VERSION ""

NS_ :

BS_:

BU_: PFAF_HS LVMPC_HS DCDC_HS AMP_HS VICM2_HS FICM_HS ARS_HS MCP_B_HS MCP_A_HS ICCM_OBD_HS SAS_HS ACCM_HS VLBS_HS EBCM_OBD_HS EDI_HS HPCC_HS VITM_OBD_HS PTAM_HS OBCM_HS VICM_HS HCP_HS FDCM_HS APPS_HS ICCM_HS EOCM_F_HS GPCM_HS FSCM_ITBC_HS SCM_HS ITBC_HS VCM_HS HMIM_HS FCP_HS VES_HS Dummy_HS MCP_C_HS RWS_HS ONSTAR_HS EPS_HS TestTool_HS MCP_HS BCP_HS ALC_HS AHL_AFL_HS SADS_HS EPB_HS FSCM_HS AFS_HS FCM_HS TCCM_HS RDCM_HS PTO_HS PCM_HS EBCM_HS ACC_HS BCM_HS TCM_HS ECM_HS

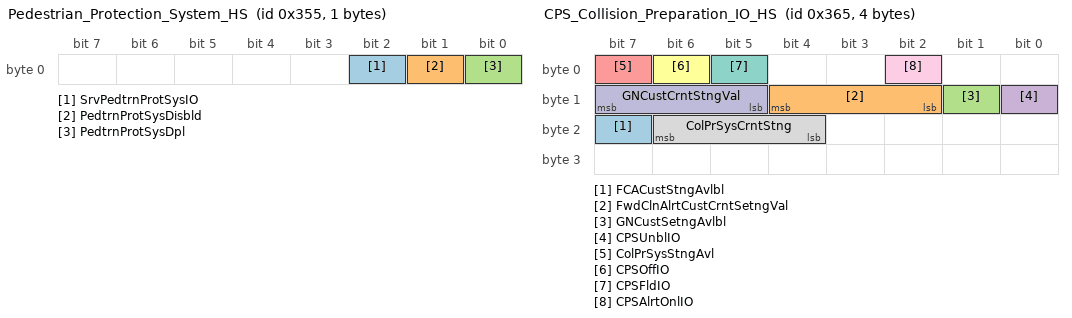
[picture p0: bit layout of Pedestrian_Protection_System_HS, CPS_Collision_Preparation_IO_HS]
BO_ 853 Pedestrian_Protection_System_HS: 1 APPS_HS
  SG_ SrvPedtrnProtSysIO: 2|1@0+ (1,0) [0|1] "" BCM_HS
  SG_ PedtrnProtSysDisbld: 1|1@0+ (1,0) [0|1] "" BCM_HS
  SG_ PedtrnProtSysDpl: 0|1@0+ (1,0) [0|1] "" BCM_HS

BO_ 869 CPS_Collision_Preparation_IO_HS: 4 EOCM_F_HS
  SG_ FCACustStngAvlbl: 23|1@0+ (1,0) [0|1] "" BCM_HS
  SG_ FwdClnAlrtCustCrntSetngVal: 12|3@0+ (1,0) [0|7] "" BCM_HS
  SG_ GNCustSetngAvlbl: 9|1@0+ (1,0) [0|1] "" BCM_HS
  SG_ CPSUnblIO: 8|1@0+ (1,0) [0|1] "" BCM_HS
  SG_ ColPrSysStngAvl: 7|1@0+ (1,0) [0|1] "" BCM_HS
  SG_ CPSOffIO: 6|1@0+ (1,0) [0|1] "" BCM_HS
  SG_ CPSFldIO: 5|1@0+ (1,0) [0|1] "" BCM_HS
  SG_ ColPrSysCrntStng: 22|3@0+ (1,0) [0|7] "" BCM_HS
  SG_ CPSAlrtOnlIO: 2|1@0+ (1,0) [0|1] "" BCM_HS
  SG_ GNCustCrntStngVal: 15|3@0+ (1,0) [0|7] "" BCM_HS

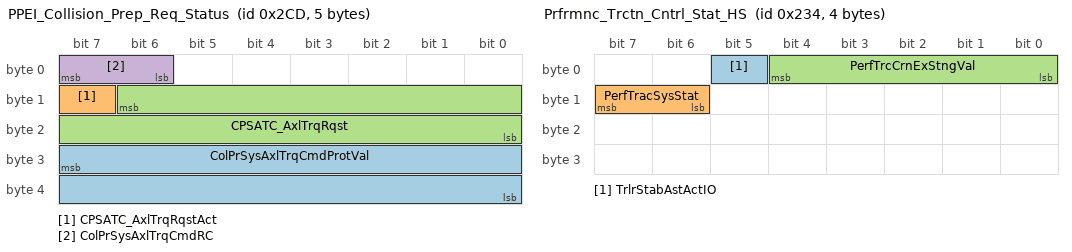
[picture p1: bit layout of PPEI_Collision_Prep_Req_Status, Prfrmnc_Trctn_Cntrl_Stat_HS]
BO_ 717 PPEI_Collision_Prep_Req_Status: 5 EOCM_F_HS
  SG_ ColPrSysAxlTrqCmdProtVal: 31|16@0+ (1,0) [0|65535] "" PCM_HS ECM_HS
  SG_ CPSATC_AxlTrqRqstAct: 15|1@0+ (1,0) [0|1] "" PCM_HS ECM_HS
  SG_ CPSATC_AxlTrqRqst: 14|15@0+ (2,-22534) [-22534|43000] "NM" PCM_HS ECM_HS
  SG_ ColPrSysAxlTrqCmdRC: 7|2@0+ (1,0) [0|3] "" PCM_HS ECM_HS

BO_ 568 A_12V_System_Status_HS: 1 VICM_HS
  SG_ a_12VSysVlt: 7|8@0+ (0.125,0) [0|31.874998] "volts" VICM2_HS ICCM_OBD_HS ICCM_HS FSCM_HS ACCM_HS

BO_ 564 Prfrmnc_Trctn_Cntrl_Stat_HS: 4 PTAM_HS
  SG_ TrlrStabAstActIO: 5|1@0+ (1,0) [0|1] "" BCM_HS
  SG_ PerfTracSysStat: 15|2@0+ (1,0) [0|3] "" EBCM_OBD_HS EBCM_HS
  SG_ PerfTrcCrnExStngVal: 4|5@0+ (1,0) [0|31] "" LVMPC_HS BCM_HS

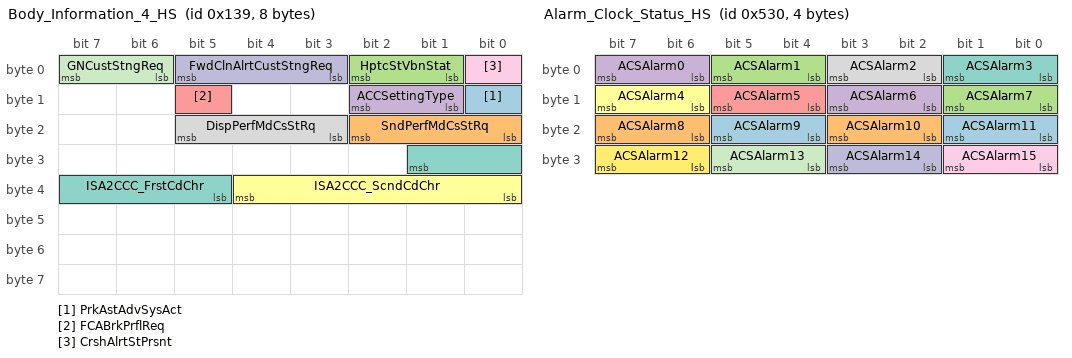
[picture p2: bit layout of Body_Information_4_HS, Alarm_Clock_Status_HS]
BO_ 313 Body_Information_4_HS: 8 BCM_HS
  SG_ PrkAstAdvSysAct: 8|1@0+ (1,0) [0|1] "" ACC_HS
  SG_ SndPerfMdCsStRq: 18|3@0+ (1,0) [0|7] "" EBCM_OBD_HS EBCM_HS
  SG_ HptcStVbnStat: 2|2@0+ (1,0) [0|3] "" ACC_HS
  SG_ ACCSettingType: 10|2@0+ (1,0) [0|3] "" ACC_HS
  SG_ FCABrkPrflReq: 13|1@0+ (1,0) [0|1] "" EBCM_OBD_HS EBCM_HS
  SG_ ISA2CCC_ScndCdChr: 36|5@0+ (1,0) [0|31] "" AHL_AFL_HS
  SG_ ISA2CCC_FrstCdChr: 25|5@0+ (1,0) [0|31] "" AHL_AFL_HS
  SG_ DispPerfMdCsStRq: 21|3@0+ (1,0) [0|7] "" EBCM_OBD_HS EBCM_HS
  SG_ CrshAlrtStPrsnt: 0|1@0+ (1,0) [0|1] "" EBCM_OBD_HS EBCM_HS ACC_HS
  SG_ FwdClnAlrtCustStngReq: 5|3@0+ (1,0) [0|7] "" EOCM_F_HS ACC_HS
  SG_ GNCustStngReq: 7|2@0+ (1,0) [0|3] "" EOCM_F_HS ACC_HS

BO_ 818 Front_Axle_General_Info_HS: 1 FDCM_HS
  SG_ FrntAxlTmpInhIO: 1|1@0+ (1,0) [0|1] "" BCM_HS
  SG_ FrAxlMalfIO: 0|1@0+ (1,0) [0|1] "" BCM_HS

BO_ 1328 Alarm_Clock_Status_HS: 4 BCM_HS
  SG_ ACSAlarm9: 21|2@0+ (1,0) [0|3] "" ICCM_OBD_HS ICCM_HS ALC_HS
  SG_ ACSAlarm8: 23|2@0+ (1,0) [0|3] "" ICCM_OBD_HS ICCM_HS ALC_HS
  SG_ ACSAlarm7: 9|2@0+ (1,0) [0|3] "" ICCM_OBD_HS ICCM_HS ALC_HS
  SG_ ACSAlarm6: 11|2@0+ (1,0) [0|3] "" ICCM_OBD_HS ICCM_HS ALC_HS
  SG_ ACSAlarm5: 13|2@0+ (1,0) [0|3] "" ICCM_OBD_HS ICCM_HS ALC_HS
  SG_ ACSAlarm4: 15|2@0+ (1,0) [0|3] "" ICCM_OBD_HS ICCM_HS ALC_HS
  SG_ ACSAlarm3: 1|2@0+ (1,0) [0|3] "" ICCM_OBD_HS ICCM_HS ALC_HS
  SG_ ACSAlarm2: 3|2@0+ (1,0) [0|3] "" ICCM_OBD_HS ICCM_HS ALC_HS
  SG_ ACSAlarm15: 25|2@0+ (1,0) [0|3] "" ICCM_OBD_HS ICCM_HS ALC_HS
  SG_ ACSAlarm14: 27|2@0+ (1,0) [0|3] "" ICCM_OBD_HS ICCM_HS ALC_HS
  SG_ ACSAlarm13: 29|2@0+ (1,0) [0|3] "" ICCM_OBD_HS ICCM_HS ALC_HS
  SG_ ACSAlarm12: 31|2@0+ (1,0) [0|3] "" ICCM_OBD_HS ICCM_HS ALC_HS
  SG_ ACSAlarm11: 17|2@0+ (1,0) [0|3] "" ICCM_OBD_HS ICCM_HS ALC_HS
  SG_ ACSAlarm10: 19|2@0+ (1,0) [0|3] "" ICCM_OBD_HS ICCM_HS ALC_HS
  SG_ ACSAlarm1: 5|2@0+ (1,0) [0|3] "" ICCM_OBD_HS ICCM_HS ALC_HS
  SG_ ACSAlarm0: 7|2@0+ (1,0) [0|3] "" ICCM_OBD_HS ICCM_HS ALC_HS

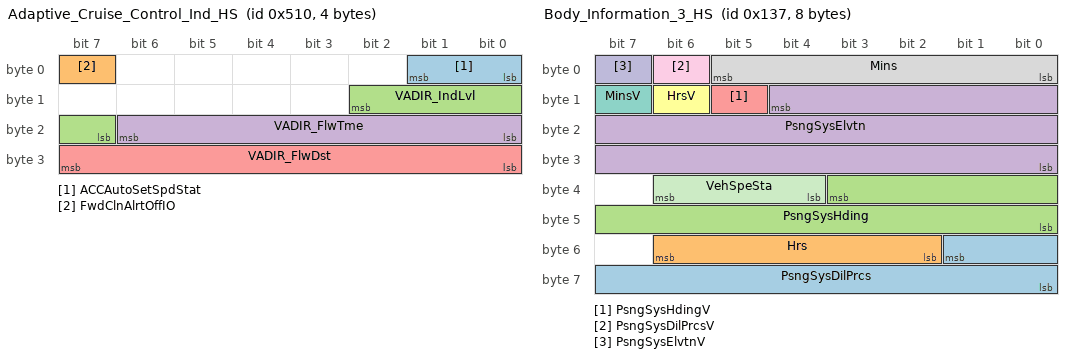
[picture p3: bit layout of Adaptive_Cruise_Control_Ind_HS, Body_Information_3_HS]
BO_ 1296 Adaptive_Cruise_Control_Ind_HS: 4 ACC_HS
  SG_ ACCAutoSetSpdStat: 1|2@0+ (1,0) [0|3] "" FCM_HS BCM_HS
  SG_ FwdClnAlrtOffIO: 7|1@0+ (1,0) [0|1] "" BCM_HS
  SG_ VADIR_IndLvl: 10|4@0+ (1,0) [0|15] "" BCM_HS
  SG_ VADIR_FlwTme: 22|7@0+ (0.1,0) [0|12.7] "s" BCM_HS
  SG_ VADIR_FlwDst: 31|8@0+ (1,0) [0|255] "m" BCM_HS

BO_ 311 Body_Information_3_HS: 8 BCM_HS
  SG_ PsngSysDilPrcs: 49|10@0+ (0.1,0) [0|102.3] "" ACC_HS
  SG_ Hrs: 54|5@0+ (1,0) [0|31] "h" ACC_HS
  SG_ PsngSysHding: 35|12@0+ (0.1,0) [0|409.5] "deg" ACC_HS
  SG_ PsngSysElvtn: 12|21@0+ (1,-100000) [-100000|1997151] "cm" ACC_HS
  SG_ PsngSysHdingV: 13|1@0+ (1,0) [0|1] "" ACC_HS
  SG_ HrsV: 14|1@0+ (1,0) [0|1] "" ACC_HS
  SG_ MinsV: 15|1@0+ (1,0) [0|1] "" ACC_HS
  SG_ Mins: 5|6@0+ (1,0) [0|63] "min" ACC_HS
  SG_ PsngSysDilPrcsV: 6|1@0+ (1,0) [0|1] "" ACC_HS
  SG_ PsngSysElvtnV: 7|1@0+ (1,0) [0|1] "" ACC_HS
  SG_ VehSpeSta: 38|3@0+ (1,0) [0|7] "" ACC_HS

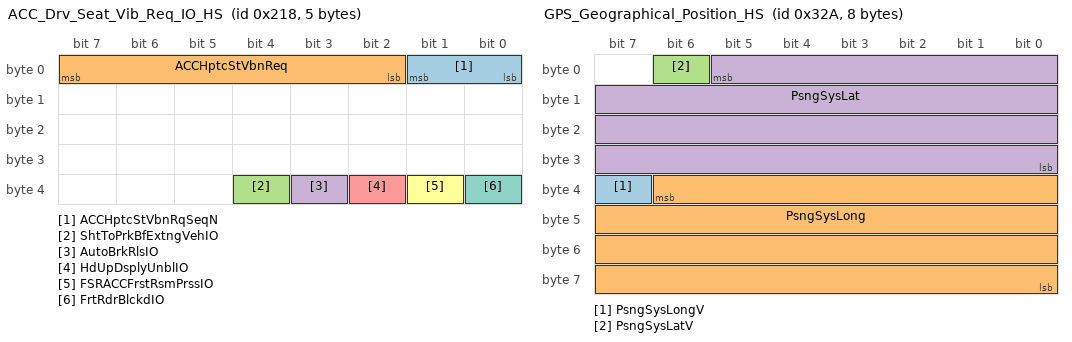
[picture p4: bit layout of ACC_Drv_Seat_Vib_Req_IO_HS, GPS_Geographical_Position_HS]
BO_ 536 ACC_Drv_Seat_Vib_Req_IO_HS: 5 ACC_HS
  SG_ ACCHptcStVbnRqSeqN: 1|2@0+ (1,0) [0|3] "" BCM_HS
  SG_ ACCHptcStVbnReq: 7|6@0+ (1,0) [0|63] "" BCM_HS
  SG_ ShtToPrkBfExtngVehIO: 36|1@0+ (1,0) [0|1] "" BCM_HS
  SG_ AutoBrkRlsIO: 35|1@0+ (1,0) [0|1] "" BCM_HS
  SG_ HdUpDsplyUnblIO: 34|1@0+ (1,0) [0|1] "" BCM_HS
  SG_ FSRACCFrstRsmPrssIO: 33|1@0+ (1,0) [0|1] "" BCM_HS
  SG_ FrtRdrBlckdIO: 32|1@0+ (1,0) [0|1] "" BCM_HS

BO_ 570 Fwd_Cln_Alrt_Drv_Seat_Vib_Req_HS: 1 ACC_HS
  SG_ FCAHptcStVbnRqSeqN: 1|2@0+ (1,0) [0|3] "" BCM_HS
  SG_ FCAHptcStVbnReq: 7|6@0+ (1,0) [0|63] "" BCM_HS

BO_ 810 GPS_Geographical_Position_HS: 8 BCM_HS
  SG_ PsngSysLongV: 39|1@0+ (1,0) [0|1] "" LVMPC_HS ACC_HS
  SG_ PsngSysLong: 38|31@0- (1,0) [-1.0737418e+09|1.0737418e+09] "ms arc" LVMPC_HS ACC_HS
  SG_ PsngSysLatV: 6|1@0+ (1,0) [0|1] "" LVMPC_HS ACC_HS
  SG_ PsngSysLat: 5|30@0- (1,0) [-5.3687091e+08|5.3687091e+08] "ms arc" LVMPC_HS ACC_HS

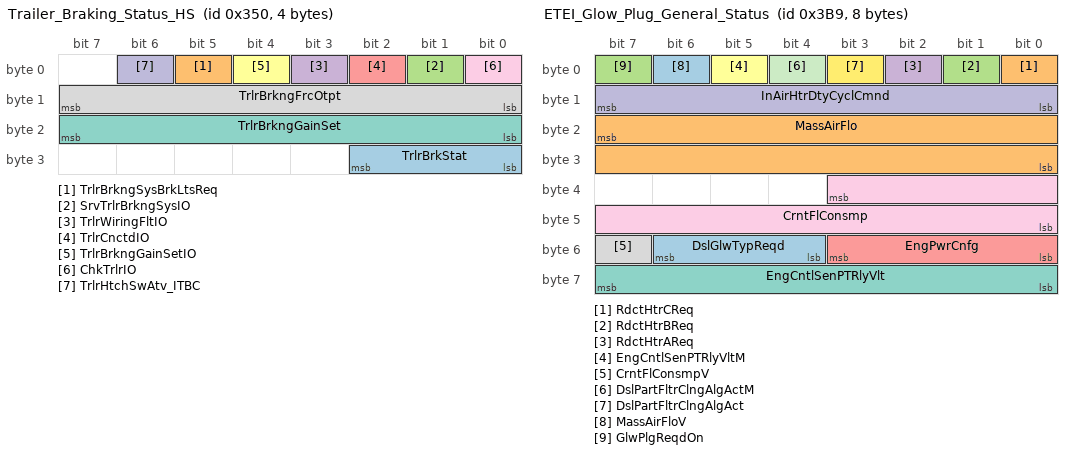
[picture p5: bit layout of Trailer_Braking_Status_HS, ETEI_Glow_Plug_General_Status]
BO_ 848 Trailer_Braking_Status_HS: 4 FSCM_ITBC_HS
  SG_ TrlrBrkStat: 26|3@0+ (1,0) [0|7] "" EBCM_OBD_HS EBCM_HS
  SG_ TrlrBrkngSysBrkLtsReq: 5|1@0+ (1,0) [0|1] "" BCM_HS
  SG_ SrvTrlrBrkngSysIO: 1|1@0+ (1,0) [0|1] "" BCM_HS
  SG_ TrlrWiringFltIO: 3|1@0+ (1,0) [0|1] "" BCM_HS
  SG_ TrlrCnctdIO: 2|1@0+ (1,0) [0|1] "" BCM_HS
  SG_ TrlrBrkngGainSetIO: 4|1@0+ (1,0) [0|1] "" BCM_HS
  SG_ TrlrBrkngGainSet: 23|8@0+ (0.39215702,0) [0|100.00004] "%" EBCM_OBD_HS EBCM_HS BCM_HS
  SG_ TrlrBrkngFrcOtpt: 15|8@0+ (0.39215702,0) [0|100.00004] "%" EBCM_OBD_HS EBCM_HS BCM_HS
  SG_ ChkTrlrIO: 0|1@0+ (1,0) [0|1] "" BCM_HS
  SG_ TrlrHtchSwAtv_ITBC: 6|1@0+ (1,0) [0|1] "" EOCM_F_HS ICCM_OBD_HS ICCM_HS ALC_HS SADS_HS BCM_HS

BO_ 953 ETEI_Glow_Plug_General_Status: 8 ECM_HS
  SG_ DslGlwTypReqd: 54|3@0+ (1,0) [0|7] "" GPCM_HS
  SG_ RdctHtrCReq: 0|1@0+ (1,0) [0|1] "" GPCM_HS
  SG_ RdctHtrBReq: 1|1@0+ (1,0) [0|1] "" GPCM_HS
  SG_ RdctHtrAReq: 2|1@0+ (1,0) [0|1] "" GPCM_HS
  SG_ EngPwrCnfg: 51|4@0+ (1,0) [0|15] "" GPCM_HS
  SG_ EngCntlSenPTRlyVltM: 5|1@0+ (1,0) [0|1] "" GPCM_HS
  SG_ EngCntlSenPTRlyVlt: 63|8@0+ (0.1,0) [0|25.5] "volts" GPCM_HS
  SG_ CrntFlConsmpV: 55|1@0+ (1,0) [0|1] "" GPCM_HS
  SG_ CrntFlConsmp: 35|12@0+ (0.050000004,0) [0|204.75] "mm3/stk" GPCM_HS
  SG_ InAirHtrDtyCyclCmnd: 15|8@0+ (0.39215702,0) [0|100.00004] "%" GPCM_HS
  SG_ DslPartFltrClngAlgActM: 4|1@0+ (1,0) [0|1] "" GPCM_HS
  SG_ DslPartFltrClngAlgAct: 3|1@0+ (1,0) [0|1] "" GPCM_HS
  SG_ MassAirFloV: 6|1@0+ (1,0) [0|1] "" GPCM_HS
  SG_ MassAirFlo: 23|16@0+ (0.010000001,0) [0|655.34998] "grams/s" GPCM_HS
  SG_ GlwPlgReqdOn: 7|1@0+ (1,0) [0|1] "" GPCM_HS

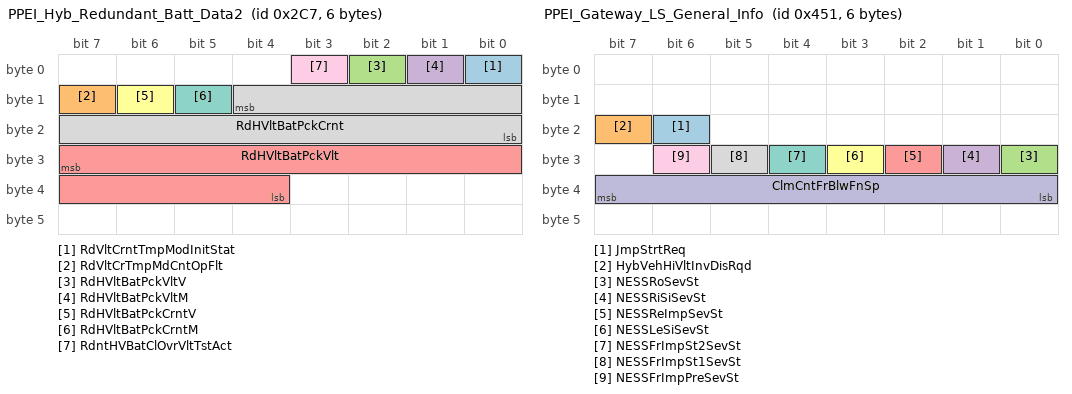
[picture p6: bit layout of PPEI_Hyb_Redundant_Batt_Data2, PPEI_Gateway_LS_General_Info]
BO_ 711 PPEI_Hyb_Redundant_Batt_Data2: 6 VITM_OBD_HS
  SG_ RdVltCrntTmpModInitStat: 0|1@0+ (1,0) [0|1] "" VICM_HS
  SG_ RdVltCrTmpMdCntOpFlt: 15|1@0+ (1,0) [0|1] "" VICM_HS
  SG_ RdHVltBatPckVltV: 2|1@0+ (1,0) [0|1] "" VICM_HS
  SG_ RdHVltBatPckVltM: 1|1@0+ (1,0) [0|1] "" VICM_HS
  SG_ RdHVltBatPckVlt: 31|12@0+ (0.125,0) [0|511.875] "V" VICM_HS
  SG_ RdHVltBatPckCrntV: 14|1@0+ (1,0) [0|1] "" VICM_HS
  SG_ RdHVltBatPckCrntM: 13|1@0+ (1,0) [0|1] "" VICM_HS
  SG_ RdHVltBatPckCrnt: 12|13@0- (0.15000001,0) [-614.40002|614.25] "A" VICM_HS
  SG_ RdntHVBatClOvrVltTstAct: 3|1@0+ (1,0) [0|1] "" VICM_HS

BO_ 1011 PPEI_Hybrid_General_Status_3: 2 BCP_HS

BO_ 304 Content_Theft_Sensor_Status_HS: 1 BCM_HS
  SG_ PedFrndlyAlrtCsStReq: 5|3@0+ (1,0) [0|7] "" PFAF_HS
  SG_ AlrmStat: 2|3@0+ (1,0) [0|7] "" VLBS_HS ICCM_OBD_HS ICCM_HS ALC_HS

BO_ 1105 PPEI_Gateway_LS_General_Info: 6 BCM_HS
  SG_ JmpStrtReq: 22|1@0+ (1,0) [0|1] "" BCP_HS
  SG_ HybVehHiVltInvDisRqd: 23|1@0+ (1,0) [0|1] "" BCP_HS
  SG_ NESSRoSevSt: 24|1@0+ (1,0) [0|1] "" ECM_HS BCP_HS
  SG_ NESSRiSiSevSt: 25|1@0+ (1,0) [0|1] "" ECM_HS BCP_HS
  SG_ NESSReImpSevSt: 26|1@0+ (1,0) [0|1] "" ECM_HS BCP_HS
  SG_ NESSLeSiSevSt: 27|1@0+ (1,0) [0|1] "" ECM_HS BCP_HS
  SG_ NESSFrImpSt2SevSt: 28|1@0+ (1,0) [0|1] "" ECM_HS BCP_HS
  SG_ NESSFrImpSt1SevSt: 29|1@0+ (1,0) [0|1] "" ECM_HS BCP_HS
  SG_ NESSFrImpPreSevSt: 30|1@0+ (1,0) [0|1] "" ECM_HS BCP_HS
  SG_ ClmCntFrBlwFnSp: 39|8@0+ (0.39215702,0) [0|100.00004] "%" EBCM_OBD_HS EBCM_HS BCP_HS

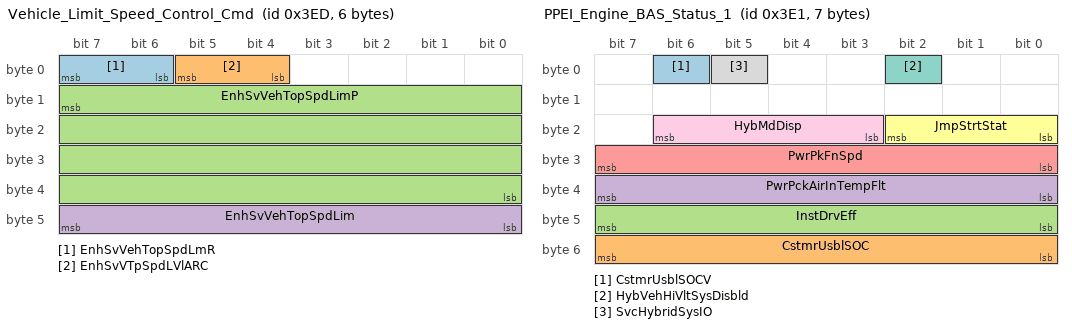
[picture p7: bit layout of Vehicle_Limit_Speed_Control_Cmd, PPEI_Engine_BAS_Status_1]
BO_ 1005 Vehicle_Limit_Speed_Control_Cmd: 6 ONSTAR_HS
  SG_ EnhSvVehTopSpdLmR: 7|2@0+ (1,0) [0|3] "" PCM_HS ECM_HS
  SG_ EnhSvVTpSpdLVlARC: 5|2@0+ (1,0) [0|3] "" PCM_HS ECM_HS
  SG_ EnhSvVehTopSpdLimP: 15|32@0+ (1,0) [0|-1] "" PCM_HS ECM_HS
  SG_ EnhSvVehTopSpdLim: 47|8@0+ (2,0) [0|510] "km / h" PCM_HS ECM_HS

BO_ 688 Starter_Generator_Status_3: 5 BCP_HS
  SG_ StrtrGenSpdV: 39|1@0+ (1,0) [0|1] "" PCM_HS ECM_HS EBCM_OBD_HS EBCM_HS
  SG_ StrtrGenSpd: 21|14@0+ (1,0) [0|16383] "rpm" PCM_HS ECM_HS EBCM_OBD_HS EBCM_HS

BO_ 993 PPEI_Engine_BAS_Status_1: 7 BCP_HS
  SG_ CstmrUsblSOCV: 6|1@0+ (1,0) [0|1] "" BCM_HS
  SG_ CstmrUsblSOC: 55|8@0+ (0.39216,0) [0|100.0008] "%" BCM_HS
  SG_ InstDrvEff: 47|8@0- (0.78740001,0) [-100.7872|99.999802] "%" BCM_HS
  SG_ PwrPckAirInTempFlt: 39|8@0+ (1,-40) [-40|215] "deg C" BCM_HS
  SG_ PwrPkFnSpd: 31|8@0+ (0.39215702,0) [0|100.00004] "%" BCM_HS
  SG_ JmpStrtStat: 18|3@0+ (1,0) [0|7] "" BCM_HS
  SG_ HybVehHiVltSysDisbld: 2|1@0+ (1,0) [0|1] "" FCP_HS ONSTAR_HS
  SG_ SvcHybridSysIO: 5|1@0+ (1,0) [0|1] "" BCM_HS
  SG_ HybMdDisp: 22|4@0+ (1,0) [0|15] "" BCM_HS

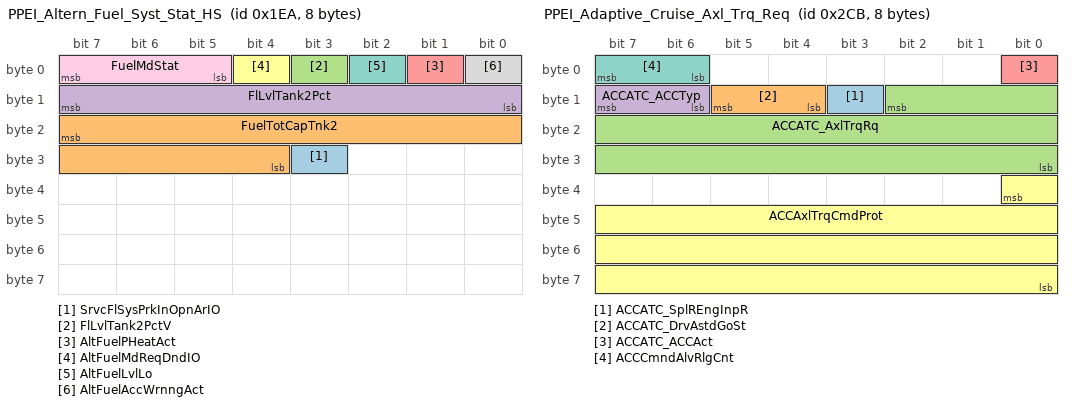
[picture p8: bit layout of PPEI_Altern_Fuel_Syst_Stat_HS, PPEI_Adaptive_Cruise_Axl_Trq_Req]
BO_ 490 PPEI_Altern_Fuel_Syst_Stat_HS: 8 ECM_HS
  SG_ SrvcFlSysPrkInOpnArIO: 27|1@0+ (1,0) [0|1] "" BCM_HS
  SG_ FuelTotCapTnk2: 23|12@0+ (0.125,0) [0|511.875] "liters" BCM_HS
  SG_ FlLvlTank2PctV: 3|1@0+ (1,0) [0|1] "" BCM_HS
  SG_ FlLvlTank2Pct: 15|8@0+ (0.39215702,0) [0|100.00004] "%" BCM_HS
  SG_ AltFuelPHeatAct: 1|1@0+ (1,0) [0|1] "" ECM_HS BCM_HS
  SG_ AltFuelMdReqDndIO: 4|1@0+ (1,0) [0|1] "" BCM_HS
  SG_ AltFuelLvlLo: 2|1@0+ (1,0) [0|1] "" BCM_HS ECM_HS
  SG_ AltFuelAccWrnngAct: 0|1@0+ (1,0) [0|1] "" BCM_HS
  SG_ FuelMdStat: 7|3@0+ (1,0) [0|7] "" ECM_HS BCM_HS

BO_ 431 PTEI_Trans_General_Status_2: 8 TCM_HS
  SG_ TransVehTopSpdLim: 63|8@0+ (2,0) [0|510] "km / h" PCM_HS ECM_HS
  SG_ TransMinVoltReq: 55|8@0+ (0.078430012,0) [0|19.999651] "volts" PCM_HS ECM_HS
  SG_ TDslPrtFltrIdlRgtnMdAtv: 6|1@0+ (1,0) [0|1] "" PCM_HS ECM_HS
  SG_ DrvlneTrqStabStat: 38|3@0+ (1,0) [0|7] "" PCM_HS ECM_HS
  SG_ TrnsTrqCnvCltCmdMdF: 19|1@0+ (1,0) [0|1] "" PCM_HS ECM_HS
  SG_ AutoTransGrSftDirectFl: 16|1@0+ (1,0) [0|1] "" PCM_HS ECM_HS
  SG_ AutoTransGrSftDirect: 18|2@0+ (1,0) [0|3] "" PCM_HS ECM_HS
  SG_ TrnsTrqCnvCltCmndMd: 22|3@0+ (1,0) [0|7] "" PCM_HS ECM_HS
  SG_ TrnsTrqCnvCltDsrSlp: 35|12@0- (1,0) [-2048|2047] "rpm" PCM_HS ECM_HS
  SG_ TrnsStWntrMdOvrd: 25|2@0+ (1,0) [0|3] "" PCM_HS ECM_HS
  SG_ TrnsStTwHaulMdOvrd: 27|2@0+ (1,0) [0|3] "" PCM_HS ECM_HS
  SG_ TrnsStSprtMdOvrd: 29|2@0+ (1,0) [0|3] "" PCM_HS ECM_HS
  SG_ TrnsStEconMdOvrd: 31|2@0+ (1,0) [0|3] "" PCM_HS ECM_HS
  SG_ TrnsInpCltchStat: 2|3@0+ (1,0) [0|7] "" PCM_HS ECM_HS
  SG_ TrnsAntcptdCrpTrqRRnV: 7|1@0+ (1,0) [0|1] "" PCM_HS ECM_HS
  SG_ TrnsAntcptdCrpTrqRRn: 15|8@0+ (0.5,0) [0|127.5] "Nm" PCM_HS ECM_HS
  SG_ TrnCltAdpAtv: 3|1@0+ (1,0) [0|1] "" PCM_HS ECM_HS
  SG_ TransCrnkPermsnStat: 5|1@0+ (1,0) [0|1] "" PCM_HS ECM_HS
  SG_ WrmUpShftPtrn: 4|1@0+ (1,0) [0|1] "" PCM_HS ECM_HS

BO_ 715 PPEI_Adaptive_Cruise_Axl_Trq_Req: 8 ACC_HS
  SG_ ACCATC_SplREngInpR: 11|1@0+ (1,0) [0|1] "" PCM_HS ECM_HS
  SG_ ACCATC_DrvAstdGoSt: 13|2@0+ (1,0) [0|3] "" PCM_HS ECM_HS
  SG_ ACCATC_AxlTrqRq: 10|19@0+ (0.125,-22534) [-22534|43001.875] "Nm" PCM_HS ECM_HS
  SG_ ACCATC_ACCTyp: 15|2@0+ (1,0) [0|3] "" PCM_HS ECM_HS
  SG_ ACCATC_ACCAct: 0|1@0+ (1,0) [0|1] "" PCM_HS ECM_HS
  SG_ ACCAxlTrqCmdProt: 32|25@0+ (1,0) [0|33554432] "" PCM_HS ECM_HS
  SG_ ACCCmndAlvRlgCnt: 7|2@0+ (1,0) [0|3] "" PCM_HS ECM_HS

BO_ 1267 PPEI_Powertrain_Config_Data_2: 1 ECM_HS
  SG_ VehMassNom: 7|8@0+ (20,500) [500|5600] "kg" EOCM_F_HS ACC_HS

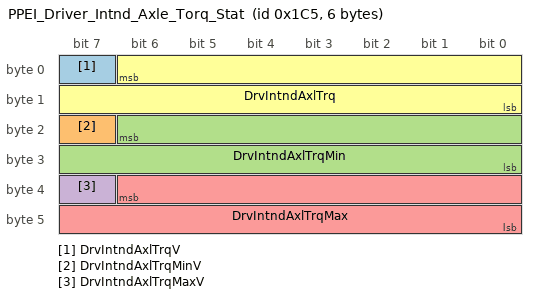
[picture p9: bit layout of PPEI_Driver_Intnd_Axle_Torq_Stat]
BO_ 453 PPEI_Driver_Intnd_Axle_Torq_Stat: 6 ECM_HS
  SG_ DrvIntndAxlTrqV: 7|1@0+ (1,0) [0|1] "" ICCM_OBD_HS ICCM_HS EBCM_OBD_HS EBCM_HS VICM_HS HCP_HS EOCM_F_HS ACC_HS
  SG_ DrvIntndAxlTrqMinV: 23|1@0+ (1,0) [0|1] "" EOCM_F_HS ACC_HS
  SG_ DrvIntndAxlTrqMin: 22|15@0+ (2,-22534) [-22534|43000] "Nm" EOCM_F_HS ACC_HS
  SG_ DrvIntndAxlTrqMaxV: 39|1@0+ (1,0) [0|1] "" EOCM_F_HS ACC_HS
  SG_ DrvIntndAxlTrqMax: 38|15@0+ (2,-22534) [-22534|43000] "Nm" EOCM_F_HS ACC_HS
  SG_ DrvIntndAxlTrq: 6|15@0+ (2,-22534) [-22534|43000] "Nm" ICCM_OBD_HS ICCM_HS EBCM_OBD_HS EBCM_HS VICM_HS HCP_HS EOCM_F_HS ACC_HS

BO_ 452 PPEI_Torque_Request_Status: 8 ECM_HS
  SG_ FSpRgACCSwADdPVal: 50|2@0+ (1,0) [0|3] "" EBCM_OBD_HS EBCM_HS
  SG_ FSpRgACCSwADdARC: 6|2@0+ (1,0) [0|3] "" EBCM_OBD_HS EBCM_HS
  SG_ FSpRgACCSwADd: 7|1@0+ (1,0) [0|1] "" EBCM_OBD_HS EBCM_HS ACC_HS
  SG_ AutBrkAccActPsStRC: 34|2@0+ (1,0) [0|3] "" EOCM_F_HS ACC_HS EBCM_OBD_HS EBCM_HS
  SG_ AutBrkAccActPsStPVal: 48|9@0+ (1,0) [0|511] "" EOCM_F_HS ACC_HS EBCM_OBD_HS EBCM_HS
  SG_ ABAAPS_AccPos: 47|8@0+ (0.39215702,0) [0|100.00004] "%" EBCM_OBD_HS EBCM_HS ACC_HS EOCM_F_HS
  SG_ ABAAPS_AccPosV: 32|1@0+ (1,0) [0|1] "" EBCM_OBD_HS EBCM_HS ACC_HS EOCM_F_HS
  SG_ ACCATCS_LmtgStat: 12|2@0+ (1,0) [0|3] "" EOCM_F_HS ACC_HS
  SG_ ACCATCS_RqStat: 15|3@0+ (1,0) [0|7] "" EOCM_F_HS ACC_HS
  SG_ RdLdNomAxlTrq: 10|19@0+ (0.125,-22534) [-22534|43001.875] "Nm" EOCM_F_HS ACC_HS
  SG_ AccPdlOvrrdAtvProtVal: 1|2@0+ (1,0) [0|3] "" EOCM_F_HS EBCM_OBD_HS EBCM_HS ACC_HS PTO_HS
  SG_ AccPdlOvrrdAtvARC: 3|2@0+ (1,0) [0|3] "" EOCM_F_HS EBCM_OBD_HS EBCM_HS ACC_HS PTO_HS
  SG_ AccPdlOvrrdAtv: 4|1@0+ (1,0) [0|1] "" BCM_HS EOCM_F_HS EBCM_OBD_HS EBCM_HS ACC_HS PTO_HS
  SG_ CPSATCS_ReqStatus: 37|3@0+ (1,0) [0|7] "" ACC_HS EOCM_F_HS
  SG_ CPSATCS_LmtngStatus: 39|2@0+ (1,0) [0|3] "" ACC_HS EOCM_F_HS
  SG_ RVBATCS_ReqStat: 53|3@0+ (1,0) [0|7] "" EOCM_F_HS
  SG_ RVBATCS_LmtngStat: 55|2@0+ (1,0) [0|3] "" EOCM_F_HS

BO_ 1905 DTC_Triggered_771: 7 FDCM_HS
  SG_ DTCI_DTCFaultType_771: 55|8@0+ (1,0) [0|255] "" HMIM_HS FCP_HS ONSTAR_HS
  SG_ DTCI_CodeSupported_771: 40|1@0+ (1,0) [0|1] "" HMIM_HS FCP_HS ONSTAR_HS
  SG_ DTCI_CurrentStatus_771: 41|1@0+ (1,0) [0|1] "" HMIM_HS FCP_HS ONSTAR_HS
  SG_ DTCI_TstNPsdCdClrdSt_771: 42|1@0+ (1,0) [0|1] "" HMIM_HS FCP_HS ONSTAR_HS
  SG_ DTCI_TstFldCdClrdStat_771: 43|1@0+ (1,0) [0|1] "" HMIM_HS FCP_HS ONSTAR_HS
  SG_ DTCI_HistStat_771: 44|1@0+ (1,0) [0|1] "" HMIM_HS FCP_HS ONSTAR_HS
  SG_ DTCI_TstNPsdPwrUpSt_771: 45|1@0+ (1,0) [0|1] "" HMIM_HS FCP_HS ONSTAR_HS
  SG_ DTCI_TstFldPwrUpSt_771: 46|1@0+ (1,0) [0|1] "" HMIM_HS FCP_HS ONSTAR_HS
  SG_ DTCI_WrnIndRqdSt_771: 47|1@0+ (1,0) [0|1] "" HMIM_HS FCP_HS ONSTAR_HS
  SG_ DTCI_DTCFailType_771: 39|8@0+ (1,0) [0|255] "" HMIM_HS FCP_HS ONSTAR_HS
  SG_ DTCI_DTCNumber_771: 23|16@0+ (1,0) [0|65535] "" HMIM_HS FCP_HS ONSTAR_HS
  SG_ DTCI_DTCSource_771: 15|8@0+ (1,0) [0|255] "" HMIM_HS FCP_HS ONSTAR_HS
  SG_ DTCI_DTCTriggered_771: 0|1@0+ (1,0) [0|1] "" HMIM_HS FCP_HS ONSTAR_HS
  SG_ DTCIUnused7_771: 1|1@0+ (1,0) [0|1] "" HMIM_HS FCP_HS ONSTAR_HS
  SG_ DTCIUnused6_771: 2|1@0+ (1,0) [0|1] "" HMIM_HS FCP_HS ONSTAR_HS
  SG_ DTCIUnused5_771: 3|1@0+ (1,0) [0|1] "" HMIM_HS FCP_HS ONSTAR_HS
  SG_ DTCIUnused4_771: 4|1@0+ (1,0) [0|1] "" HMIM_HS FCP_HS ONSTAR_HS
  SG_ DTCIUnused3_771: 5|1@0+ (1,0) [0|1] "" HMIM_HS FCP_HS ONSTAR_HS
  SG_ DTCIUnused2_771: 6|1@0+ (1,0) [0|1] "" HMIM_HS FCP_HS ONSTAR_HS
  SG_ DTCIUnused1_771: 7|1@0+ (1,0) [0|1] "" HMIM_HS FCP_HS ONSTAR_HS

BO_ 1935 DTC_Triggered_78F: 7 Dummy_HS
  SG_ DTCI_DTCSource_78F: 15|8@0+ (1,0) [0|255] "" HMIM_HS FCP_HS ONSTAR_HS
  SG_ DTCI_DTCTriggered_78F: 0|1@0+ (1,0) [0|1] "" HMIM_HS FCP_HS ONSTAR_HS
  SG_ DTCIUnused1_78F: 7|1@0+ (1,0) [0|1] "" HMIM_HS FCP_HS ONSTAR_HS
  SG_ DTCIUnused2_78F: 6|1@0+ (1,0) [0|1] "" HMIM_HS FCP_HS ONSTAR_HS
  SG_ DTCIUnused3_78F: 5|1@0+ (1,0) [0|1] "" HMIM_HS FCP_HS ONSTAR_HS
  SG_ DTCIUnused4_78F: 4|1@0+ (1,0) [0|1] "" HMIM_HS FCP_HS ONSTAR_HS
  SG_ DTCIUnused5_78F: 3|1@0+ (1,0) [0|1] "" HMIM_HS FCP_HS ONSTAR_HS
  SG_ DTCIUnused6_78F: 2|1@0+ (1,0) [0|1] "" HMIM_HS FCP_HS ONSTAR_HS
  SG_ DTCIUnused7_78F: 1|1@0+ (1,0) [0|1] "" HMIM_HS FCP_HS ONSTAR_HS
  SG_ DTCI_CodeSupported_78F: 40|1@0+ (1,0) [0|1] "" HMIM_HS FCP_HS ONSTAR_HS
  SG_ DTCI_CurrentStatus_78F: 41|1@0+ (1,0) [0|1] "" HMIM_HS FCP_HS ONSTAR_HS
  SG_ DTCI_DTCFaultType_78F: 55|8@0+ (1,0) [0|255] "" HMIM_HS FCP_HS ONSTAR_HS
  SG_ DTCI_TstFldCdClrdStat_78F: 43|1@0+ (1,0) [0|1] "" HMIM_HS FCP_HS ONSTAR_HS
  SG_ DTCI_TstNPsdCdClrdSt_78F: 42|1@0+ (1,0) [0|1] "" HMIM_HS FCP_HS ONSTAR_HS
  SG_ DTCI_HistStat_78F: 44|1@0+ (1,0) [0|1] "" HMIM_HS FCP_HS ONSTAR_HS
  SG_ DTCI_TstNPsdPwrUpSt_78F: 45|1@0+ (1,0) [0|1] "" HMIM_HS FCP_HS ONSTAR_HS
  SG_ DTCI_TstFldPwrUpSt_78F: 46|1@0+ (1,0) [0|1] "" HMIM_HS FCP_HS ONSTAR_HS
  SG_ DTCI_WrnIndRqdSt_78F: 47|1@0+ (1,0) [0|1] "" HMIM_HS FCP_HS ONSTAR_HS
  SG_ DTCI_DTCFailType_78F: 39|8@0+ (1,0) [0|255] "" HMIM_HS FCP_HS ONSTAR_HS
  SG_ DTCI_DTCNumber_78F: 23|16@0+ (1,0) [0|65535] "" HMIM_HS FCP_HS ONSTAR_HS

BO_ 1934 DTC_Triggered_78E: 7 Dummy_HS
  SG_ DTCI_CodeSupported_78E: 40|1@0+ (1,0) [0|1] "" HMIM_HS FCP_HS ONSTAR_HS
  SG_ DTCI_CurrentStatus_78E: 41|1@0+ (1,0) [0|1] "" HMIM_HS FCP_HS ONSTAR_HS
  SG_ DTCI_DTCFailType_78E: 39|8@0+ (1,0) [0|255] "" HMIM_HS FCP_HS ONSTAR_HS
  SG_ DTCI_DTCFaultType_78E: 55|8@0+ (1,0) [0|255] "" HMIM_HS FCP_HS ONSTAR_HS
  SG_ DTCI_DTCNumber_78E: 23|16@0+ (1,0) [0|65535] "" HMIM_HS FCP_HS ONSTAR_HS
  SG_ DTCI_DTCSource_78E: 15|8@0+ (1,0) [0|255] "" HMIM_HS FCP_HS ONSTAR_HS
  SG_ DTCI_DTCTriggered_78E: 0|1@0+ (1,0) [0|1] "" HMIM_HS FCP_HS ONSTAR_HS
  SG_ DTCI_HistStat_78E: 44|1@0+ (1,0) [0|1] "" HMIM_HS FCP_HS ONSTAR_HS
  SG_ DTCI_TstFldCdClrdStat_78E: 43|1@0+ (1,0) [0|1] "" HMIM_HS FCP_HS ONSTAR_HS
  SG_ DTCI_TstFldPwrUpSt_78E: 46|1@0+ (1,0) [0|1] "" HMIM_HS FCP_HS ONSTAR_HS
  SG_ DTCI_TstNPsdCdClrdSt_78E: 42|1@0+ (1,0) [0|1] "" HMIM_HS FCP_HS ONSTAR_HS
  SG_ DTCI_TstNPsdPwrUpSt_78E: 45|1@0+ (1,0) [0|1] "" HMIM_HS FCP_HS ONSTAR_HS
  SG_ DTCIUnused1_78E: 7|1@0+ (1,0) [0|1] "" HMIM_HS FCP_HS ONSTAR_HS
  SG_ DTCIUnused2_78E: 6|1@0+ (1,0) [0|1] "" HMIM_HS FCP_HS ONSTAR_HS
  SG_ DTCIUnused3_78E: 5|1@0+ (1,0) [0|1] "" HMIM_HS FCP_HS ONSTAR_HS
  SG_ DTCIUnused4_78E: 4|1@0+ (1,0) [0|1] "" HMIM_HS FCP_HS ONSTAR_HS
  SG_ DTCIUnused5_78E: 3|1@0+ (1,0) [0|1] "" HMIM_HS FCP_HS ONSTAR_HS
  SG_ DTCIUnused6_78E: 2|1@0+ (1,0) [0|1] "" HMIM_HS FCP_HS ONSTAR_HS
  SG_ DTCIUnused7_78E: 1|1@0+ (1,0) [0|1] "" HMIM_HS FCP_HS ONSTAR_HS
  SG_ DTCI_WrnIndRqdSt_78E: 47|1@0+ (1,0) [0|1] "" HMIM_HS FCP_HS ONSTAR_HS

BO_ 1933 DTC_Triggered_78D: 7 Dummy_HS
  SG_ DTCI_CodeSupported_78D: 40|1@0+ (1,0) [0|1] "" HMIM_HS FCP_HS ONSTAR_HS
  SG_ DTCI_CurrentStatus_78D: 41|1@0+ (1,0) [0|1] "" HMIM_HS FCP_HS ONSTAR_HS
  SG_ DTCI_DTCFailType_78D: 39|8@0+ (1,0) [0|255] "" HMIM_HS FCP_HS ONSTAR_HS
  SG_ DTCI_DTCFaultType_78D: 55|8@0+ (1,0) [0|255] "" HMIM_HS FCP_HS ONSTAR_HS
  SG_ DTCI_DTCNumber_78D: 23|16@0+ (1,0) [0|65535] "" HMIM_HS FCP_HS ONSTAR_HS
  SG_ DTCI_DTCSource_78D: 15|8@0+ (1,0) [0|255] "" HMIM_HS FCP_HS ONSTAR_HS
  SG_ DTCI_DTCTriggered_78D: 0|1@0+ (1,0) [0|1] "" HMIM_HS FCP_HS ONSTAR_HS
  SG_ DTCI_HistStat_78D: 44|1@0+ (1,0) [0|1] "" HMIM_HS FCP_HS ONSTAR_HS
  SG_ DTCI_TstFldCdClrdStat_78D: 43|1@0+ (1,0) [0|1] "" HMIM_HS FCP_HS ONSTAR_HS
  SG_ DTCI_TstFldPwrUpSt_78D: 46|1@0+ (1,0) [0|1] "" HMIM_HS FCP_HS ONSTAR_HS
  SG_ DTCI_TstNPsdCdClrdSt_78D: 42|1@0+ (1,0) [0|1] "" HMIM_HS FCP_HS ONSTAR_HS
  SG_ DTCI_TstNPsdPwrUpSt_78D: 45|1@0+ (1,0) [0|1] "" HMIM_HS FCP_HS ONSTAR_HS
  SG_ DTCIUnused1_78D: 7|1@0+ (1,0) [0|1] "" HMIM_HS FCP_HS ONSTAR_HS
  SG_ DTCIUnused2_78D: 6|1@0+ (1,0) [0|1] "" HMIM_HS FCP_HS ONSTAR_HS
  SG_ DTCIUnused3_78D: 5|1@0+ (1,0) [0|1] "" HMIM_HS FCP_HS ONSTAR_HS
  SG_ DTCIUnused4_78D: 4|1@0+ (1,0) [0|1] "" HMIM_HS FCP_HS ONSTAR_HS
  SG_ DTCIUnused5_78D: 3|1@0+ (1,0) [0|1] "" HMIM_HS FCP_HS ONSTAR_HS
  SG_ DTCIUnused6_78D: 2|1@0+ (1,0) [0|1] "" HMIM_HS FCP_HS ONSTAR_HS
  SG_ DTCIUnused7_78D: 1|1@0+ (1,0) [0|1] "" HMIM_HS FCP_HS ONSTAR_HS
  SG_ DTCI_WrnIndRqdSt_78D: 47|1@0+ (1,0) [0|1] "" HMIM_HS FCP_HS ONSTAR_HS

BO_ 1932 DTC_Triggered_78C: 7 Dummy_HS
  SG_ DTCI_CodeSupported_78C: 40|1@0+ (1,0) [0|1] "" HMIM_HS FCP_HS ONSTAR_HS
  SG_ DTCI_CurrentStatus_78C: 41|1@0+ (1,0) [0|1] "" HMIM_HS FCP_HS ONSTAR_HS
  SG_ DTCI_DTCFailType_78C: 39|8@0+ (1,0) [0|255] "" HMIM_HS FCP_HS ONSTAR_HS
  SG_ DTCI_DTCFaultType_78C: 55|8@0+ (1,0) [0|255] "" HMIM_HS FCP_HS ONSTAR_HS
  SG_ DTCI_DTCNumber_78C: 23|16@0+ (1,0) [0|65535] "" HMIM_HS FCP_HS ONSTAR_HS
  SG_ DTCI_DTCSource_78C: 15|8@0+ (1,0) [0|255] "" HMIM_HS FCP_HS ONSTAR_HS
  SG_ DTCI_DTCTriggered_78C: 0|1@0+ (1,0) [0|1] "" HMIM_HS FCP_HS ONSTAR_HS
  SG_ DTCI_HistStat_78C: 44|1@0+ (1,0) [0|1] "" HMIM_HS FCP_HS ONSTAR_HS
  SG_ DTCI_TstFldCdClrdStat_78C: 43|1@0+ (1,0) [0|1] "" HMIM_HS FCP_HS ONSTAR_HS
  SG_ DTCI_TstFldPwrUpSt_78C: 45|1@0+ (1,0) [0|1] "" HMIM_HS FCP_HS ONSTAR_HS
  SG_ DTCI_TstNPsdCdClrdSt_78C: 42|1@0+ (1,0) [0|1] "" HMIM_HS FCP_HS ONSTAR_HS
  SG_ DTCI_TstNPsdPwrUpSt_78C: 46|1@0+ (1,0) [0|1] "" HMIM_HS FCP_HS ONSTAR_HS
  SG_ DTCIUnused1_78C: 7|1@0+ (1,0) [0|1] "" HMIM_HS FCP_HS ONSTAR_HS
  SG_ DTCIUnused2_78C: 6|1@0+ (1,0) [0|1] "" HMIM_HS FCP_HS ONSTAR_HS
  SG_ DTCIUnused3_78C: 5|1@0+ (1,0) [0|1] "" HMIM_HS FCP_HS ONSTAR_HS
  SG_ DTCIUnused4_78C: 4|1@0+ (1,0) [0|1] "" HMIM_HS FCP_HS ONSTAR_HS
  SG_ DTCIUnused5_78C: 3|1@0+ (1,0) [0|1] "" HMIM_HS FCP_HS ONSTAR_HS
  SG_ DTCIUnused6_78C: 2|1@0+ (1,0) [0|1] "" HMIM_HS FCP_HS ONSTAR_HS
  SG_ DTCIUnused7_78C: 1|1@0+ (1,0) [0|1] "" HMIM_HS FCP_HS ONSTAR_HS
  SG_ DTCI_WrnIndRqdSt_78C: 47|1@0+ (1,0) [0|1] "" HMIM_HS FCP_HS ONSTAR_HS

BO_ 1931 DTC_Triggered_78B: 7 Dummy_HS
  SG_ DTCI_CodeSupported_78B: 40|1@0+ (1,0) [0|1] "" HMIM_HS FCP_HS ONSTAR_HS
  SG_ DTCI_CurrentStatus_78B: 41|1@0+ (1,0) [0|1] "" HMIM_HS FCP_HS ONSTAR_HS
  SG_ DTCI_DTCFailType_78B: 39|8@0+ (1,0) [0|255] "" HMIM_HS FCP_HS ONSTAR_HS
  SG_ DTCI_DTCFaultType_78B: 55|8@0+ (1,0) [0|255] "" HMIM_HS FCP_HS ONSTAR_HS
  SG_ DTCI_DTCNumber_78B: 23|16@0+ (1,0) [0|65535] "" HMIM_HS FCP_HS ONSTAR_HS
  SG_ DTCI_DTCSource_78B: 15|8@0+ (1,0) [0|255] "" HMIM_HS FCP_HS ONSTAR_HS
  SG_ DTCI_DTCTriggered_78B: 0|1@0+ (1,0) [0|1] "" HMIM_HS FCP_HS ONSTAR_HS
  SG_ DTCI_HistStat_78B: 44|1@0+ (1,0) [0|1] "" HMIM_HS FCP_HS ONSTAR_HS
  SG_ DTCI_TstFldCdClrdStat_78B: 43|1@0+ (1,0) [0|1] "" HMIM_HS FCP_HS ONSTAR_HS
  SG_ DTCI_TstFldPwrUpSt_78B: 46|1@0+ (1,0) [0|1] "" HMIM_HS FCP_HS ONSTAR_HS
  SG_ DTCI_TstNPsdCdClrdSt_78B: 42|1@0+ (1,0) [0|1] "" HMIM_HS FCP_HS ONSTAR_HS
  SG_ DTCI_TstNPsdPwrUpSt_78B: 45|1@0+ (1,0) [0|1] "" HMIM_HS FCP_HS ONSTAR_HS
  SG_ DTCIUnused1_78B: 7|1@0+ (1,0) [0|1] "" HMIM_HS FCP_HS ONSTAR_HS
  SG_ DTCIUnused2_78B: 6|1@0+ (1,0) [0|1] "" HMIM_HS FCP_HS ONSTAR_HS
  SG_ DTCIUnused3_78B: 5|1@0+ (1,0) [0|1] "" HMIM_HS FCP_HS ONSTAR_HS
  SG_ DTCIUnused4_78B: 4|1@0+ (1,0) [0|1] "" HMIM_HS FCP_HS ONSTAR_HS
  SG_ DTCIUnused5_78B: 3|1@0+ (1,0) [0|1] "" HMIM_HS FCP_HS ONSTAR_HS
  SG_ DTCIUnused6_78B: 2|1@0+ (1,0) [0|1] "" HMIM_HS FCP_HS ONSTAR_HS
  SG_ DTCIUnused7_78B: 1|1@0+ (1,0) [0|1] "" HMIM_HS FCP_HS ONSTAR_HS
  SG_ DTCI_WrnIndRqdSt_78B: 47|1@0+ (1,0) [0|1] "" HMIM_HS FCP_HS ONSTAR_HS

BO_ 1930 DTC_Triggered_78A: 7 EOCM_F_HS
  SG_ DTCI_CodeSupported_78A: 40|1@0+ (1,0) [0|1] "" HMIM_HS FCP_HS ONSTAR_HS
  SG_ DTCI_CurrentStatus_78A: 41|1@0+ (1,0) [0|1] "" HMIM_HS FCP_HS ONSTAR_HS
  SG_ DTCI_DTCFailType_78A: 39|8@0+ (1,0) [0|255] "" HMIM_HS FCP_HS ONSTAR_HS
  SG_ DTCI_DTCFaultType_78A: 55|8@0+ (1,0) [0|255] "" HMIM_HS FCP_HS ONSTAR_HS
  SG_ DTCI_DTCNumber_78A: 23|16@0+ (1,0) [0|65535] "" HMIM_HS FCP_HS ONSTAR_HS
  SG_ DTCI_DTCSource_78A: 15|8@0+ (1,0) [0|255] "" HMIM_HS FCP_HS ONSTAR_HS
  SG_ DTCI_DTCTriggered_78A: 0|1@0+ (1,0) [0|1] "" HMIM_HS FCP_HS ONSTAR_HS
  SG_ DTCI_HistStat_78A: 44|1@0+ (1,0) [0|1] "" HMIM_HS FCP_HS ONSTAR_HS
  SG_ DTCI_TstFldCdClrdStat_78A: 43|1@0+ (1,0) [0|1] "" HMIM_HS FCP_HS ONSTAR_HS
  SG_ DTCI_TstFldPwrUpSt_78A: 46|1@0+ (1,0) [0|1] "" HMIM_HS FCP_HS ONSTAR_HS
  SG_ DTCI_TstNPsdCdClrdSt_78A: 42|1@0+ (1,0) [0|1] "" HMIM_HS FCP_HS ONSTAR_HS
  SG_ DTCI_TstNPsdPwrUpSt_78A: 45|1@0+ (1,0) [0|1] "" HMIM_HS FCP_HS ONSTAR_HS
  SG_ DTCIUnused1_78A: 7|1@0+ (1,0) [0|1] "" HMIM_HS FCP_HS ONSTAR_HS
  SG_ DTCIUnused2_78A: 6|1@0+ (1,0) [0|1] "" HMIM_HS FCP_HS ONSTAR_HS
  SG_ DTCIUnused3_78A: 5|1@0+ (1,0) [0|1] "" HMIM_HS FCP_HS ONSTAR_HS
  SG_ DTCIUnused4_78A: 4|1@0+ (1,0) [0|1] "" HMIM_HS FCP_HS ONSTAR_HS
  SG_ DTCIUnused5_78A: 3|1@0+ (1,0) [0|1] "" HMIM_HS FCP_HS ONSTAR_HS
  SG_ DTCIUnused6_78A: 2|1@0+ (1,0) [0|1] "" HMIM_HS FCP_HS ONSTAR_HS
  SG_ DTCIUnused7_78A: 1|1@0+ (1,0) [0|1] "" HMIM_HS FCP_HS ONSTAR_HS
  SG_ DTCI_WrnIndRqdSt_78A: 47|1@0+ (1,0) [0|1] "" HMIM_HS FCP_HS ONSTAR_HS

BO_ 1929 DTC_Triggered_789: 7 ARS_HS
  SG_ DTCI_CodeSupported_789: 40|1@0+ (1,0) [0|1] "" HMIM_HS FCP_HS ONSTAR_HS
  SG_ DTCI_CurrentStatus_789: 41|1@0+ (1,0) [0|1] "" HMIM_HS FCP_HS ONSTAR_HS
  SG_ DTCI_DTCFailType_789: 39|8@0+ (1,0) [0|255] "" HMIM_HS FCP_HS ONSTAR_HS
  SG_ DTCI_DTCFaultType_789: 55|8@0+ (1,0) [0|255] "" HMIM_HS FCP_HS ONSTAR_HS
  SG_ DTCI_DTCNumber_789: 23|16@0+ (1,0) [0|65535] "" HMIM_HS FCP_HS ONSTAR_HS
  SG_ DTCI_DTCSource_789: 15|8@0+ (1,0) [0|255] "" HMIM_HS FCP_HS ONSTAR_HS
  SG_ DTCI_DTCTriggered_789: 0|1@0+ (1,0) [0|1] "" HMIM_HS FCP_HS ONSTAR_HS
  SG_ DTCI_HistStat_789: 44|1@0+ (1,0) [0|1] "" HMIM_HS FCP_HS ONSTAR_HS
  SG_ DTCI_TstFldCdClrdStat_789: 43|1@0+ (1,0) [0|1] "" HMIM_HS FCP_HS ONSTAR_HS
  SG_ DTCI_TstFldPwrUpSt_789: 46|1@0+ (1,0) [0|1] "" HMIM_HS FCP_HS ONSTAR_HS
  SG_ DTCI_TstNPsdCdClrdSt_789: 42|1@0+ (1,0) [0|1] "" HMIM_HS FCP_HS ONSTAR_HS
  SG_ DTCI_TstNPsdPwrUpSt_789: 45|1@0+ (1,0) [0|1] "" HMIM_HS FCP_HS ONSTAR_HS
  SG_ DTCIUnused1_789: 7|1@0+ (1,0) [0|1] "" HMIM_HS FCP_HS ONSTAR_HS
  SG_ DTCIUnused2_789: 6|1@0+ (1,0) [0|1] "" HMIM_HS FCP_HS ONSTAR_HS
  SG_ DTCIUnused3_789: 5|1@0+ (1,0) [0|1] "" HMIM_HS FCP_HS ONSTAR_HS
  SG_ DTCIUnused4_789: 4|1@0+ (1,0) [0|1] "" HMIM_HS FCP_HS ONSTAR_HS
  SG_ DTCIUnused5_789: 3|1@0+ (1,0) [0|1] "" HMIM_HS FCP_HS ONSTAR_HS
  SG_ DTCIUnused6_789: 2|1@0+ (1,0) [0|1] "" HMIM_HS FCP_HS ONSTAR_HS
  SG_ DTCIUnused7_789: 1|1@0+ (1,0) [0|1] "" HMIM_HS FCP_HS ONSTAR_HS
  SG_ DTCI_WrnIndRqdSt_789: 47|1@0+ (1,0) [0|1] "" HMIM_HS FCP_HS ONSTAR_HS

BO_ 1928 DTC_Triggered_788: 7 HMIM_HS
  SG_ DTCI_CodeSupported_788: 40|1@0+ (1,0) [0|1] "" HMIM_HS FCP_HS ONSTAR_HS
  SG_ DTCI_CurrentStatus_788: 41|1@0+ (1,0) [0|1] "" HMIM_HS FCP_HS ONSTAR_HS
  SG_ DTCI_DTCFailType_788: 39|8@0+ (1,0) [0|255] "" HMIM_HS FCP_HS ONSTAR_HS
  SG_ DTCI_DTCFaultType_788: 55|8@0+ (1,0) [0|255] "" HMIM_HS FCP_HS ONSTAR_HS
  SG_ DTCI_DTCNumber_788: 23|16@0+ (1,0) [0|65535] "" HMIM_HS FCP_HS ONSTAR_HS
  SG_ DTCI_DTCSource_788: 15|8@0+ (1,0) [0|255] "" HMIM_HS FCP_HS ONSTAR_HS
  SG_ DTCI_DTCTriggered_788: 0|1@0+ (1,0) [0|1] "" HMIM_HS FCP_HS ONSTAR_HS
  SG_ DTCI_HistStat_788: 44|1@0+ (1,0) [0|1] "" HMIM_HS FCP_HS ONSTAR_HS
  SG_ DTCI_TstFldCdClrdStat_788: 42|1@0+ (1,0) [0|1] "" HMIM_HS FCP_HS ONSTAR_HS
  SG_ DTCI_TstFldPwrUpSt_788: 46|1@0+ (1,0) [0|1] "" HMIM_HS FCP_HS ONSTAR_HS
  SG_ DTCI_TstNPsdCdClrdSt_788: 43|1@0+ (1,0) [0|1] "" HMIM_HS FCP_HS ONSTAR_HS
  SG_ DTCI_TstNPsdPwrUpSt_788: 45|1@0+ (1,0) [0|1] "" HMIM_HS FCP_HS ONSTAR_HS
  SG_ DTCIUnused1_788: 7|1@0+ (1,0) [0|1] "" HMIM_HS FCP_HS ONSTAR_HS
  SG_ DTCIUnused2_788: 6|1@0+ (1,0) [0|1] "" HMIM_HS FCP_HS ONSTAR_HS
  SG_ DTCIUnused3_788: 5|1@0+ (1,0) [0|1] "" HMIM_HS FCP_HS ONSTAR_HS
  SG_ DTCIUnused4_788: 4|1@0+ (1,0) [0|1] "" HMIM_HS FCP_HS ONSTAR_HS
  SG_ DTCIUnused5_788: 3|1@0+ (1,0) [0|1] "" HMIM_HS FCP_HS ONSTAR_HS
  SG_ DTCIUnused6_788: 2|1@0+ (1,0) [0|1] "" HMIM_HS FCP_HS ONSTAR_HS
  SG_ DTCIUnused7_788: 1|1@0+ (1,0) [0|1] "" HMIM_HS FCP_HS ONSTAR_HS
  SG_ DTCI_WrnIndRqdSt_788: 47|1@0+ (1,0) [0|1] "" HMIM_HS FCP_HS ONSTAR_HS

BO_ 1927 DTC_Triggered_787: 7 VICM_HS
  SG_ DTCI_CodeSupported_787: 40|1@0+ (1,0) [0|1] "" HMIM_HS FCP_HS ONSTAR_HS
  SG_ DTCI_CurrentStatus_787: 41|1@0+ (1,0) [0|1] "" HMIM_HS FCP_HS ONSTAR_HS
  SG_ DTCI_DTCFailType_787: 39|8@0+ (1,0) [0|255] "" HMIM_HS FCP_HS ONSTAR_HS
  SG_ DTCI_DTCFaultType_787: 55|8@0+ (1,0) [0|255] "" HMIM_HS FCP_HS ONSTAR_HS
  SG_ DTCI_DTCNumber_787: 23|16@0+ (1,0) [0|65535] "" HMIM_HS FCP_HS ONSTAR_HS
  SG_ DTCI_DTCSource_787: 15|8@0+ (1,0) [0|255] "" HMIM_HS FCP_HS ONSTAR_HS
  SG_ DTCI_DTCTriggered_787: 0|1@0+ (1,0) [0|1] "" HMIM_HS FCP_HS ONSTAR_HS
  SG_ DTCI_HistStat_787: 44|1@0+ (1,0) [0|1] "" HMIM_HS FCP_HS ONSTAR_HS
  SG_ DTCI_TstFldCdClrdStat_787: 43|1@0+ (1,0) [0|1] "" HMIM_HS FCP_HS ONSTAR_HS
  SG_ DTCI_TstFldPwrUpSt_787: 46|1@0+ (1,0) [0|1] "" HMIM_HS FCP_HS ONSTAR_HS
  SG_ DTCI_TstNPsdCdClrdSt_787: 42|1@0+ (1,0) [0|1] "" HMIM_HS FCP_HS ONSTAR_HS
  SG_ DTCI_TstNPsdPwrUpSt_787: 45|1@0+ (1,0) [0|1] "" HMIM_HS FCP_HS ONSTAR_HS
  SG_ DTCIUnused1_787: 7|1@0+ (1,0) [0|1] "" HMIM_HS FCP_HS ONSTAR_HS
  SG_ DTCIUnused2_787: 6|1@0+ (1,0) [0|1] "" HMIM_HS FCP_HS ONSTAR_HS
  SG_ DTCIUnused3_787: 5|1@0+ (1,0) [0|1] "" HMIM_HS FCP_HS ONSTAR_HS
  SG_ DTCIUnused4_787: 4|1@0+ (1,0) [0|1] "" HMIM_HS FCP_HS ONSTAR_HS
  SG_ DTCIUnused5_787: 3|1@0+ (1,0) [0|1] "" HMIM_HS FCP_HS ONSTAR_HS
  SG_ DTCIUnused6_787: 2|1@0+ (1,0) [0|1] "" HMIM_HS FCP_HS ONSTAR_HS
  SG_ DTCIUnused7_787: 1|1@0+ (1,0) [0|1] "" HMIM_HS FCP_HS ONSTAR_HS
  SG_ DTCI_WrnIndRqdSt_787: 47|1@0+ (1,0) [0|1] "" HMIM_HS FCP_HS ONSTAR_HS

BO_ 1926 DTC_Triggered_786: 7 MCP_B_HS
  SG_ DTCI_CodeSupported_786: 40|1@0+ (1,0) [0|1] "" HMIM_HS FCP_HS ONSTAR_HS
  SG_ DTCI_CurrentStatus_786: 41|1@0+ (1,0) [0|1] "" HMIM_HS FCP_HS ONSTAR_HS
  SG_ DTCI_DTCFailType_786: 39|8@0+ (1,0) [0|255] "" HMIM_HS FCP_HS ONSTAR_HS
  SG_ DTCI_DTCFaultType_786: 55|8@0+ (1,0) [0|255] "" HMIM_HS FCP_HS ONSTAR_HS
  SG_ DTCI_DTCNumber_786: 23|16@0+ (1,0) [0|65535] "" HMIM_HS FCP_HS ONSTAR_HS
  SG_ DTCI_DTCSource_786: 15|8@0+ (1,0) [0|255] "" HMIM_HS FCP_HS ONSTAR_HS
  SG_ DTCI_DTCTriggered_786: 0|1@0+ (1,0) [0|1] "" HMIM_HS FCP_HS ONSTAR_HS
  SG_ DTCI_HistStat_786: 44|1@0+ (1,0) [0|1] "" HMIM_HS FCP_HS ONSTAR_HS
  SG_ DTCI_TstFldCdClrdStat_786: 43|1@0+ (1,0) [0|1] "" HMIM_HS FCP_HS ONSTAR_HS
  SG_ DTCI_TstFldPwrUpSt_786: 46|1@0+ (1,0) [0|1] "" HMIM_HS FCP_HS ONSTAR_HS
  SG_ DTCI_TstNPsdCdClrdSt_786: 42|1@0+ (1,0) [0|1] "" HMIM_HS FCP_HS ONSTAR_HS
  SG_ DTCI_TstNPsdPwrUpSt_786: 45|1@0+ (1,0) [0|1] "" HMIM_HS FCP_HS ONSTAR_HS
  SG_ DTCIUnused1_786: 7|1@0+ (1,0) [0|1] "" HMIM_HS FCP_HS ONSTAR_HS
  SG_ DTCIUnused2_786: 6|1@0+ (1,0) [0|1] "" HMIM_HS FCP_HS ONSTAR_HS
  SG_ DTCIUnused3_786: 5|1@0+ (1,0) [0|1] "" HMIM_HS FCP_HS ONSTAR_HS
  SG_ DTCIUnused4_786: 4|1@0+ (1,0) [0|1] "" HMIM_HS FCP_HS ONSTAR_HS
  SG_ DTCIUnused5_786: 3|1@0+ (1,0) [0|1] "" HMIM_HS FCP_HS ONSTAR_HS
  SG_ DTCIUnused6_786: 2|1@0+ (1,0) [0|1] "" HMIM_HS FCP_HS ONSTAR_HS
  SG_ DTCIUnused7_786: 1|1@0+ (1,0) [0|1] "" HMIM_HS FCP_HS ONSTAR_HS
  SG_ DTCI_WrnIndRqdSt_786: 47|1@0+ (1,0) [0|1] "" HMIM_HS FCP_HS ONSTAR_HS

BO_ 1925 DTC_Triggered_785: 7 ICCM_HS
  SG_ DTCI_CodeSupported_785: 40|1@0+ (1,0) [0|1] "" HMIM_HS FCP_HS ONSTAR_HS
  SG_ DTCI_CurrentStatus_785: 41|1@0+ (1,0) [0|1] "" HMIM_HS FCP_HS ONSTAR_HS
  SG_ DTCI_DTCFailType_785: 39|8@0+ (1,0) [0|255] "" HMIM_HS FCP_HS ONSTAR_HS
  SG_ DTCI_DTCFaultType_785: 55|8@0+ (1,0) [0|255] "" HMIM_HS FCP_HS ONSTAR_HS
  SG_ DTCI_DTCNumber_785: 23|16@0+ (1,0) [0|65535] "" HMIM_HS FCP_HS ONSTAR_HS
  SG_ DTCI_DTCSource_785: 15|8@0+ (1,0) [0|255] "" HMIM_HS FCP_HS ONSTAR_HS
  SG_ DTCI_DTCTriggered_785: 0|1@0+ (1,0) [0|1] "" HMIM_HS FCP_HS ONSTAR_HS
  SG_ DTCI_HistStat_785: 44|1@0+ (1,0) [0|1] "" HMIM_HS FCP_HS ONSTAR_HS
  SG_ DTCI_TstFldCdClrdStat_785: 43|1@0+ (1,0) [0|1] "" HMIM_HS FCP_HS ONSTAR_HS
  SG_ DTCI_TstFldPwrUpSt_785: 46|1@0+ (1,0) [0|1] "" HMIM_HS FCP_HS ONSTAR_HS
  SG_ DTCI_TstNPsdCdClrdSt_785: 42|1@0+ (1,0) [0|1] "" HMIM_HS FCP_HS ONSTAR_HS
  SG_ DTCI_TstNPsdPwrUpSt_785: 45|1@0+ (1,0) [0|1] "" HMIM_HS FCP_HS ONSTAR_HS
  SG_ DTCIUnused1_785: 7|1@0+ (1,0) [0|1] "" HMIM_HS FCP_HS ONSTAR_HS
  SG_ DTCIUnused2_785: 6|1@0+ (1,0) [0|1] "" HMIM_HS FCP_HS ONSTAR_HS
  SG_ DTCIUnused3_785: 5|1@0+ (1,0) [0|1] "" HMIM_HS FCP_HS ONSTAR_HS
  SG_ DTCIUnused4_785: 4|1@0+ (1,0) [0|1] "" HMIM_HS FCP_HS ONSTAR_HS
  SG_ DTCIUnused5_785: 3|1@0+ (1,0) [0|1] "" HMIM_HS FCP_HS ONSTAR_HS
  SG_ DTCIUnused6_785: 2|1@0+ (1,0) [0|1] "" HMIM_HS FCP_HS ONSTAR_HS
  SG_ DTCIUnused7_785: 1|1@0+ (1,0) [0|1] "" HMIM_HS FCP_HS ONSTAR_HS
  SG_ DTCI_WrnIndRqdSt_785: 47|1@0+ (1,0) [0|1] "" HMIM_HS FCP_HS ONSTAR_HS

BO_TX_BU_ 869:ACC_HS,EOCM_F_HS;
BO_TX_BU_ 717:ACC_HS,EOCM_F_HS;
BO_TX_BU_ 564:EBCM_OBD_HS,EBCM_HS,PTAM_HS;
BO_TX_BU_ 953:PCM_HS,ECM_HS;
BO_TX_BU_ 1005:VLBS_HS,FCP_HS,ONSTAR_HS;
BO_TX_BU_ 490:VCM_HS,FICM_HS,PCM_HS,ECM_HS;
BO_TX_BU_ 715:EOCM_F_HS,ACC_HS;
BO_TX_BU_ 1267:PCM_HS,ECM_HS;
BO_TX_BU_ 453:PCM_HS,ECM_HS;
BO_TX_BU_ 452:PCM_HS,ECM_HS;
BO_TX_BU_ 1925:ICCM_OBD_HS,ICCM_HS;
VAL_ 853 SrvPedtrnProtSysIO 0 "false" 1 "true";
VAL_ 853 PedtrnProtSysDisbld 0 "false" 1 "true";
VAL_ 853 PedtrnProtSysDpl 0 "false" 1 "true";
VAL_ 869 FCACustStngAvlbl 0 "false" 1 "true";
VAL_ 869 FwdClnAlrtCustCrntSetngVal 0 "No Action" 1 "Off" 2 "On";
VAL_ 869 GNCustSetngAvlbl 0 "false" 1 "true";
VAL_ 869 CPSUnblIO 0 "false" 1 "true";
VAL_ 869 ColPrSysStngAvl 0 "false" 1 "true";
VAL_ 869 CPSOffIO 0 "false" 1 "true";
VAL_ 869 CPSFldIO 0 "false" 1 "true";
VAL_ 869 ColPrSysCrntStng 0 "No Action" 1 "Off" 2 "Alert" 3 "Alert and Brake";
VAL_ 869 CPSAlrtOnlIO 0 "false" 1 "true";
VAL_ 869 GNCustCrntStngVal 0 "No Action" 1 "Off" 2 "On";
VAL_ 717 CPSATC_AxlTrqRqstAct 0 "false" 1 "true";
VAL_ 564 TrlrStabAstActIO 0 "false" 1 "true";
VAL_ 564 PerfTracSysStat 0 "Enabled" 1 "Disabled" 2 "Unavailable" 3 "Failed";
VAL_ 564 PerfTrcCrnExStngVal 0 "No Action" 1 "Off" 2 "Setting 1" 3 "Setting 2" 4 "Setting 3" 5 "Setting 4" 6 "Setting 5" 7 "Setting 6" 8 "Setting 7" 9 "Setting 8" 10 "Setting 9" 11 "Setting 10" 12 "Setting 11" 13 "Setting 12" 14 "Setting 13" 15 "Setting 14" 16 "Setting 15";
VAL_ 313 PrkAstAdvSysAct 0 "false" 1 "true";
VAL_ 313 SndPerfMdCsStRq 0 "No Action" 1 "Performance Mode 1" 2 "Performance Mode 2" 3 "Performance Mode 3" 4 "Performance Mode 4" 5 "Performance Mode 5" 6 "Performance Mode 6" 7 "Auto";
VAL_ 313 HptcStVbnStat 0 "Normal Operation" 1 "Unknown" 2 "Failed";
VAL_ 313 ACCSettingType 0 "Manual" 1 "Auto";
VAL_ 313 FCABrkPrflReq 0 "false" 1 "true";
VAL_ 313 ISA2CCC_ScndCdChr 0 "Unknown" 1 "A" 2 "B" 3 "C" 4 "D" 5 "E" 6 "F" 7 "G" 8 "H" 9 "I" 10 "J" 11 "K" 12 "L" 13 "M" 14 "N" 15 "O" 16 "P" 17 "Q" 18 "R" 19 "S" 20 "T" 21 "U" 22 "V" 23 "W" 24 "X" 25 "Y" 26 "Z";
VAL_ 313 ISA2CCC_FrstCdChr 0 "Unknown" 1 "A" 2 "B" 3 "C" 4 "D" 5 "E" 6 "F" 7 "G" 8 "H" 9 "I" 10 "J" 11 "K" 12 "L" 13 "M" 14 "N" 15 "O" 16 "P" 17 "Q" 18 "R" 19 "S" 20 "T" 21 "U" 22 "V" 23 "W" 24 "X" 25 "Y" 26 "Z";
VAL_ 313 DispPerfMdCsStRq 0 "No Action" 1 "Performance Mode 1" 2 "Performance Mode 2" 3 "Performance Mode 3" 4 "Performance Mode 4" 5 "Performance Mode 5" 6 "Performance Mode 6" 7 "Auto";
VAL_ 313 CrshAlrtStPrsnt 0 "false" 1 "true";
VAL_ 313 FwdClnAlrtCustStngReq 0 "No Action" 1 "Off" 2 "On";
VAL_ 313 GNCustStngReq 0 "No Action" 1 "Off" 2 "On";
VAL_ 818 FrntAxlTmpInhIO 0 "false" 1 "true";
VAL_ 818 FrAxlMalfIO 0 "false" 1 "true";
VAL_ 1328 ACSAlarm9 0 "Inactive" 1 "Active" 2 "Expired";
VAL_ 1328 ACSAlarm8 0 "Inactive" 1 "Active" 2 "Expired";
VAL_ 1328 ACSAlarm7 0 "Inactive" 1 "Active" 2 "Expired";
VAL_ 1328 ACSAlarm6 0 "Inactive" 1 "Active" 2 "Expired";
VAL_ 1328 ACSAlarm5 0 "Inactive" 1 "Active" 2 "Expired";
VAL_ 1328 ACSAlarm4 0 "Inactive" 1 "Active" 2 "Expired";
VAL_ 1328 ACSAlarm3 0 "Inactive" 1 "Active" 2 "Expired";
VAL_ 1328 ACSAlarm2 0 "Inactive" 1 "Active" 2 "Expired";
VAL_ 1328 ACSAlarm15 0 "Inactive" 1 "Active" 2 "Expired";
VAL_ 1328 ACSAlarm14 0 "Inactive" 1 "Active" 2 "Expired";
VAL_ 1328 ACSAlarm13 0 "Inactive" 1 "Active" 2 "Expired";
VAL_ 1328 ACSAlarm12 0 "Inactive" 1 "Active" 2 "Expired";
VAL_ 1328 ACSAlarm11 0 "Inactive" 1 "Active" 2 "Expired";
VAL_ 1328 ACSAlarm10 0 "Inactive" 1 "Active" 2 "Expired";
VAL_ 1328 ACSAlarm1 0 "Inactive" 1 "Active" 2 "Expired";
VAL_ 1328 ACSAlarm0 0 "Inactive" 1 "Active" 2 "Expired";
VAL_ 1296 ACCAutoSetSpdStat 0 "No Set Speed Change" 1 "Proposed Speed Limit Change" 2 "Accepted Speed Limit Change" 3 "Declined Speed Limit Change";
VAL_ 1296 FwdClnAlrtOffIO 0 "false" 1 "true";
VAL_ 1296 VADIR_IndLvl 0 "No indication" 1 "Indication level 1" 2 "Indication Level 2" 3 "Indication Level 3" 4 "Indication Level 4" 5 "Indication Level 5" 6 "Indication Level 6" 7 "Indication Level 7" 8 "Indication Level 8";
VAL_ 311 PsngSysHdingV 0 "Valid" 1 "Invalid";
VAL_ 311 HrsV 0 "Valid" 1 "Invalid";
VAL_ 311 MinsV 0 "Valid" 1 "Invalid";
VAL_ 311 PsngSysDilPrcsV 0 "Valid" 1 "Invalid";
VAL_ 311 PsngSysElvtnV 0 "Valid" 1 "Invalid";
VAL_ 311 VehSpeSta 0 "Stationary" 1 "Slow" 2 "Fast" 3 "Invalid";
VAL_ 536 ShtToPrkBfExtngVehIO 0 "false" 1 "true";
VAL_ 536 AutoBrkRlsIO 0 "false" 1 "true";
VAL_ 536 HdUpDsplyUnblIO 0 "false" 1 "true";
VAL_ 536 FSRACCFrstRsmPrssIO 0 "false" 1 "true";
VAL_ 536 FrtRdrBlckdIO 0 "false" 1 "true";
VAL_ 810 PsngSysLongV 0 "Valid" 1 "Invalid";
VAL_ 810 PsngSysLatV 0 "Valid" 1 "Invalid";
VAL_ 848 TrlrBrkStat 0 "Normal Operation" 1 "Brake Control Interactive" 2 "Temporary Inhibit" 3 "Temporarily Limited" 4 "Permanently Failed" 5 "Communication Failed" 6 "Integration Calibrated Off";
VAL_ 848 TrlrBrkngSysBrkLtsReq 0 "false" 1 "true";
VAL_ 848 SrvTrlrBrkngSysIO 0 "false" 1 "true";
VAL_ 848 TrlrWiringFltIO 0 "false" 1 "true";
VAL_ 848 TrlrCnctdIO 0 "false" 1 "true";
VAL_ 848 TrlrBrkngGainSetIO 0 "false" 1 "true";
VAL_ 848 ChkTrlrIO 0 "false" 1 "true";
VAL_ 848 TrlrHtchSwAtv_ITBC 0 "false" 1 "true";
VAL_ 953 DslGlwTypReqd 0 "Cold Start" 1 "Intermediate" 2 "Diesel Particulate Filter Cleaning";
VAL_ 953 RdctHtrCReq 0 "Off" 1 "On";
VAL_ 953 RdctHtrBReq 0 "Off" 1 "On";
VAL_ 953 RdctHtrAReq 0 "Off" 1 "On";
VAL_ 953 EngPwrCnfg 0 "Default" 1 "Configuration 1" 2 "Configuration 2" 3 "Configuration 3" 4 "Configuration 4" 5 "Configuration 5" 6 "Configuration 6" 7 "Configuration 7" 8 "Configuration 8" 9 "Configuration 9" 10 "Configuration 10" 11 "Configuration 11" 12 "Configuration 12" 13 "Configuration 13" 14 "Configuration 14" 15 "Configuration 15";
VAL_ 953 EngCntlSenPTRlyVltM 0 "Don't Use Data" 1 "Use Data";
VAL_ 953 CrntFlConsmpV 0 "Valid" 1 "Invalid";
VAL_ 953 DslPartFltrClngAlgActM 0 "Don't Use Data" 1 "Use Data";
VAL_ 953 DslPartFltrClngAlgAct 0 "false" 1 "true";
VAL_ 953 MassAirFloV 0 "Valid" 1 "Invalid";
VAL_ 953 GlwPlgReqdOn 0 "false" 1 "true";
VAL_ 711 RdVltCrntTmpModInitStat 0 "Not Complete" 1 "Complete";
VAL_ 711 RdVltCrTmpMdCntOpFlt 0 "false" 1 "true";
VAL_ 711 RdHVltBatPckVltV 0 "Valid" 1 "Invalid";
VAL_ 711 RdHVltBatPckVltM 0 "Don't Use Data" 1 "Use Data";
VAL_ 711 RdHVltBatPckCrntV 0 "Valid" 1 "Invalid";
VAL_ 711 RdHVltBatPckCrntM 0 "Don't Use Data" 1 "Use Data";
VAL_ 711 RdntHVBatClOvrVltTstAct 0 "false" 1 "true";
VAL_ 304 PedFrndlyAlrtCsStReq 0 "No Action" 1 "Off" 2 "On";
VAL_ 304 AlrmStat 0 "Off" 1 "Armed" 2 "Disarmed" 3 "Alarm Active" 4 "Arming Delay";
VAL_ 1105 JmpStrtReq 0 "false" 1 "true";
VAL_ 1105 HybVehHiVltInvDisRqd 0 "false" 1 "true";
VAL_ 1105 NESSRoSevSt 0 "false" 1 "true";
VAL_ 1105 NESSRiSiSevSt 0 "false" 1 "true";
VAL_ 1105 NESSReImpSevSt 0 "false" 1 "true";
VAL_ 1105 NESSLeSiSevSt 0 "false" 1 "true";
VAL_ 1105 NESSFrImpSt2SevSt 0 "false" 1 "true";
VAL_ 1105 NESSFrImpSt1SevSt 0 "false" 1 "true";
VAL_ 1105 NESSFrImpPreSevSt 0 "false" 1 "true";
VAL_ 1005 EnhSvVehTopSpdLmR 0 "No Action" 1 "Active" 2 "Inactive";
VAL_ 688 StrtrGenSpdV 0 "Valid" 1 "Invalid";
VAL_ 993 CstmrUsblSOCV 0 "Valid" 1 "Invalid";
VAL_ 993 JmpStrtStat 0 "Inactive" 1 "In Progress" 2 "Complete" 3 "Power Mode" 4 "Disabled";
VAL_ 993 HybVehHiVltSysDisbld 0 "false" 1 "true";
VAL_ 993 SvcHybridSysIO 0 "false" 1 "true";
VAL_ 993 HybMdDisp 0 "Default / Accessory" 1 "Engine Idle" 2 "Auto Stop" 3 "Battery Power 2WD" 4 "Battery Power 4WD" 5 "Engine Power 2WD" 6 "Engine Power 4WD" 7 "Hybrid Power 2WD" 8 "Hybrid Power 4WD" 9 "Charging With Engine Off" 10 "Charging With Engine On" 11 "Undetermined" 12 "Battery Power Load Sharing" 13 "Engine Power Load Sharing" 14 "Engine Charging Battery Moving" 15 "Engine Charging Battery While Idle";
VAL_ 490 SrvcFlSysPrkInOpnArIO 0 "false" 1 "true";
VAL_ 490 FlLvlTank2PctV 0 "Valid" 1 "Invalid";
VAL_ 490 AltFuelPHeatAct 0 "false" 1 "true";
VAL_ 490 AltFuelMdReqDndIO 0 "false" 1 "true";
VAL_ 490 AltFuelLvlLo 0 "false" 1 "true";
VAL_ 490 AltFuelAccWrnngAct 0 "false" 1 "true";
VAL_ 490 FuelMdStat 0 "Gasoline Mode" 1 "Natural Gas Mode" 2 "Liquified Petroleum Gas Mode" 3 "Alternative Fuel Cut-off Active";
VAL_ 431 TDslPrtFltrIdlRgtnMdAtv 0 "false" 1 "true";
VAL_ 431 DrvlneTrqStabStat 0 "Normal Stability" 1 "Level 1" 2 "Level 2" 3 "Level 3";
VAL_ 431 TrnsTrqCnvCltCmdMdF 0 "false" 1 "true";
VAL_ 431 AutoTransGrSftDirectFl 0 "false" 1 "true";
VAL_ 431 AutoTransGrSftDirect 0 "No Shift in Progress" 1 "Upshift in Progress" 2 "Downshift in Progress";
VAL_ 431 TrnsTrqCnvCltCmndMd 0 "Unlocked" 1 "Transitioning" 2 "Controlled Slip" 3 "Locked" 7 "Not Supported";
VAL_ 431 TrnsStWntrMdOvrd 0 "No Override" 1 "Override To Not Winter" 2 "Override To Winter";
VAL_ 431 TrnsStTwHaulMdOvrd 0 "No Override" 1 "Override To Not Tow Haul" 2 "Override To Tow Haul";
VAL_ 431 TrnsStSprtMdOvrd 0 "No Override" 1 "Override To Not Sport" 2 "Override To Sport";
VAL_ 431 TrnsStEconMdOvrd 0 "No Override" 1 "Override To Not Economy" 2 "Override To Economy";
VAL_ 431 TrnsInpCltchStat 0 "Disengaged" 1 "Engaging" 2 "Engaged" 3 "Disengaging" 4 "Controlled Slip" 5 "Reserved" 6 "Reserved" 7 "Not Supported";
VAL_ 431 TrnsAntcptdCrpTrqRRnV 0 "Valid" 1 "Invalid";
VAL_ 431 TrnCltAdpAtv 0 "false" 1 "true";
VAL_ 431 TransCrnkPermsnStat 0 "Crank Not Permitted" 1 "Crank Permitted";
VAL_ 431 WrmUpShftPtrn 0 "Inactive" 1 "Active";
VAL_ 715 ACCATC_SplREngInpR 0 "false" 1 "true";
VAL_ 715 ACCATC_DrvAstdGoSt 0 "Not Stopped" 1 "Apply Accel Pedal to Go" 2 "Apply Acc Pedal or Resume Sw To Go";
VAL_ 715 ACCATC_ACCTyp 0 "Adaptive Cruise Control" 1 "Full Speed Range ACC" 2 "Full Speed Range ACC with Booster";
VAL_ 715 ACCATC_ACCAct 0 "false" 1 "true";
VAL_ 453 DrvIntndAxlTrqV 0 "Valid" 1 "Invalid";
VAL_ 453 DrvIntndAxlTrqMinV 0 "Valid" 1 "Invalid";
VAL_ 453 DrvIntndAxlTrqMaxV 0 "Valid" 1 "Invalid";
VAL_ 452 FSpRgACCSwADd 0 "false" 1 "true";
VAL_ 452 ABAAPS_AccPosV 0 "Valid" 1 "Invalid";
VAL_ 452 ACCATCS_LmtgStat 0 "Request Not Limited" 1 "Request Value Limited Minimum" 2 "Request Value Limited Maximum" 3 "Request Rate Limited";
VAL_ 452 ACCATCS_RqStat 0 "No Request" 1 "Request Honored" 2 "Lost Arbitration" 3 "Request Denied" 4 "Request Suspended Till Driver Input";
VAL_ 452 AccPdlOvrrdAtv 0 "false" 1 "true";
VAL_ 452 CPSATCS_ReqStatus 0 "No Request" 1 "Request Honored" 2 "Lost Arbitration" 3 "Serial Data Failure Temporary" 4 "Serial Data Failure Permanent" 5 "Control System Failure Temporary" 6 "Control System Failure Permanent";
VAL_ 452 CPSATCS_LmtngStatus 0 "Request Not Limited" 1 "Request Value Limited to Minimum" 2 "Request Value Limited to Maximum" 3 "Request Rate Limited";
VAL_ 452 RVBATCS_ReqStat 0 "No Request" 1 "Request Honored" 2 "Lost Arbitration" 3 "Serial Data Failure Temporary" 4 "Serial Data Failure Permanent" 5 "Control System Failure Temporary" 6 "Control System Failure Permanent";
VAL_ 452 RVBATCS_LmtngStat 0 "Request Not Limited" 1 "Request Value Limited to Minimum" 2 "Request Value Limited to Maximum" 3 "Request Rate Limited";
VAL_ 1905 DTCI_DTCFaultType_771 0 "Not Supported" 1 "Type A" 2 "Type B" 3 "Type C";
VAL_ 1905 DTCI_CodeSupported_771 0 "false" 1 "true";
VAL_ 1905 DTCI_CurrentStatus_771 0 "false" 1 "true";
VAL_ 1905 DTCI_TstNPsdCdClrdSt_771 0 "false" 1 "true";
VAL_ 1905 DTCI_TstFldCdClrdStat_771 0 "false" 1 "true";
VAL_ 1905 DTCI_HistStat_771 0 "false" 1 "true";
VAL_ 1905 DTCI_TstNPsdPwrUpSt_771 0 "false" 1 "true";
VAL_ 1905 DTCI_TstFldPwrUpSt_771 0 "false" 1 "true";
VAL_ 1905 DTCI_WrnIndRqdSt_771 0 "false" 1 "true";
VAL_ 1905 DTCI_DTCTriggered_771 0 "false" 1 "true";
VAL_ 1905 DTCIUnused7_771 0 "false" 1 "true";
VAL_ 1905 DTCIUnused6_771 0 "false" 1 "true";
VAL_ 1905 DTCIUnused5_771 0 "false" 1 "true";
VAL_ 1905 DTCIUnused4_771 0 "false" 1 "true";
VAL_ 1905 DTCIUnused3_771 0 "false" 1 "true";
VAL_ 1905 DTCIUnused2_771 0 "false" 1 "true";
VAL_ 1905 DTCIUnused1_771 0 "false" 1 "true";
VAL_ 1935 DTCI_DTCTriggered_78F 0 "false" 1 "true";
VAL_ 1935 DTCIUnused1_78F 0 "false" 1 "true";
VAL_ 1935 DTCIUnused2_78F 0 "false" 1 "true";
VAL_ 1935 DTCIUnused3_78F 0 "false" 1 "true";
VAL_ 1935 DTCIUnused4_78F 0 "false" 1 "true";
VAL_ 1935 DTCIUnused5_78F 0 "false" 1 "true";
VAL_ 1935 DTCIUnused6_78F 0 "false" 1 "true";
VAL_ 1935 DTCIUnused7_78F 0 "false" 1 "true";
VAL_ 1935 DTCI_CodeSupported_78F 0 "false" 1 "true";
VAL_ 1935 DTCI_CurrentStatus_78F 0 "false" 1 "true";
VAL_ 1935 DTCI_DTCFaultType_78F 0 "Not Supported" 1 "Type A" 2 "Type B" 3 "Type C";
VAL_ 1935 DTCI_TstFldCdClrdStat_78F 0 "false" 1 "true";
VAL_ 1935 DTCI_TstNPsdCdClrdSt_78F 0 "false" 1 "true";
VAL_ 1935 DTCI_HistStat_78F 0 "false" 1 "true";
VAL_ 1935 DTCI_TstNPsdPwrUpSt_78F 0 "false" 1 "true";
VAL_ 1935 DTCI_TstFldPwrUpSt_78F 0 "false" 1 "true";
VAL_ 1935 DTCI_WrnIndRqdSt_78F 0 "false" 1 "true";
VAL_ 1934 DTCI_CodeSupported_78E 0 "false" 1 "true";
VAL_ 1934 DTCI_CurrentStatus_78E 0 "false" 1 "true";
VAL_ 1934 DTCI_DTCFaultType_78E 0 "Not Supported" 1 "Type A" 2 "Type B" 3 "Type C";
VAL_ 1934 DTCI_DTCTriggered_78E 0 "false" 1 "true";
VAL_ 1934 DTCI_HistStat_78E 0 "false" 1 "true";
VAL_ 1934 DTCI_TstFldCdClrdStat_78E 0 "false" 1 "true";
VAL_ 1934 DTCI_TstFldPwrUpSt_78E 0 "false" 1 "true";
VAL_ 1934 DTCI_TstNPsdCdClrdSt_78E 0 "false" 1 "true";
VAL_ 1934 DTCI_TstNPsdPwrUpSt_78E 0 "false" 1 "true";
VAL_ 1934 DTCIUnused1_78E 0 "false" 1 "true";
VAL_ 1934 DTCIUnused2_78E 0 "false" 1 "true";
VAL_ 1934 DTCIUnused3_78E 0 "false" 1 "true";
VAL_ 1934 DTCIUnused4_78E 0 "false" 1 "true";
VAL_ 1934 DTCIUnused5_78E 0 "false" 1 "true";
VAL_ 1934 DTCIUnused6_78E 0 "false" 1 "true";
VAL_ 1934 DTCIUnused7_78E 0 "false" 1 "true";
VAL_ 1934 DTCI_WrnIndRqdSt_78E 0 "false" 1 "true";
VAL_ 1933 DTCI_CodeSupported_78D 0 "false" 1 "true";
VAL_ 1933 DTCI_CurrentStatus_78D 0 "false" 1 "true";
VAL_ 1933 DTCI_DTCFaultType_78D 0 "Not Supported" 1 "Type A" 2 "Type B" 3 "Type C";
VAL_ 1933 DTCI_DTCTriggered_78D 0 "false" 1 "true";
VAL_ 1933 DTCI_HistStat_78D 0 "false" 1 "true";
VAL_ 1933 DTCI_TstFldCdClrdStat_78D 0 "false" 1 "true";
VAL_ 1933 DTCI_TstFldPwrUpSt_78D 0 "false" 1 "true";
VAL_ 1933 DTCI_TstNPsdCdClrdSt_78D 0 "false" 1 "true";
VAL_ 1933 DTCI_TstNPsdPwrUpSt_78D 0 "false" 1 "true";
VAL_ 1933 DTCIUnused1_78D 0 "false" 1 "true";
VAL_ 1933 DTCIUnused2_78D 0 "false" 1 "true";
VAL_ 1933 DTCIUnused3_78D 0 "false" 1 "true";
VAL_ 1933 DTCIUnused4_78D 0 "false" 1 "true";
VAL_ 1933 DTCIUnused5_78D 0 "false" 1 "true";
VAL_ 1933 DTCIUnused6_78D 0 "false" 1 "true";
VAL_ 1933 DTCIUnused7_78D 0 "false" 1 "true";
VAL_ 1933 DTCI_WrnIndRqdSt_78D 0 "false" 1 "true";
VAL_ 1932 DTCI_CodeSupported_78C 0 "false" 1 "true";
VAL_ 1932 DTCI_CurrentStatus_78C 0 "false" 1 "true";
VAL_ 1932 DTCI_DTCFaultType_78C 0 "Not Supported" 1 "Type A" 2 "Type B" 3 "Type C";
VAL_ 1932 DTCI_DTCTriggered_78C 0 "false" 1 "true";
VAL_ 1932 DTCI_HistStat_78C 0 "false" 1 "true";
VAL_ 1932 DTCI_TstFldCdClrdStat_78C 0 "false" 1 "true";
VAL_ 1932 DTCI_TstFldPwrUpSt_78C 0 "false" 1 "true";
VAL_ 1932 DTCI_TstNPsdCdClrdSt_78C 0 "false" 1 "true";
VAL_ 1932 DTCI_TstNPsdPwrUpSt_78C 0 "false" 1 "true";
VAL_ 1932 DTCIUnused1_78C 0 "false" 1 "true";
VAL_ 1932 DTCIUnused2_78C 0 "false" 1 "true";
VAL_ 1932 DTCIUnused3_78C 0 "false" 1 "true";
VAL_ 1932 DTCIUnused4_78C 0 "false" 1 "true";
VAL_ 1932 DTCIUnused5_78C 0 "false" 1 "true";
VAL_ 1932 DTCIUnused6_78C 0 "false" 1 "true";
VAL_ 1932 DTCIUnused7_78C 0 "false" 1 "true";
VAL_ 1932 DTCI_WrnIndRqdSt_78C 0 "false" 1 "true";
VAL_ 1931 DTCI_CodeSupported_78B 0 "false" 1 "true";
VAL_ 1931 DTCI_CurrentStatus_78B 0 "false" 1 "true";
VAL_ 1931 DTCI_DTCFaultType_78B 0 "Not Supported" 1 "Type A" 2 "Type B" 3 "Type C";
VAL_ 1931 DTCI_DTCTriggered_78B 0 "false" 1 "true";
VAL_ 1931 DTCI_HistStat_78B 0 "false" 1 "true";
VAL_ 1931 DTCI_TstFldCdClrdStat_78B 0 "false" 1 "true";
VAL_ 1931 DTCI_TstFldPwrUpSt_78B 0 "false" 1 "true";
VAL_ 1931 DTCI_TstNPsdCdClrdSt_78B 0 "false" 1 "true";
VAL_ 1931 DTCI_TstNPsdPwrUpSt_78B 0 "false" 1 "true";
VAL_ 1931 DTCIUnused1_78B 0 "false" 1 "true";
VAL_ 1931 DTCIUnused2_78B 0 "false" 1 "true";
VAL_ 1931 DTCIUnused3_78B 0 "false" 1 "true";
VAL_ 1931 DTCIUnused4_78B 0 "false" 1 "true";
VAL_ 1931 DTCIUnused5_78B 0 "false" 1 "true";
VAL_ 1931 DTCIUnused6_78B 0 "false" 1 "true";
VAL_ 1931 DTCIUnused7_78B 0 "false" 1 "true";
VAL_ 1931 DTCI_WrnIndRqdSt_78B 0 "false" 1 "true";
VAL_ 1930 DTCI_CodeSupported_78A 0 "false" 1 "true";
VAL_ 1930 DTCI_CurrentStatus_78A 0 "false" 1 "true";
VAL_ 1930 DTCI_DTCFaultType_78A 0 "Not Supported" 1 "Type A" 2 "Type B" 3 "Type C";
VAL_ 1930 DTCI_DTCTriggered_78A 0 "false" 1 "true";
VAL_ 1930 DTCI_HistStat_78A 0 "false" 1 "true";
VAL_ 1930 DTCI_TstFldCdClrdStat_78A 0 "false" 1 "true";
VAL_ 1930 DTCI_TstFldPwrUpSt_78A 0 "false" 1 "true";
VAL_ 1930 DTCI_TstNPsdCdClrdSt_78A 0 "false" 1 "true";
VAL_ 1930 DTCI_TstNPsdPwrUpSt_78A 0 "false" 1 "true";
VAL_ 1930 DTCIUnused1_78A 0 "false" 1 "true";
VAL_ 1930 DTCIUnused2_78A 0 "false" 1 "true";
VAL_ 1930 DTCIUnused3_78A 0 "false" 1 "true";
VAL_ 1930 DTCIUnused4_78A 0 "false" 1 "true";
VAL_ 1930 DTCIUnused5_78A 0 "false" 1 "true";
VAL_ 1930 DTCIUnused6_78A 0 "false" 1 "true";
VAL_ 1930 DTCIUnused7_78A 0 "false" 1 "true";
VAL_ 1930 DTCI_WrnIndRqdSt_78A 0 "false" 1 "true";
VAL_ 1929 DTCI_CodeSupported_789 0 "false" 1 "true";
VAL_ 1929 DTCI_CurrentStatus_789 0 "false" 1 "true";
VAL_ 1929 DTCI_DTCFaultType_789 0 "Not Supported" 1 "Type A" 2 "Type B" 3 "Type C";
VAL_ 1929 DTCI_DTCTriggered_789 0 "false" 1 "true";
VAL_ 1929 DTCI_HistStat_789 0 "false" 1 "true";
VAL_ 1929 DTCI_TstFldCdClrdStat_789 0 "false" 1 "true";
VAL_ 1929 DTCI_TstFldPwrUpSt_789 0 "false" 1 "true";
VAL_ 1929 DTCI_TstNPsdCdClrdSt_789 0 "false" 1 "true";
VAL_ 1929 DTCI_TstNPsdPwrUpSt_789 0 "false" 1 "true";
VAL_ 1929 DTCIUnused1_789 0 "false" 1 "true";
VAL_ 1929 DTCIUnused2_789 0 "false" 1 "true";
VAL_ 1929 DTCIUnused3_789 0 "false" 1 "true";
VAL_ 1929 DTCIUnused4_789 0 "false" 1 "true";
VAL_ 1929 DTCIUnused5_789 0 "false" 1 "true";
VAL_ 1929 DTCIUnused6_789 0 "false" 1 "true";
VAL_ 1929 DTCIUnused7_789 0 "false" 1 "true";
VAL_ 1929 DTCI_WrnIndRqdSt_789 0 "false" 1 "true";
VAL_ 1928 DTCI_CodeSupported_788 0 "false" 1 "true";
VAL_ 1928 DTCI_CurrentStatus_788 0 "false" 1 "true";
VAL_ 1928 DTCI_DTCFaultType_788 0 "Not Supported" 1 "Type A" 2 "Type B" 3 "Type C";
VAL_ 1928 DTCI_DTCTriggered_788 0 "false" 1 "true";
VAL_ 1928 DTCI_HistStat_788 0 "false" 1 "true";
VAL_ 1928 DTCI_TstFldCdClrdStat_788 0 "false" 1 "true";
VAL_ 1928 DTCI_TstFldPwrUpSt_788 0 "false" 1 "true";
VAL_ 1928 DTCI_TstNPsdCdClrdSt_788 0 "false" 1 "true";
VAL_ 1928 DTCI_TstNPsdPwrUpSt_788 0 "false" 1 "true";
VAL_ 1928 DTCIUnused1_788 0 "false" 1 "true";
VAL_ 1928 DTCIUnused2_788 0 "false" 1 "true";
VAL_ 1928 DTCIUnused3_788 0 "false" 1 "true";
VAL_ 1928 DTCIUnused4_788 0 "false" 1 "true";
VAL_ 1928 DTCIUnused5_788 0 "false" 1 "true";
VAL_ 1928 DTCIUnused6_788 0 "false" 1 "true";
VAL_ 1928 DTCIUnused7_788 0 "false" 1 "true";
VAL_ 1928 DTCI_WrnIndRqdSt_788 0 "false" 1 "true";
VAL_ 1927 DTCI_CodeSupported_787 0 "false" 1 "true";
VAL_ 1927 DTCI_CurrentStatus_787 0 "false" 1 "true";
VAL_ 1927 DTCI_DTCFaultType_787 0 "Not Supported" 1 "Type A" 2 "Type B" 3 "Type C";
VAL_ 1927 DTCI_DTCTriggered_787 0 "false" 1 "true";
VAL_ 1927 DTCI_HistStat_787 0 "false" 1 "true";
VAL_ 1927 DTCI_TstFldCdClrdStat_787 0 "false" 1 "true";
VAL_ 1927 DTCI_TstFldPwrUpSt_787 0 "false" 1 "true";
VAL_ 1927 DTCI_TstNPsdCdClrdSt_787 0 "false" 1 "true";
VAL_ 1927 DTCI_TstNPsdPwrUpSt_787 0 "false" 1 "true";
VAL_ 1927 DTCIUnused1_787 0 "false" 1 "true";
VAL_ 1927 DTCIUnused2_787 0 "false" 1 "true";
VAL_ 1927 DTCIUnused3_787 0 "false" 1 "true";
VAL_ 1927 DTCIUnused4_787 0 "false" 1 "true";
VAL_ 1927 DTCIUnused5_787 0 "false" 1 "true";
VAL_ 1927 DTCIUnused6_787 0 "false" 1 "true";
VAL_ 1927 DTCIUnused7_787 0 "false" 1 "true";
VAL_ 1927 DTCI_WrnIndRqdSt_787 0 "false" 1 "true";
VAL_ 1926 DTCI_CodeSupported_786 0 "false" 1 "true";
VAL_ 1926 DTCI_CurrentStatus_786 0 "false" 1 "true";
VAL_ 1926 DTCI_DTCFaultType_786 0 "Not Supported" 1 "Type A" 2 "Type B" 3 "Type C";
VAL_ 1926 DTCI_DTCTriggered_786 0 "false" 1 "true";
VAL_ 1926 DTCI_HistStat_786 0 "false" 1 "true";
VAL_ 1926 DTCI_TstFldCdClrdStat_786 0 "false" 1 "true";
VAL_ 1926 DTCI_TstFldPwrUpSt_786 0 "false" 1 "true";
VAL_ 1926 DTCI_TstNPsdCdClrdSt_786 0 "false" 1 "true";
VAL_ 1926 DTCI_TstNPsdPwrUpSt_786 0 "false" 1 "true";
VAL_ 1926 DTCIUnused1_786 0 "false" 1 "true";
VAL_ 1926 DTCIUnused2_786 0 "false" 1 "true";
VAL_ 1926 DTCIUnused3_786 0 "false" 1 "true";
VAL_ 1926 DTCIUnused4_786 0 "false" 1 "true";
VAL_ 1926 DTCIUnused5_786 0 "false" 1 "true";
VAL_ 1926 DTCIUnused6_786 0 "false" 1 "true";
VAL_ 1926 DTCIUnused7_786 0 "false" 1 "true";
VAL_ 1926 DTCI_WrnIndRqdSt_786 0 "false" 1 "true";
VAL_ 1925 DTCI_CodeSupported_785 0 "false" 1 "true";
VAL_ 1925 DTCI_CurrentStatus_785 0 "false" 1 "true";
VAL_ 1925 DTCI_DTCFaultType_785 0 "Not Supported" 1 "Type A" 2 "Type B" 3 "Type C";
VAL_ 1925 DTCI_DTCTriggered_785 0 "false" 1 "true";
VAL_ 1925 DTCI_HistStat_785 0 "false" 1 "true";
VAL_ 1925 DTCI_TstFldCdClrdStat_785 0 "false" 1 "true";
VAL_ 1925 DTCI_TstFldPwrUpSt_785 0 "false" 1 "true";
VAL_ 1925 DTCI_TstNPsdCdClrdSt_785 0 "false" 1 "true";
VAL_ 1925 DTCI_TstNPsdPwrUpSt_785 0 "false" 1 "true";
VAL_ 1925 DTCIUnused1_785 0 "false" 1 "true";
VAL_ 1925 DTCIUnused2_785 0 "false" 1 "true";
VAL_ 1925 DTCIUnused3_785 0 "false" 1 "true";
VAL_ 1925 DTCIUnused4_785 0 "false" 1 "true";
VAL_ 1925 DTCIUnused5_785 0 "false" 1 "true";
VAL_ 1925 DTCIUnused6_785 0 "false" 1 "true";
VAL_ 1925 DTCIUnused7_785 0 "false" 1 "true";
VAL_ 1925 DTCI_WrnIndRqdSt_785 0 "false" 1 "true";
CM_ BO_ 869 "Note that the ACC algorithm will transmit this message at a 50 ms periodic rate and the EOCM algorithm will transmit this message at a 40 ms periodic rate";
CM_ BO_ 717 "Note that the ACC algorithm will transmit this message at a 50 ms periodic rate and the EOCM algorithm will transmit this message at a 40 ms periodic rate";
CM_ SG_ 311 PsngSysHding "The 'usable' range is somewhat less than the encoded range (0.0 to 359.9 degrees).  0.0 degrees represents North, 90.0 degrees represents East.";
CM_ SG_ 810 PsngSysLong "The units of the data are milli-arcseconds (1/3,600,000 of a degree).  The actual 'usable' range of this data is somewhat less than the encoded range (+/- 648,000,000, corresponding to +/- 180 degrees)";
CM_ SG_ 810 PsngSysLat "The units of the data are milli-arcseconds (1/3,600,000 of a degree).  The actual 'usable' range of this data is somewhat less than the encoded range (+/- 324,000,000, corresponding to +/- 90 degrees)";
CM_ SG_ 1005 EnhSvVehTopSpdLimP "4 ASCII characters";
CM_ BO_ 715 "Note that the ACC algorithm will transmit this message at a 50 ms periodic rate and the EOCM algorithm will transmit this message at a 40 ms periodic rate";
CM_ SG_ 1905 DTCI_DTCFaultType_771 "Based on Powertrain definition.  Not expected to be supported by all devices.";
CM_ SG_ 1905 DTCI_DTCFailType_771 "Assigned per GMW3110, Appendix E";
CM_ SG_ 1905 DTCI_DTCSource_771 "This shall be equal to the Diagnostic Address of the transmittting device.";
CM_ SG_ 1935 DTCI_DTCSource_78F "This shall be equal to the Diagnostic Address of the transmittting device.";
CM_ SG_ 1935 DTCI_DTCFaultType_78F "Based on Powertrain definition.  Not expected to be supported by all devices.";
CM_ SG_ 1935 DTCI_DTCFailType_78F "Assigned per GMW3110, Appendix E";
CM_ SG_ 1934 DTCI_DTCFailType_78E "Assigned per GMW3110, Appendix E";
CM_ SG_ 1934 DTCI_DTCFaultType_78E "Based on Powertrain definition.  Not expected to be supported by all devices.";
CM_ SG_ 1934 DTCI_DTCSource_78E "This shall be equal to the Diagnostic Address of the transmittting device.";
CM_ SG_ 1933 DTCI_DTCFailType_78D "Assigned per GMW3110, Appendix E";
CM_ SG_ 1933 DTCI_DTCFaultType_78D "Based on Powertrain definition.  Not expected to be supported by all devices.";
CM_ SG_ 1933 DTCI_DTCSource_78D "This shall be equal to the Diagnostic Address of the transmittting device.";
CM_ SG_ 1932 DTCI_DTCFailType_78C "Assigned per GMW3110, Appendix E";
CM_ SG_ 1932 DTCI_DTCFaultType_78C "Based on Powertrain definition.  Not expected to be supported by all devices.";
CM_ SG_ 1932 DTCI_DTCSource_78C "This shall be equal to the Diagnostic Address of the transmittting device.";
CM_ SG_ 1931 DTCI_DTCFailType_78B "Assigned per GMW3110, Appendix E";
CM_ SG_ 1931 DTCI_DTCFaultType_78B "Based on Powertrain definition.  Not expected to be supported by all devices.";
CM_ SG_ 1931 DTCI_DTCSource_78B "This shall be equal to the Diagnostic Address of the transmittting device.";
CM_ SG_ 1930 DTCI_DTCFailType_78A "Assigned per GMW3110, Appendix E";
CM_ SG_ 1930 DTCI_DTCFaultType_78A "Based on Powertrain definition.  Not expected to be supported by all devices.";
CM_ SG_ 1930 DTCI_DTCSource_78A "This shall be equal to the Diagnostic Address of the transmittting device.";
CM_ SG_ 1929 DTCI_DTCFailType_789 "Assigned per GMW3110, Appendix E";
CM_ SG_ 1929 DTCI_DTCFaultType_789 "Based on Powertrain definition.  Not expected to be supported by all devices.";
CM_ SG_ 1929 DTCI_DTCSource_789 "This shall be equal to the Diagnostic Address of the transmittting device.";
CM_ SG_ 1928 DTCI_DTCFailType_788 "Assigned per GMW3110, Appendix E";
CM_ SG_ 1928 DTCI_DTCFaultType_788 "Based on Powertrain definition.  Not expected to be supported by all devices.";
CM_ SG_ 1928 DTCI_DTCSource_788 "This shall be equal to the Diagnostic Address of the transmittting device.";
CM_ SG_ 1927 DTCI_DTCFailType_787 "Assigned per GMW3110, Appendix E";
CM_ SG_ 1927 DTCI_DTCFaultType_787 "Based on Powertrain definition.  Not expected to be supported by all devices.";
CM_ SG_ 1927 DTCI_DTCSource_787 "This shall be equal to the Diagnostic Address of the transmittting device.";
CM_ SG_ 1926 DTCI_DTCFailType_786 "Assigned per GMW3110, Appendix E";
CM_ SG_ 1926 DTCI_DTCFaultType_786 "Based on Powertrain definition.  Not expected to be supported by all devices.";
CM_ SG_ 1926 DTCI_DTCSource_786 "This shall be equal to the Diagnostic Address of the transmittting device.";
CM_ SG_ 1925 DTCI_DTCFailType_785 "Assigned per GMW3110, Appendix E";
CM_ SG_ 1925 DTCI_DTCFaultType_785 "Based on Powertrain definition.  Not expected to be supported by all devices.";
CM_ SG_ 1925 DTCI_DTCSource_785 "This shall be equal to the Diagnostic Address of the transmittting device.";
BA_DEF_ SG_ "VNSigSLHS_VNReq" ENUM "No","Yes";
BA_DEF_ SG_ "VNSigSLHSSharedDiagnostic" ENUM "No","Yes";
BA_DEF_ SG_ "SignalType" STRING;
BA_DEF_ SG_ "PacketOrder" INT 0 65535;
BA_DEF_ SG_ "SignalLongName" STRING;
BA_DEF_ SG_ "GenSigStartValue" INT 0 65535;
BA_DEF_ SG_ "VNSigAllNodes" ENUM "No","Yes";
BA_DEF_ SG_ "GenSigDeltaValue" INT 0 0;
BA_DEF_ SG_ "GenSigSendType" ENUM "not used","not used","not used","not used","not used","not used","not used","NoSigSendType","not used","not used","OnAnyChange","OnChangeIfActive","OnDelta";
BA_DEF_ SG_ "GenSigSendOnInit" ENUM "Not Initialized","Application","Handler";
BA_DEF_ BO_ "AppGenMsgCycleTime" INT 0 0;
BA_DEF_ BO_ "GenMsgILSupport" ENUM "No","Yes";
BA_DEF_ BO_ "TpApplType" STRING;
BA_DEF_ BO_ "Prio" INT 0 7;
BA_DEF_ BO_ "MessageSubnet" ENUM "LS","MS","HS","CE","PE","HV","FO";
BA_DEF_ BO_ "DiagState" ENUM "No","Yes";
BA_DEF_ BO_ "GenMsgDelayTime" INT 0 100000;
BA_DEF_ BO_ "GenMsgCycleTime" INT 0 100000;
BA_DEF_ BO_ "GenMsgSendType" ENUM "cyclicX","spontanX","cyclicIfActiveX","spontanWithDelay","cyclicAndSpontanX","cyclicAndSpontanWithDelay","spontanWithRepitition","cyclicIfActiveAndSpontanWD";
BA_DEF_ BO_ "DiagResponse" ENUM "No","Yes";
BA_DEF_ BO_ "DiagRequest" ENUM "No","Yes";
BA_DEF_ BO_ "NmMessage" ENUM "No","Yes";
BA_DEF_DEF_ "VNSigSLHS_VNReq" "No";
BA_DEF_DEF_ "VNSigSLHSSharedDiagnostic" "No";
BA_DEF_DEF_ "SignalType" "";
BA_DEF_DEF_ "PacketOrder" 0;
BA_DEF_DEF_ "SignalLongName" "";
BA_DEF_DEF_ "GenSigStartValue" 0;
BA_DEF_DEF_ "VNSigAllNodes" "No";
BA_DEF_DEF_ "GenSigDeltaValue" 0;
BA_DEF_DEF_ "GenSigSendType" "NoSigSendType";
BA_DEF_DEF_ "GenSigSendOnInit" "Not Initialized";
BA_DEF_DEF_ "AppGenMsgCycleTime" 0;
BA_DEF_DEF_ "GenMsgILSupport" "Yes";
BA_DEF_DEF_ "TpApplType" "";
BA_DEF_DEF_ "Prio" 4;
BA_DEF_DEF_ "MessageSubnet" "FO";
BA_DEF_DEF_ "DiagState" "No";
BA_DEF_DEF_ "GenMsgDelayTime" 0;
BA_DEF_DEF_ "GenMsgCycleTime" 0;
BA_DEF_DEF_ "GenMsgSendType" "spontanX";
BA_DEF_DEF_ "DiagResponse" "No";
BA_DEF_DEF_ "DiagRequest" "No";
BA_DEF_DEF_ "NmMessage" "No";
BA_ "Prio" BO_ 853 0;
BA_ "GenMsgSendType" BO_ 853 0;
BA_ "GenMsgCycleTime" BO_ 853 100;
BA_ "MessageSubnet" BO_ 853 2;
BA_ "VNSigAllNodes" SG_ 853 SrvPedtrnProtSysIO 1;
BA_ "SignalLongName" SG_ 853 SrvPedtrnProtSysIO "Service Pedestrian Protection System Indication On";
BA_ "SignalType" SG_ 853 SrvPedtrnProtSysIO "BLN";
BA_ "VNSigAllNodes" SG_ 853 PedtrnProtSysDisbld 1;
BA_ "SignalLongName" SG_ 853 PedtrnProtSysDisbld "Pedestrian Protection System Disabled";
BA_ "SignalType" SG_ 853 PedtrnProtSysDisbld "BLN";
BA_ "VNSigAllNodes" SG_ 853 PedtrnProtSysDpl 1;
BA_ "SignalLongName" SG_ 853 PedtrnProtSysDpl "Pedestrian Protection System Deployed";
BA_ "SignalType" SG_ 853 PedtrnProtSysDpl "BLN";
BA_ "AppGenMsgCycleTime" BO_ 869 40;
BA_ "Prio" BO_ 869 0;
BA_ "MessageSubnet" BO_ 869 2;
BA_ "VNSigAllNodes" SG_ 869 FCACustStngAvlbl 1;
BA_ "SignalLongName" SG_ 869 FCACustStngAvlbl "Forward Collision Alert Customization Setting Available";
BA_ "SignalType" SG_ 869 FCACustStngAvlbl "BLN";
BA_ "VNSigAllNodes" SG_ 869 FwdClnAlrtCustCrntSetngVal 1;
BA_ "SignalLongName" SG_ 869 FwdClnAlrtCustCrntSetngVal "Forward Collision Alert Customization Current Setting Value";
BA_ "SignalType" SG_ 869 FwdClnAlrtCustCrntSetngVal "ENM";
BA_ "VNSigAllNodes" SG_ 869 GNCustSetngAvlbl 1;
BA_ "SignalLongName" SG_ 869 GNCustSetngAvlbl "Go Notifier Customization Setting Available";
BA_ "SignalType" SG_ 869 GNCustSetngAvlbl "BLN";
BA_ "VNSigAllNodes" SG_ 869 CPSUnblIO 1;
BA_ "SignalLongName" SG_ 869 CPSUnblIO "Collision Preparation System Unavailable Indication On";
BA_ "SignalType" SG_ 869 CPSUnblIO "BLN";
BA_ "VNSigAllNodes" SG_ 869 ColPrSysStngAvl 1;
BA_ "SignalLongName" SG_ 869 ColPrSysStngAvl "Collision Preparation System Setting Available";
BA_ "SignalType" SG_ 869 ColPrSysStngAvl "BLN";
BA_ "VNSigAllNodes" SG_ 869 CPSOffIO 1;
BA_ "SignalLongName" SG_ 869 CPSOffIO "Collision Preparation System Off Indication On";
BA_ "SignalType" SG_ 869 CPSOffIO "BLN";
BA_ "VNSigAllNodes" SG_ 869 CPSFldIO 1;
BA_ "SignalLongName" SG_ 869 CPSFldIO "Collision Preparation System Failed Indication On";
BA_ "SignalType" SG_ 869 CPSFldIO "BLN";
BA_ "VNSigAllNodes" SG_ 869 ColPrSysCrntStng 1;
BA_ "SignalLongName" SG_ 869 ColPrSysCrntStng "Collision Preparation System Current Setting Value";
BA_ "SignalType" SG_ 869 ColPrSysCrntStng "ENM";
BA_ "VNSigAllNodes" SG_ 869 CPSAlrtOnlIO 1;
BA_ "SignalLongName" SG_ 869 CPSAlrtOnlIO "Collision Preparation System Alert Only Indication On";
BA_ "SignalType" SG_ 869 CPSAlrtOnlIO "BLN";
BA_ "VNSigAllNodes" SG_ 869 GNCustCrntStngVal 1;
BA_ "SignalLongName" SG_ 869 GNCustCrntStngVal "Go Notifier Customization Current Setting Value";
BA_ "SignalType" SG_ 869 GNCustCrntStngVal "ENM";
BA_ "AppGenMsgCycleTime" BO_ 717 40;
BA_ "Prio" BO_ 717 0;
BA_ "MessageSubnet" BO_ 717 2;
BA_ "VNSigAllNodes" SG_ 717 ColPrSysAxlTrqCmdProtVal 1;
BA_ "SignalLongName" SG_ 717 ColPrSysAxlTrqCmdProtVal "Collision Preparation System Axle Torque Command Protection Value";
BA_ "SignalType" SG_ 717 ColPrSysAxlTrqCmdProtVal "UNM";
BA_ "VNSigAllNodes" SG_ 717 CPSATC_AxlTrqRqstAct 1;
BA_ "PacketOrder" SG_ 717 CPSATC_AxlTrqRqstAct 1;
BA_ "SignalLongName" SG_ 717 CPSATC_AxlTrqRqstAct "Collision Preparation System Axle Torque Command : Axle Torque Request Active";
BA_ "SignalType" SG_ 717 CPSATC_AxlTrqRqstAct "BLN";
BA_ "VNSigAllNodes" SG_ 717 CPSATC_AxlTrqRqst 1;
BA_ "PacketOrder" SG_ 717 CPSATC_AxlTrqRqst 2;
BA_ "SignalLongName" SG_ 717 CPSATC_AxlTrqRqst "Collision Preparation System Axle Torque Command : Axle Torque Request";
BA_ "GenSigStartValue" SG_ 717 CPSATC_AxlTrqRqst 32767;
BA_ "SignalType" SG_ 717 CPSATC_AxlTrqRqst "UNM";
BA_ "VNSigAllNodes" SG_ 717 ColPrSysAxlTrqCmdRC 1;
BA_ "SignalLongName" SG_ 717 ColPrSysAxlTrqCmdRC "Collision Preparation System Axle Torque Command Rolling Count";
BA_ "SignalType" SG_ 717 ColPrSysAxlTrqCmdRC "UNM";
BA_ "Prio" BO_ 568 0;
BA_ "GenMsgSendType" BO_ 568 0;
BA_ "GenMsgCycleTime" BO_ 568 10;
BA_ "MessageSubnet" BO_ 568 2;
BA_ "VNSigAllNodes" SG_ 568 a_12VSysVlt 1;
BA_ "SignalLongName" SG_ 568 a_12VSysVlt "12V System Voltage";
BA_ "SignalType" SG_ 568 a_12VSysVlt "UNM";
BA_ "Prio" BO_ 564 0;
BA_ "GenMsgSendType" BO_ 564 0;
BA_ "GenMsgCycleTime" BO_ 564 100;
BA_ "MessageSubnet" BO_ 564 2;
BA_ "VNSigAllNodes" SG_ 564 TrlrStabAstActIO 1;
BA_ "SignalLongName" SG_ 564 TrlrStabAstActIO "Trailer Stability Assist Active Indication On";
BA_ "SignalType" SG_ 564 TrlrStabAstActIO "BLN";
BA_ "VNSigAllNodes" SG_ 564 PerfTracSysStat 1;
BA_ "SignalLongName" SG_ 564 PerfTracSysStat "Performance Traction System Status";
BA_ "SignalType" SG_ 564 PerfTracSysStat "ENM";
BA_ "VNSigAllNodes" SG_ 564 PerfTrcCrnExStngVal 1;
BA_ "SignalLongName" SG_ 564 PerfTrcCrnExStngVal "Performance Traction Corner Exit Setting Value";
BA_ "SignalType" SG_ 564 PerfTrcCrnExStngVal "ENM";
BA_ "Prio" BO_ 313 0;
BA_ "GenMsgSendType" BO_ 313 0;
BA_ "GenMsgCycleTime" BO_ 313 100;
BA_ "MessageSubnet" BO_ 313 2;
BA_ "VNSigAllNodes" SG_ 313 PrkAstAdvSysAct 1;
BA_ "SignalLongName" SG_ 313 PrkAstAdvSysAct "Parking Assistance Advanced  System Active";
BA_ "SignalType" SG_ 313 PrkAstAdvSysAct "BLN";
BA_ "VNSigAllNodes" SG_ 313 SndPerfMdCsStRq 1;
BA_ "SignalLongName" SG_ 313 SndPerfMdCsStRq "Sound Performance Mode Customization Setting Request";
BA_ "SignalType" SG_ 313 SndPerfMdCsStRq "ENM";
BA_ "VNSigAllNodes" SG_ 313 HptcStVbnStat 1;
BA_ "SignalLongName" SG_ 313 HptcStVbnStat "Haptic Seat Vibration Status";
BA_ "SignalType" SG_ 313 HptcStVbnStat "ENM";
BA_ "VNSigAllNodes" SG_ 313 ACCSettingType 1;
BA_ "SignalLongName" SG_ 313 ACCSettingType "Adaptive Cruise Control Setting Type";
BA_ "SignalType" SG_ 313 ACCSettingType "ENM";
BA_ "VNSigAllNodes" SG_ 313 FCABrkPrflReq 1;
BA_ "SignalLongName" SG_ 313 FCABrkPrflReq "Forward Collision Alert Brake Prefill Request";
BA_ "SignalType" SG_ 313 FCABrkPrflReq "BLN";
BA_ "VNSigAllNodes" SG_ 313 ISA2CCC_ScndCdChr 1;
BA_ "PacketOrder" SG_ 313 ISA2CCC_ScndCdChr 1;
BA_ "SignalLongName" SG_ 313 ISA2CCC_ScndCdChr "International Standard Alpha 2 Coded Country Code : Second Code Character";
BA_ "SignalType" SG_ 313 ISA2CCC_ScndCdChr "ENM";
BA_ "VNSigAllNodes" SG_ 313 ISA2CCC_FrstCdChr 1;
BA_ "PacketOrder" SG_ 313 ISA2CCC_FrstCdChr 2;
BA_ "SignalLongName" SG_ 313 ISA2CCC_FrstCdChr "International Standard Alpha 2 Coded Country Code : First Code Character";
BA_ "SignalType" SG_ 313 ISA2CCC_FrstCdChr "ENM";
BA_ "VNSigAllNodes" SG_ 313 DispPerfMdCsStRq 1;
BA_ "SignalLongName" SG_ 313 DispPerfMdCsStRq "Display Performance Mode Customization Setting Request";
BA_ "SignalType" SG_ 313 DispPerfMdCsStRq "ENM";
BA_ "VNSigAllNodes" SG_ 313 CrshAlrtStPrsnt 1;
BA_ "SignalLongName" SG_ 313 CrshAlrtStPrsnt "Crash Alert Seat Present";
BA_ "SignalType" SG_ 313 CrshAlrtStPrsnt "BLN";
BA_ "VNSigAllNodes" SG_ 313 FwdClnAlrtCustStngReq 1;
BA_ "SignalLongName" SG_ 313 FwdClnAlrtCustStngReq "Forward Collision Alert Customization Setting Request";
BA_ "SignalType" SG_ 313 FwdClnAlrtCustStngReq "ENM";
BA_ "VNSigAllNodes" SG_ 313 GNCustStngReq 1;
BA_ "SignalLongName" SG_ 313 GNCustStngReq "Go Notifier Customization Setting Request";
BA_ "SignalType" SG_ 313 GNCustStngReq "ENM";
BA_ "Prio" BO_ 818 0;
BA_ "GenMsgSendType" BO_ 818 0;
BA_ "GenMsgCycleTime" BO_ 818 100;
BA_ "MessageSubnet" BO_ 818 2;
BA_ "VNSigAllNodes" SG_ 818 FrntAxlTmpInhIO 1;
BA_ "SignalLongName" SG_ 818 FrntAxlTmpInhIO "Front Axle Temporary Inhibit Indication On";
BA_ "SignalType" SG_ 818 FrntAxlTmpInhIO "BLN";
BA_ "VNSigAllNodes" SG_ 818 FrAxlMalfIO 1;
BA_ "SignalLongName" SG_ 818 FrAxlMalfIO "Front Axle Malfunction Indication On";
BA_ "SignalType" SG_ 818 FrAxlMalfIO "BLN";
BA_ "Prio" BO_ 1328 0;
BA_ "GenMsgSendType" BO_ 1328 0;
BA_ "GenMsgCycleTime" BO_ 1328 1000;
BA_ "MessageSubnet" BO_ 1328 2;
BA_ "VNSigAllNodes" SG_ 1328 ACSAlarm9 1;
BA_ "PacketOrder" SG_ 1328 ACSAlarm9 10;
BA_ "SignalLongName" SG_ 1328 ACSAlarm9 "Alarm Clock Status : Alarm 9";
BA_ "SignalType" SG_ 1328 ACSAlarm9 "ENM";
BA_ "VNSigAllNodes" SG_ 1328 ACSAlarm8 1;
BA_ "PacketOrder" SG_ 1328 ACSAlarm8 9;
BA_ "SignalLongName" SG_ 1328 ACSAlarm8 "Alarm Clock Status : Alarm 8";
BA_ "SignalType" SG_ 1328 ACSAlarm8 "ENM";
BA_ "VNSigAllNodes" SG_ 1328 ACSAlarm7 1;
BA_ "PacketOrder" SG_ 1328 ACSAlarm7 8;
BA_ "SignalLongName" SG_ 1328 ACSAlarm7 "Alarm Clock Status : Alarm 7";
BA_ "SignalType" SG_ 1328 ACSAlarm7 "ENM";
BA_ "VNSigAllNodes" SG_ 1328 ACSAlarm6 1;
BA_ "PacketOrder" SG_ 1328 ACSAlarm6 7;
BA_ "SignalLongName" SG_ 1328 ACSAlarm6 "Alarm Clock Status : Alarm 6";
BA_ "SignalType" SG_ 1328 ACSAlarm6 "ENM";
BA_ "VNSigAllNodes" SG_ 1328 ACSAlarm5 1;
BA_ "PacketOrder" SG_ 1328 ACSAlarm5 6;
BA_ "SignalLongName" SG_ 1328 ACSAlarm5 "Alarm Clock Status : Alarm 5";
BA_ "SignalType" SG_ 1328 ACSAlarm5 "ENM";
BA_ "VNSigAllNodes" SG_ 1328 ACSAlarm4 1;
BA_ "PacketOrder" SG_ 1328 ACSAlarm4 5;
BA_ "SignalLongName" SG_ 1328 ACSAlarm4 "Alarm Clock Status : Alarm 4";
BA_ "SignalType" SG_ 1328 ACSAlarm4 "ENM";
BA_ "VNSigAllNodes" SG_ 1328 ACSAlarm3 1;
BA_ "PacketOrder" SG_ 1328 ACSAlarm3 4;
BA_ "SignalLongName" SG_ 1328 ACSAlarm3 "Alarm Clock Status : Alarm 3";
BA_ "SignalType" SG_ 1328 ACSAlarm3 "ENM";
BA_ "VNSigAllNodes" SG_ 1328 ACSAlarm2 1;
BA_ "PacketOrder" SG_ 1328 ACSAlarm2 3;
BA_ "SignalLongName" SG_ 1328 ACSAlarm2 "Alarm Clock Status : Alarm 2";
BA_ "SignalType" SG_ 1328 ACSAlarm2 "ENM";
BA_ "VNSigAllNodes" SG_ 1328 ACSAlarm15 1;
BA_ "PacketOrder" SG_ 1328 ACSAlarm15 16;
BA_ "SignalLongName" SG_ 1328 ACSAlarm15 "Alarm Clock Status : Alarm 15";
BA_ "SignalType" SG_ 1328 ACSAlarm15 "ENM";
BA_ "VNSigAllNodes" SG_ 1328 ACSAlarm14 1;
BA_ "PacketOrder" SG_ 1328 ACSAlarm14 15;
BA_ "SignalLongName" SG_ 1328 ACSAlarm14 "Alarm Clock Status : Alarm 14";
BA_ "SignalType" SG_ 1328 ACSAlarm14 "ENM";
BA_ "VNSigAllNodes" SG_ 1328 ACSAlarm13 1;
BA_ "PacketOrder" SG_ 1328 ACSAlarm13 14;
BA_ "SignalLongName" SG_ 1328 ACSAlarm13 "Alarm Clock Status : Alarm 13";
BA_ "SignalType" SG_ 1328 ACSAlarm13 "ENM";
BA_ "VNSigAllNodes" SG_ 1328 ACSAlarm12 1;
BA_ "PacketOrder" SG_ 1328 ACSAlarm12 13;
BA_ "SignalLongName" SG_ 1328 ACSAlarm12 "Alarm Clock Status : Alarm 12";
BA_ "SignalType" SG_ 1328 ACSAlarm12 "ENM";
BA_ "VNSigAllNodes" SG_ 1328 ACSAlarm11 1;
BA_ "PacketOrder" SG_ 1328 ACSAlarm11 12;
BA_ "SignalLongName" SG_ 1328 ACSAlarm11 "Alarm Clock Status : Alarm 11";
BA_ "SignalType" SG_ 1328 ACSAlarm11 "ENM";
BA_ "VNSigAllNodes" SG_ 1328 ACSAlarm10 1;
BA_ "PacketOrder" SG_ 1328 ACSAlarm10 11;
BA_ "SignalLongName" SG_ 1328 ACSAlarm10 "Alarm Clock Status : Alarm 10";
BA_ "SignalType" SG_ 1328 ACSAlarm10 "ENM";
BA_ "VNSigAllNodes" SG_ 1328 ACSAlarm1 1;
BA_ "PacketOrder" SG_ 1328 ACSAlarm1 2;
BA_ "SignalLongName" SG_ 1328 ACSAlarm1 "Alarm Clock Status : Alarm 1";
BA_ "SignalType" SG_ 1328 ACSAlarm1 "ENM";
BA_ "VNSigAllNodes" SG_ 1328 ACSAlarm0 1;
BA_ "PacketOrder" SG_ 1328 ACSAlarm0 1;
BA_ "SignalLongName" SG_ 1328 ACSAlarm0 "Alarm Clock Status : Alarm 0";
BA_ "SignalType" SG_ 1328 ACSAlarm0 "ENM";
BA_ "Prio" BO_ 1296 0;
BA_ "GenMsgSendType" BO_ 1296 0;
BA_ "GenMsgCycleTime" BO_ 1296 100;
BA_ "MessageSubnet" BO_ 1296 2;
BA_ "VNSigAllNodes" SG_ 1296 ACCAutoSetSpdStat 1;
BA_ "SignalLongName" SG_ 1296 ACCAutoSetSpdStat "Adaptive Cruise Control Auto Set Speed Status";
BA_ "SignalType" SG_ 1296 ACCAutoSetSpdStat "ENM";
BA_ "VNSigAllNodes" SG_ 1296 FwdClnAlrtOffIO 1;
BA_ "SignalLongName" SG_ 1296 FwdClnAlrtOffIO "Forward Collision Alert Off Indication On";
BA_ "SignalType" SG_ 1296 FwdClnAlrtOffIO "BLN";
BA_ "VNSigAllNodes" SG_ 1296 VADIR_IndLvl 1;
BA_ "PacketOrder" SG_ 1296 VADIR_IndLvl 3;
BA_ "SignalLongName" SG_ 1296 VADIR_IndLvl "Vehicle Ahead Distance Indication Request : Indication Level";
BA_ "SignalType" SG_ 1296 VADIR_IndLvl "ENM";
BA_ "VNSigAllNodes" SG_ 1296 VADIR_FlwTme 1;
BA_ "PacketOrder" SG_ 1296 VADIR_FlwTme 2;
BA_ "SignalLongName" SG_ 1296 VADIR_FlwTme "Vehicle Ahead Distance Indication Request : Following Time";
BA_ "SignalType" SG_ 1296 VADIR_FlwTme "UNM";
BA_ "VNSigAllNodes" SG_ 1296 VADIR_FlwDst 1;
BA_ "PacketOrder" SG_ 1296 VADIR_FlwDst 1;
BA_ "SignalLongName" SG_ 1296 VADIR_FlwDst "Vehicle Ahead Distance Indication Request : Following Distance";
BA_ "SignalType" SG_ 1296 VADIR_FlwDst "UNM";
BA_ "Prio" BO_ 311 0;
BA_ "GenMsgSendType" BO_ 311 0;
BA_ "GenMsgCycleTime" BO_ 311 100;
BA_ "MessageSubnet" BO_ 311 2;
BA_ "VNSigAllNodes" SG_ 311 PsngSysDilPrcs 1;
BA_ "SignalLongName" SG_ 311 PsngSysDilPrcs "Positioning System Dilution of Precision";
BA_ "SignalType" SG_ 311 PsngSysDilPrcs "UNM";
BA_ "VNSigAllNodes" SG_ 311 Hrs 1;
BA_ "SignalLongName" SG_ 311 Hrs "Hours";
BA_ "SignalType" SG_ 311 Hrs "UNM";
BA_ "VNSigAllNodes" SG_ 311 PsngSysHding 1;
BA_ "SignalLongName" SG_ 311 PsngSysHding "Positioning System Heading";
BA_ "SignalType" SG_ 311 PsngSysHding "UNM";
BA_ "VNSigAllNodes" SG_ 311 PsngSysElvtn 1;
BA_ "SignalLongName" SG_ 311 PsngSysElvtn "Positioning System Elevation";
BA_ "SignalType" SG_ 311 PsngSysElvtn "UNM";
BA_ "VNSigAllNodes" SG_ 311 PsngSysHdingV 1;
BA_ "SignalLongName" SG_ 311 PsngSysHdingV "Positioning System Heading Validity";
BA_ "SignalType" SG_ 311 PsngSysHdingV "ENM";
BA_ "VNSigAllNodes" SG_ 311 HrsV 1;
BA_ "SignalLongName" SG_ 311 HrsV "Hours Validity";
BA_ "SignalType" SG_ 311 HrsV "ENM";
BA_ "VNSigAllNodes" SG_ 311 MinsV 1;
BA_ "SignalLongName" SG_ 311 MinsV "Minutes Validity";
BA_ "SignalType" SG_ 311 MinsV "ENM";
BA_ "VNSigAllNodes" SG_ 311 Mins 1;
BA_ "SignalLongName" SG_ 311 Mins "Minutes";
BA_ "SignalType" SG_ 311 Mins "UNM";
BA_ "VNSigAllNodes" SG_ 311 PsngSysDilPrcsV 1;
BA_ "SignalLongName" SG_ 311 PsngSysDilPrcsV "Positioning System Dilution of Precision Validity";
BA_ "SignalType" SG_ 311 PsngSysDilPrcsV "ENM";
BA_ "VNSigAllNodes" SG_ 311 PsngSysElvtnV 1;
BA_ "SignalLongName" SG_ 311 PsngSysElvtnV "Positioning System Elevation Validity";
BA_ "SignalType" SG_ 311 PsngSysElvtnV "ENM";
BA_ "VNSigAllNodes" SG_ 311 VehSpeSta 1;
BA_ "SignalLongName" SG_ 311 VehSpeSta "Vehicle Speed State";
BA_ "SignalType" SG_ 311 VehSpeSta "ENM";
BA_ "Prio" BO_ 536 0;
BA_ "GenMsgSendType" BO_ 536 0;
BA_ "GenMsgCycleTime" BO_ 536 200;
BA_ "MessageSubnet" BO_ 536 2;
BA_ "VNSigAllNodes" SG_ 536 ACCHptcStVbnRqSeqN 1;
BA_ "SignalLongName" SG_ 536 ACCHptcStVbnRqSeqN "Adaptive Cruise Control Haptic Seat Vibration Request Sequence Number";
BA_ "SignalType" SG_ 536 ACCHptcStVbnRqSeqN "UNM";
BA_ "VNSigAllNodes" SG_ 536 ACCHptcStVbnReq 1;
BA_ "SignalLongName" SG_ 536 ACCHptcStVbnReq "Adaptive Cruise Control Haptic Seat Vibration Request";
BA_ "SignalType" SG_ 536 ACCHptcStVbnReq "UNM";
BA_ "VNSigAllNodes" SG_ 536 ShtToPrkBfExtngVehIO 1;
BA_ "SignalLongName" SG_ 536 ShtToPrkBfExtngVehIO "Shift to Park Before Exiting Vehicle Indication On";
BA_ "SignalType" SG_ 536 ShtToPrkBfExtngVehIO "BLN";
BA_ "VNSigAllNodes" SG_ 536 AutoBrkRlsIO 1;
BA_ "SignalLongName" SG_ 536 AutoBrkRlsIO "Autonomous Brake Release Indication On";
BA_ "SignalType" SG_ 536 AutoBrkRlsIO "BLN";
BA_ "VNSigAllNodes" SG_ 536 HdUpDsplyUnblIO 1;
BA_ "SignalLongName" SG_ 536 HdUpDsplyUnblIO "Head Up Display Unavailable Indication On";
BA_ "SignalType" SG_ 536 HdUpDsplyUnblIO "BLN";
BA_ "VNSigAllNodes" SG_ 536 FSRACCFrstRsmPrssIO 1;
BA_ "SignalLongName" SG_ 536 FSRACCFrstRsmPrssIO "Full Speed Range Adaptive Cruise Control First Resume Press Indication On";
BA_ "SignalType" SG_ 536 FSRACCFrstRsmPrssIO "BLN";
BA_ "VNSigAllNodes" SG_ 536 FrtRdrBlckdIO 1;
BA_ "SignalLongName" SG_ 536 FrtRdrBlckdIO "Front Radar Blocked Indication On";
BA_ "SignalType" SG_ 536 FrtRdrBlckdIO "BLN";
BA_ "Prio" BO_ 570 0;
BA_ "GenMsgSendType" BO_ 570 0;
BA_ "GenMsgCycleTime" BO_ 570 200;
BA_ "MessageSubnet" BO_ 570 2;
BA_ "VNSigAllNodes" SG_ 570 FCAHptcStVbnRqSeqN 1;
BA_ "SignalLongName" SG_ 570 FCAHptcStVbnRqSeqN "Forward Collision Alert Haptic Seat Vibration Request Sequence Number";
BA_ "SignalType" SG_ 570 FCAHptcStVbnRqSeqN "UNM";
BA_ "VNSigAllNodes" SG_ 570 FCAHptcStVbnReq 1;
BA_ "SignalLongName" SG_ 570 FCAHptcStVbnReq "Forward Collision Alert Haptic Seat Vibration Request";
BA_ "SignalType" SG_ 570 FCAHptcStVbnReq "UNM";
BA_ "Prio" BO_ 810 0;
BA_ "GenMsgSendType" BO_ 810 0;
BA_ "GenMsgCycleTime" BO_ 810 100;
BA_ "MessageSubnet" BO_ 810 2;
BA_ "VNSigAllNodes" SG_ 810 PsngSysLongV 1;
BA_ "SignalLongName" SG_ 810 PsngSysLongV "Positioning System Longitude Validity";
BA_ "SignalType" SG_ 810 PsngSysLongV "ENM";
BA_ "VNSigAllNodes" SG_ 810 PsngSysLong 1;
BA_ "SignalLongName" SG_ 810 PsngSysLong "Positioning System Longitude";
BA_ "SignalType" SG_ 810 PsngSysLong "SNM";
BA_ "VNSigAllNodes" SG_ 810 PsngSysLatV 1;
BA_ "SignalLongName" SG_ 810 PsngSysLatV "Positioning System Latitude Validity";
BA_ "SignalType" SG_ 810 PsngSysLatV "ENM";
BA_ "VNSigAllNodes" SG_ 810 PsngSysLat 1;
BA_ "SignalLongName" SG_ 810 PsngSysLat "Positioning System Latitude";
BA_ "SignalType" SG_ 810 PsngSysLat "SNM";
BA_ "Prio" BO_ 848 0;
BA_ "GenMsgSendType" BO_ 848 0;
BA_ "GenMsgCycleTime" BO_ 848 50;
BA_ "MessageSubnet" BO_ 848 2;
BA_ "VNSigAllNodes" SG_ 848 TrlrBrkStat 1;
BA_ "SignalLongName" SG_ 848 TrlrBrkStat "Trailer Brake Status";
BA_ "SignalType" SG_ 848 TrlrBrkStat "ENM";
BA_ "VNSigAllNodes" SG_ 848 TrlrBrkngSysBrkLtsReq 1;
BA_ "SignalLongName" SG_ 848 TrlrBrkngSysBrkLtsReq "Trailer Braking System Brake Lights Requested";
BA_ "SignalType" SG_ 848 TrlrBrkngSysBrkLtsReq "BLN";
BA_ "VNSigAllNodes" SG_ 848 SrvTrlrBrkngSysIO 1;
BA_ "SignalLongName" SG_ 848 SrvTrlrBrkngSysIO "ServiceTrailer Braking System Indication On";
BA_ "SignalType" SG_ 848 SrvTrlrBrkngSysIO "BLN";
BA_ "VNSigAllNodes" SG_ 848 TrlrWiringFltIO 1;
BA_ "SignalLongName" SG_ 848 TrlrWiringFltIO "Trailer Wiring Fault Indication On";
BA_ "SignalType" SG_ 848 TrlrWiringFltIO "BLN";
BA_ "VNSigAllNodes" SG_ 848 TrlrCnctdIO 1;
BA_ "SignalLongName" SG_ 848 TrlrCnctdIO "Trailer Connected Indication On";
BA_ "SignalType" SG_ 848 TrlrCnctdIO "BLN";
BA_ "VNSigAllNodes" SG_ 848 TrlrBrkngGainSetIO 1;
BA_ "SignalLongName" SG_ 848 TrlrBrkngGainSetIO "Trailer Braking Gain Setting Indication On";
BA_ "SignalType" SG_ 848 TrlrBrkngGainSetIO "BLN";
BA_ "VNSigAllNodes" SG_ 848 TrlrBrkngGainSet 1;
BA_ "SignalLongName" SG_ 848 TrlrBrkngGainSet "Trailer Braking Gain Setting";
BA_ "SignalType" SG_ 848 TrlrBrkngGainSet "UNM";
BA_ "VNSigAllNodes" SG_ 848 TrlrBrkngFrcOtpt 1;
BA_ "SignalLongName" SG_ 848 TrlrBrkngFrcOtpt "Trailer Braking Force Output";
BA_ "SignalType" SG_ 848 TrlrBrkngFrcOtpt "UNM";
BA_ "VNSigAllNodes" SG_ 848 ChkTrlrIO 1;
BA_ "SignalLongName" SG_ 848 ChkTrlrIO "Check Trailer Indication On";
BA_ "SignalType" SG_ 848 ChkTrlrIO "BLN";
BA_ "VNSigAllNodes" SG_ 848 TrlrHtchSwAtv_ITBC 1;
BA_ "SignalLongName" SG_ 848 TrlrHtchSwAtv_ITBC "Trailer Hitch Switch Active ITBC";
BA_ "SignalType" SG_ 848 TrlrHtchSwAtv_ITBC "BLN";
BA_ "Prio" BO_ 953 0;
BA_ "GenMsgSendType" BO_ 953 0;
BA_ "GenMsgCycleTime" BO_ 953 100;
BA_ "MessageSubnet" BO_ 953 2;
BA_ "VNSigAllNodes" SG_ 953 DslGlwTypReqd 1;
BA_ "SignalLongName" SG_ 953 DslGlwTypReqd "Diesel Glow Type Requested";
BA_ "SignalType" SG_ 953 DslGlwTypReqd "ENM";
BA_ "VNSigAllNodes" SG_ 953 RdctHtrCReq 1;
BA_ "SignalLongName" SG_ 953 RdctHtrCReq "Reductant Heater C Request";
BA_ "SignalType" SG_ 953 RdctHtrCReq "ENM";
BA_ "VNSigAllNodes" SG_ 953 RdctHtrBReq 1;
BA_ "SignalLongName" SG_ 953 RdctHtrBReq "Reductant Heater B Request";
BA_ "SignalType" SG_ 953 RdctHtrBReq "ENM";
BA_ "VNSigAllNodes" SG_ 953 RdctHtrAReq 1;
BA_ "SignalLongName" SG_ 953 RdctHtrAReq "Reductant Heater A Request";
BA_ "SignalType" SG_ 953 RdctHtrAReq "ENM";
BA_ "VNSigAllNodes" SG_ 953 EngPwrCnfg 1;
BA_ "SignalLongName" SG_ 953 EngPwrCnfg "Engine Power Configuration";
BA_ "SignalType" SG_ 953 EngPwrCnfg "ENM";
BA_ "VNSigAllNodes" SG_ 953 EngCntlSenPTRlyVltM 1;
BA_ "SignalLongName" SG_ 953 EngCntlSenPTRlyVltM "Engine Controller Sensed Powertrain Relay Voltage Mask";
BA_ "SignalType" SG_ 953 EngCntlSenPTRlyVltM "ENM";
BA_ "VNSigAllNodes" SG_ 953 EngCntlSenPTRlyVlt 1;
BA_ "SignalLongName" SG_ 953 EngCntlSenPTRlyVlt "Engine Controller Sensed Powertrain Relay Voltage";
BA_ "SignalType" SG_ 953 EngCntlSenPTRlyVlt "UNM";
BA_ "VNSigAllNodes" SG_ 953 CrntFlConsmpV 1;
BA_ "SignalLongName" SG_ 953 CrntFlConsmpV "Current Fuel Consumption Validity";
BA_ "SignalType" SG_ 953 CrntFlConsmpV "ENM";
BA_ "VNSigAllNodes" SG_ 953 CrntFlConsmp 1;
BA_ "SignalLongName" SG_ 953 CrntFlConsmp "Current Fuel Consumption";
BA_ "SignalType" SG_ 953 CrntFlConsmp "UNM";
BA_ "VNSigAllNodes" SG_ 953 InAirHtrDtyCyclCmnd 1;
BA_ "SignalLongName" SG_ 953 InAirHtrDtyCyclCmnd "Intake Air Heater Duty Cycle Command";
BA_ "SignalType" SG_ 953 InAirHtrDtyCyclCmnd "UNM";
BA_ "VNSigAllNodes" SG_ 953 DslPartFltrClngAlgActM 1;
BA_ "SignalLongName" SG_ 953 DslPartFltrClngAlgActM "Diesel Particle Filter Cleaning Algorithm Active Mask";
BA_ "SignalType" SG_ 953 DslPartFltrClngAlgActM "ENM";
BA_ "VNSigAllNodes" SG_ 953 DslPartFltrClngAlgAct 1;
BA_ "SignalLongName" SG_ 953 DslPartFltrClngAlgAct "Diesel Particle Filter Cleaning Algorithm Active";
BA_ "SignalType" SG_ 953 DslPartFltrClngAlgAct "BLN";
BA_ "VNSigAllNodes" SG_ 953 MassAirFloV 1;
BA_ "SignalLongName" SG_ 953 MassAirFloV "Mass Air Flow Validity";
BA_ "SignalType" SG_ 953 MassAirFloV "ENM";
BA_ "VNSigAllNodes" SG_ 953 MassAirFlo 1;
BA_ "SignalLongName" SG_ 953 MassAirFlo "Mass Air Flow";
BA_ "SignalType" SG_ 953 MassAirFlo "UNM";
BA_ "VNSigAllNodes" SG_ 953 GlwPlgReqdOn 1;
BA_ "SignalLongName" SG_ 953 GlwPlgReqdOn "Glow Plugs Requested On";
BA_ "SignalType" SG_ 953 GlwPlgReqdOn "BLN";
BA_ "Prio" BO_ 711 0;
BA_ "GenMsgSendType" BO_ 711 0;
BA_ "GenMsgCycleTime" BO_ 711 25;
BA_ "MessageSubnet" BO_ 711 2;
BA_ "VNSigAllNodes" SG_ 711 RdVltCrntTmpModInitStat 1;
BA_ "SignalLongName" SG_ 711 RdVltCrntTmpModInitStat "Redundant Voltage Current Temperature Module Initialization Status";
BA_ "SignalType" SG_ 711 RdVltCrntTmpModInitStat "ENM";
BA_ "VNSigAllNodes" SG_ 711 RdVltCrTmpMdCntOpFlt 1;
BA_ "SignalLongName" SG_ 711 RdVltCrTmpMdCntOpFlt "Redundant Voltage Current Temperature Module Contactor Open Fault";
BA_ "SignalType" SG_ 711 RdVltCrTmpMdCntOpFlt "BLN";
BA_ "VNSigAllNodes" SG_ 711 RdHVltBatPckVltV 1;
BA_ "SignalLongName" SG_ 711 RdHVltBatPckVltV "Redundant High Voltage Battery Pack Voltage Validity";
BA_ "SignalType" SG_ 711 RdHVltBatPckVltV "ENM";
BA_ "VNSigAllNodes" SG_ 711 RdHVltBatPckVltM 1;
BA_ "SignalLongName" SG_ 711 RdHVltBatPckVltM "Redundant High Voltage Battery Pack Voltage Mask";
BA_ "SignalType" SG_ 711 RdHVltBatPckVltM "ENM";
BA_ "VNSigAllNodes" SG_ 711 RdHVltBatPckVlt 1;
BA_ "SignalLongName" SG_ 711 RdHVltBatPckVlt "Redundant High Voltage Battery Pack Voltage";
BA_ "SignalType" SG_ 711 RdHVltBatPckVlt "UNM";
BA_ "VNSigAllNodes" SG_ 711 RdHVltBatPckCrntV 1;
BA_ "SignalLongName" SG_ 711 RdHVltBatPckCrntV "Redundant High Voltage Battery Pack Current Validity";
BA_ "SignalType" SG_ 711 RdHVltBatPckCrntV "ENM";
BA_ "VNSigAllNodes" SG_ 711 RdHVltBatPckCrntM 1;
BA_ "SignalLongName" SG_ 711 RdHVltBatPckCrntM "Redundant High Voltage Battery Pack Current Mask";
BA_ "SignalType" SG_ 711 RdHVltBatPckCrntM "ENM";
BA_ "VNSigAllNodes" SG_ 711 RdHVltBatPckCrnt 1;
BA_ "SignalLongName" SG_ 711 RdHVltBatPckCrnt "Redundant High Voltage Battery Pack Current";
BA_ "SignalType" SG_ 711 RdHVltBatPckCrnt "SNM";
BA_ "VNSigAllNodes" SG_ 711 RdntHVBatClOvrVltTstAct 1;
BA_ "SignalLongName" SG_ 711 RdntHVBatClOvrVltTstAct "Redundant High Voltage Battery Cell Over Voltage Test Active";
BA_ "SignalType" SG_ 711 RdntHVBatClOvrVltTstAct "BLN";
BA_ "Prio" BO_ 1011 0;
BA_ "GenMsgSendType" BO_ 1011 0;
BA_ "GenMsgCycleTime" BO_ 1011 500;
BA_ "MessageSubnet" BO_ 1011 2;
BA_ "Prio" BO_ 304 0;
BA_ "GenMsgSendType" BO_ 304 0;
BA_ "GenMsgCycleTime" BO_ 304 1000;
BA_ "MessageSubnet" BO_ 304 2;
BA_ "VNSigAllNodes" SG_ 304 PedFrndlyAlrtCsStReq 1;
BA_ "SignalLongName" SG_ 304 PedFrndlyAlrtCsStReq "Pedestrian Friendly Alert Customization Setting Request";
BA_ "SignalType" SG_ 304 PedFrndlyAlrtCsStReq "ENM";
BA_ "VNSigAllNodes" SG_ 304 AlrmStat 1;
BA_ "SignalLongName" SG_ 304 AlrmStat "Alarm Status";
BA_ "SignalType" SG_ 304 AlrmStat "ENM";
BA_ "Prio" BO_ 1105 0;
BA_ "GenMsgSendType" BO_ 1105 0;
BA_ "GenMsgCycleTime" BO_ 1105 25;
BA_ "MessageSubnet" BO_ 1105 2;
BA_ "VNSigAllNodes" SG_ 1105 JmpStrtReq 1;
BA_ "SignalLongName" SG_ 1105 JmpStrtReq "Jump Start Requested";
BA_ "SignalType" SG_ 1105 JmpStrtReq "BLN";
BA_ "VNSigAllNodes" SG_ 1105 HybVehHiVltInvDisRqd 1;
BA_ "SignalLongName" SG_ 1105 HybVehHiVltInvDisRqd "Hybrid Vehicle High Voltage Inverter Disable Requested";
BA_ "SignalType" SG_ 1105 HybVehHiVltInvDisRqd "BLN";
BA_ "VNSigAllNodes" SG_ 1105 NESSRoSevSt 1;
BA_ "SignalLongName" SG_ 1105 NESSRoSevSt "Notification Event Severity Status : Rollover Severity Achieved";
BA_ "SignalType" SG_ 1105 NESSRoSevSt "BLN";
BA_ "VNSigAllNodes" SG_ 1105 NESSRiSiSevSt 1;
BA_ "SignalLongName" SG_ 1105 NESSRiSiSevSt "Notification Event Severity Status : Right Side Severity Achieved";
BA_ "SignalType" SG_ 1105 NESSRiSiSevSt "BLN";
BA_ "VNSigAllNodes" SG_ 1105 NESSReImpSevSt 1;
BA_ "SignalLongName" SG_ 1105 NESSReImpSevSt "Notification Event Severity Status : Rear Impact Severity Achieved";
BA_ "SignalType" SG_ 1105 NESSReImpSevSt "BLN";
BA_ "VNSigAllNodes" SG_ 1105 NESSLeSiSevSt 1;
BA_ "SignalLongName" SG_ 1105 NESSLeSiSevSt "Notification Event Severity Status : Left Side Severity Achieved";
BA_ "SignalType" SG_ 1105 NESSLeSiSevSt "BLN";
BA_ "VNSigAllNodes" SG_ 1105 NESSFrImpSt2SevSt 1;
BA_ "SignalLongName" SG_ 1105 NESSFrImpSt2SevSt "Notification Event Severity Status : Frontal Impact Stage 2 Severity Achieved";
BA_ "SignalType" SG_ 1105 NESSFrImpSt2SevSt "BLN";
BA_ "VNSigAllNodes" SG_ 1105 NESSFrImpSt1SevSt 1;
BA_ "SignalLongName" SG_ 1105 NESSFrImpSt1SevSt "Notification Event Severity Status : Frontal Impact Stage 1 Severity Achieved";
BA_ "SignalType" SG_ 1105 NESSFrImpSt1SevSt "BLN";
BA_ "VNSigAllNodes" SG_ 1105 NESSFrImpPreSevSt 1;
BA_ "SignalLongName" SG_ 1105 NESSFrImpPreSevSt "Notification Event Severity Status : Frontal Impact Pretensioner Severity Achieved";
BA_ "SignalType" SG_ 1105 NESSFrImpPreSevSt "BLN";
BA_ "VNSigAllNodes" SG_ 1105 ClmCntFrBlwFnSp 1;
BA_ "SignalLongName" SG_ 1105 ClmCntFrBlwFnSp "Climate Control Front Blower Fan Speed";
BA_ "SignalType" SG_ 1105 ClmCntFrBlwFnSp "UNM";
BA_ "Prio" BO_ 1005 0;
BA_ "GenMsgSendType" BO_ 1005 0;
BA_ "GenMsgCycleTime" BO_ 1005 250;
BA_ "MessageSubnet" BO_ 1005 2;
BA_ "VNSigAllNodes" SG_ 1005 EnhSvVehTopSpdLmR 1;
BA_ "SignalLongName" SG_ 1005 EnhSvVehTopSpdLmR "Enhanced Services Vehicle Top Speed Limit Request";
BA_ "SignalType" SG_ 1005 EnhSvVehTopSpdLmR "ENM";
BA_ "VNSigAllNodes" SG_ 1005 EnhSvVTpSpdLVlARC 1;
BA_ "SignalLongName" SG_ 1005 EnhSvVTpSpdLVlARC "Enhanced Services Vehicle Top Speed Limit Value Alive Rolling Count";
BA_ "SignalType" SG_ 1005 EnhSvVTpSpdLVlARC "UNM";
BA_ "VNSigAllNodes" SG_ 1005 EnhSvVehTopSpdLimP 1;
BA_ "SignalLongName" SG_ 1005 EnhSvVehTopSpdLimP "Enhanced Services Vehicle Top Speed Limit Password";
BA_ "SignalType" SG_ 1005 EnhSvVehTopSpdLimP "UNM";
BA_ "VNSigAllNodes" SG_ 1005 EnhSvVehTopSpdLim 1;
BA_ "SignalLongName" SG_ 1005 EnhSvVehTopSpdLim "Enhanced Services Vehicle Top Speed Limit Value";
BA_ "GenSigStartValue" SG_ 1005 EnhSvVehTopSpdLim 255;
BA_ "SignalType" SG_ 1005 EnhSvVehTopSpdLim "UNM";
BA_ "Prio" BO_ 688 0;
BA_ "GenMsgSendType" BO_ 688 0;
BA_ "GenMsgCycleTime" BO_ 688 20;
BA_ "MessageSubnet" BO_ 688 2;
BA_ "VNSigAllNodes" SG_ 688 StrtrGenSpdV 1;
BA_ "SignalLongName" SG_ 688 StrtrGenSpdV "Starter Generator Speed  Validity";
BA_ "SignalType" SG_ 688 StrtrGenSpdV "ENM";
BA_ "VNSigAllNodes" SG_ 688 StrtrGenSpd 1;
BA_ "SignalLongName" SG_ 688 StrtrGenSpd "Starter Generator Speed";
BA_ "SignalType" SG_ 688 StrtrGenSpd "UNM";
BA_ "Prio" BO_ 993 0;
BA_ "GenMsgSendType" BO_ 993 0;
BA_ "GenMsgCycleTime" BO_ 993 100;
BA_ "MessageSubnet" BO_ 993 2;
BA_ "VNSigAllNodes" SG_ 993 CstmrUsblSOCV 1;
BA_ "SignalLongName" SG_ 993 CstmrUsblSOCV "Customer Usable State of Charge Validity";
BA_ "SignalType" SG_ 993 CstmrUsblSOCV "ENM";
BA_ "VNSigAllNodes" SG_ 993 CstmrUsblSOC 1;
BA_ "SignalLongName" SG_ 993 CstmrUsblSOC "Customer Usable State of Charge";
BA_ "SignalType" SG_ 993 CstmrUsblSOC "UNM";
BA_ "VNSigAllNodes" SG_ 993 InstDrvEff 1;
BA_ "SignalLongName" SG_ 993 InstDrvEff "Instantaneous Drive Efficiency";
BA_ "SignalType" SG_ 993 InstDrvEff "SNM";
BA_ "VNSigAllNodes" SG_ 993 PwrPckAirInTempFlt 1;
BA_ "SignalLongName" SG_ 993 PwrPckAirInTempFlt "Power Pack Air Inlet Temperature Filtered";
BA_ "SignalType" SG_ 993 PwrPckAirInTempFlt "UNM";
BA_ "VNSigAllNodes" SG_ 993 PwrPkFnSpd 1;
BA_ "SignalLongName" SG_ 993 PwrPkFnSpd "Power Pack Fan Speed";
BA_ "SignalType" SG_ 993 PwrPkFnSpd "UNM";
BA_ "VNSigAllNodes" SG_ 993 JmpStrtStat 1;
BA_ "SignalLongName" SG_ 993 JmpStrtStat "Jump Start Status";
BA_ "SignalType" SG_ 993 JmpStrtStat "ENM";
BA_ "VNSigAllNodes" SG_ 993 HybVehHiVltSysDisbld 1;
BA_ "SignalLongName" SG_ 993 HybVehHiVltSysDisbld "Hybrid Vehicle High Voltage System Disabled";
BA_ "SignalType" SG_ 993 HybVehHiVltSysDisbld "BLN";
BA_ "VNSigAllNodes" SG_ 993 SvcHybridSysIO 1;
BA_ "SignalLongName" SG_ 993 SvcHybridSysIO "Service Hybrid System Indication On";
BA_ "SignalType" SG_ 993 SvcHybridSysIO "BLN";
BA_ "VNSigAllNodes" SG_ 993 HybMdDisp 1;
BA_ "SignalLongName" SG_ 993 HybMdDisp "Hybrid Mode Display";
BA_ "SignalType" SG_ 993 HybMdDisp "ENM";
BA_ "Prio" BO_ 490 0;
BA_ "GenMsgSendType" BO_ 490 0;
BA_ "GenMsgCycleTime" BO_ 490 12;
BA_ "MessageSubnet" BO_ 490 2;
BA_ "VNSigAllNodes" SG_ 490 SrvcFlSysPrkInOpnArIO 1;
BA_ "SignalLongName" SG_ 490 SrvcFlSysPrkInOpnArIO "Service Fuel System Park In Open Area Indication On";
BA_ "SignalType" SG_ 490 SrvcFlSysPrkInOpnArIO "BLN";
BA_ "VNSigAllNodes" SG_ 490 FuelTotCapTnk2 1;
BA_ "SignalLongName" SG_ 490 FuelTotCapTnk2 "Fuel Total Capacity Tank 2";
BA_ "SignalType" SG_ 490 FuelTotCapTnk2 "UNM";
BA_ "VNSigAllNodes" SG_ 490 FlLvlTank2PctV 1;
BA_ "SignalLongName" SG_ 490 FlLvlTank2PctV "Fuel Level Tank 2 Percent Validity";
BA_ "SignalType" SG_ 490 FlLvlTank2PctV "ENM";
BA_ "VNSigAllNodes" SG_ 490 FlLvlTank2Pct 1;
BA_ "SignalLongName" SG_ 490 FlLvlTank2Pct "Fuel Level Tank 2 Percent";
BA_ "SignalType" SG_ 490 FlLvlTank2Pct "UNM";
BA_ "VNSigAllNodes" SG_ 490 AltFuelPHeatAct 1;
BA_ "SignalLongName" SG_ 490 AltFuelPHeatAct "Alternative Fuel Pre-heating Active";
BA_ "SignalType" SG_ 490 AltFuelPHeatAct "BLN";
BA_ "VNSigAllNodes" SG_ 490 AltFuelMdReqDndIO 1;
BA_ "SignalLongName" SG_ 490 AltFuelMdReqDndIO "Alternative Fuel Mode Request Denied Indication On";
BA_ "SignalType" SG_ 490 AltFuelMdReqDndIO "BLN";
BA_ "VNSigAllNodes" SG_ 490 AltFuelLvlLo 1;
BA_ "SignalLongName" SG_ 490 AltFuelLvlLo "Alternative Fuel Level Low";
BA_ "SignalType" SG_ 490 AltFuelLvlLo "BLN";
BA_ "VNSigAllNodes" SG_ 490 AltFuelAccWrnngAct 1;
BA_ "SignalLongName" SG_ 490 AltFuelAccWrnngAct "Alternative Fuel Acceleration Warning Active";
BA_ "SignalType" SG_ 490 AltFuelAccWrnngAct "BLN";
BA_ "VNSigAllNodes" SG_ 490 FuelMdStat 1;
BA_ "SignalLongName" SG_ 490 FuelMdStat "Fuel Mode Status";
BA_ "SignalType" SG_ 490 FuelMdStat "ENM";
BA_ "Prio" BO_ 431 0;
BA_ "GenMsgSendType" BO_ 431 0;
BA_ "GenMsgCycleTime" BO_ 431 25;
BA_ "MessageSubnet" BO_ 431 2;
BA_ "VNSigAllNodes" SG_ 431 TransVehTopSpdLim 1;
BA_ "SignalLongName" SG_ 431 TransVehTopSpdLim "Transmission Vehicle Top Speed Limit Value";
BA_ "SignalType" SG_ 431 TransVehTopSpdLim "UNM";
BA_ "VNSigAllNodes" SG_ 431 TransMinVoltReq 1;
BA_ "SignalLongName" SG_ 431 TransMinVoltReq "Transmission Minimum Voltage Request";
BA_ "SignalType" SG_ 431 TransMinVoltReq "UNM";
BA_ "VNSigAllNodes" SG_ 431 TDslPrtFltrIdlRgtnMdAtv 1;
BA_ "SignalLongName" SG_ 431 TDslPrtFltrIdlRgtnMdAtv "Transmission Diesel Particulate Filter Idle Regeneration Mode Active";
BA_ "SignalType" SG_ 431 TDslPrtFltrIdlRgtnMdAtv "BLN";
BA_ "VNSigAllNodes" SG_ 431 DrvlneTrqStabStat 1;
BA_ "SignalLongName" SG_ 431 DrvlneTrqStabStat "Driveline Torque Stability Status";
BA_ "SignalType" SG_ 431 DrvlneTrqStabStat "ENM";
BA_ "VNSigAllNodes" SG_ 431 TrnsTrqCnvCltCmdMdF 1;
BA_ "SignalLongName" SG_ 431 TrnsTrqCnvCltCmdMdF "Transmission Torque Converter Clutch Commanded Mode Failure";
BA_ "SignalType" SG_ 431 TrnsTrqCnvCltCmdMdF "BLN";
BA_ "VNSigAllNodes" SG_ 431 AutoTransGrSftDirectFl 1;
BA_ "SignalLongName" SG_ 431 AutoTransGrSftDirectFl "Automatic Transmission Gear Shift Direction Failure";
BA_ "SignalType" SG_ 431 AutoTransGrSftDirectFl "BLN";
BA_ "VNSigAllNodes" SG_ 431 AutoTransGrSftDirect 1;
BA_ "SignalLongName" SG_ 431 AutoTransGrSftDirect "Automatic Transmission Gear Shift Direction";
BA_ "SignalType" SG_ 431 AutoTransGrSftDirect "ENM";
BA_ "VNSigAllNodes" SG_ 431 TrnsTrqCnvCltCmndMd 1;
BA_ "SignalLongName" SG_ 431 TrnsTrqCnvCltCmndMd "Transmission Torque Converter Clutch Commanded Mode";
BA_ "GenSigStartValue" SG_ 431 TrnsTrqCnvCltCmndMd 7;
BA_ "SignalType" SG_ 431 TrnsTrqCnvCltCmndMd "ENM";
BA_ "VNSigAllNodes" SG_ 431 TrnsTrqCnvCltDsrSlp 1;
BA_ "SignalLongName" SG_ 431 TrnsTrqCnvCltDsrSlp "Transmission Torque Converter Clutch Desired Slip";
BA_ "SignalType" SG_ 431 TrnsTrqCnvCltDsrSlp "SNM";
BA_ "VNSigAllNodes" SG_ 431 TrnsStWntrMdOvrd 1;
BA_ "SignalLongName" SG_ 431 TrnsStWntrMdOvrd "Transmission State Winter Mode Override";
BA_ "SignalType" SG_ 431 TrnsStWntrMdOvrd "ENM";
BA_ "VNSigAllNodes" SG_ 431 TrnsStTwHaulMdOvrd 1;
BA_ "SignalLongName" SG_ 431 TrnsStTwHaulMdOvrd "Transmission State Tow Haul Mode Override";
BA_ "SignalType" SG_ 431 TrnsStTwHaulMdOvrd "ENM";
BA_ "VNSigAllNodes" SG_ 431 TrnsStSprtMdOvrd 1;
BA_ "SignalLongName" SG_ 431 TrnsStSprtMdOvrd "Transmission State Sport Mode Override";
BA_ "SignalType" SG_ 431 TrnsStSprtMdOvrd "ENM";
BA_ "VNSigAllNodes" SG_ 431 TrnsStEconMdOvrd 1;
BA_ "SignalLongName" SG_ 431 TrnsStEconMdOvrd "Transmission State Economy Mode Override";
BA_ "SignalType" SG_ 431 TrnsStEconMdOvrd "ENM";
BA_ "VNSigAllNodes" SG_ 431 TrnsInpCltchStat 1;
BA_ "SignalLongName" SG_ 431 TrnsInpCltchStat "Transmission Input Clutch Status";
BA_ "SignalType" SG_ 431 TrnsInpCltchStat "ENM";
BA_ "VNSigAllNodes" SG_ 431 TrnsAntcptdCrpTrqRRnV 1;
BA_ "SignalLongName" SG_ 431 TrnsAntcptdCrpTrqRRnV "Transmission Anticipated Creep Torque Reduced Range Validity";
BA_ "SignalType" SG_ 431 TrnsAntcptdCrpTrqRRnV "ENM";
BA_ "VNSigAllNodes" SG_ 431 TrnsAntcptdCrpTrqRRn 1;
BA_ "SignalLongName" SG_ 431 TrnsAntcptdCrpTrqRRn "Transmission Anticipated Creep Torque Reduced Range";
BA_ "SignalType" SG_ 431 TrnsAntcptdCrpTrqRRn "UNM";
BA_ "VNSigAllNodes" SG_ 431 TrnCltAdpAtv 1;
BA_ "SignalLongName" SG_ 431 TrnCltAdpAtv "Transmission Clutch Adaptation Active";
BA_ "SignalType" SG_ 431 TrnCltAdpAtv "BLN";
BA_ "VNSigAllNodes" SG_ 431 TransCrnkPermsnStat 1;
BA_ "SignalLongName" SG_ 431 TransCrnkPermsnStat "Transmission Crank Permission Status";
BA_ "SignalType" SG_ 431 TransCrnkPermsnStat "ENM";
BA_ "VNSigAllNodes" SG_ 431 WrmUpShftPtrn 1;
BA_ "SignalLongName" SG_ 431 WrmUpShftPtrn "Warm Up Shift Pattern Status";
BA_ "SignalType" SG_ 431 WrmUpShftPtrn "ENM";
BA_ "AppGenMsgCycleTime" BO_ 715 40;
BA_ "Prio" BO_ 715 0;
BA_ "MessageSubnet" BO_ 715 2;
BA_ "VNSigAllNodes" SG_ 715 ACCATC_SplREngInpR 1;
BA_ "PacketOrder" SG_ 715 ACCATC_SplREngInpR 4;
BA_ "SignalLongName" SG_ 715 ACCATC_SplREngInpR "Adaptive Cruise Control Axle Torque Command : Special Re-engagement Input Required";
BA_ "SignalType" SG_ 715 ACCATC_SplREngInpR "BLN";
BA_ "VNSigAllNodes" SG_ 715 ACCATC_DrvAstdGoSt 1;
BA_ "PacketOrder" SG_ 715 ACCATC_DrvAstdGoSt 3;
BA_ "SignalLongName" SG_ 715 ACCATC_DrvAstdGoSt "Adaptive Cruise Control Axle Torque Command : Driver Assisted Go State";
BA_ "SignalType" SG_ 715 ACCATC_DrvAstdGoSt "ENM";
BA_ "VNSigAllNodes" SG_ 715 ACCATC_AxlTrqRq 1;
BA_ "PacketOrder" SG_ 715 ACCATC_AxlTrqRq 6;
BA_ "SignalLongName" SG_ 715 ACCATC_AxlTrqRq "Adaptive Cruise Control Axle Torque Command : Axle Torque Request";
BA_ "SignalType" SG_ 715 ACCATC_AxlTrqRq "UNM";
BA_ "VNSigAllNodes" SG_ 715 ACCATC_ACCTyp 1;
BA_ "PacketOrder" SG_ 715 ACCATC_ACCTyp 2;
BA_ "SignalLongName" SG_ 715 ACCATC_ACCTyp "Adaptive Cruise Control Axle Torque Command : Adaptive Cruise Control Type";
BA_ "SignalType" SG_ 715 ACCATC_ACCTyp "ENM";
BA_ "VNSigAllNodes" SG_ 715 ACCATC_ACCAct 1;
BA_ "PacketOrder" SG_ 715 ACCATC_ACCAct 1;
BA_ "SignalLongName" SG_ 715 ACCATC_ACCAct "Adaptive Cruise Control Axle Torque Command : Adaptive Cruise Control Active";
BA_ "SignalType" SG_ 715 ACCATC_ACCAct "BLN";
BA_ "VNSigAllNodes" SG_ 715 ACCAxlTrqCmdProt 1;
BA_ "SignalLongName" SG_ 715 ACCAxlTrqCmdProt "Adaptive Cruise Control Axle torque Command Protection";
BA_ "SignalType" SG_ 715 ACCAxlTrqCmdProt "UNM";
BA_ "VNSigAllNodes" SG_ 715 ACCCmndAlvRlgCnt 1;
BA_ "SignalLongName" SG_ 715 ACCCmndAlvRlgCnt "Adaptive Cruise Control Command Alive Rolling Count";
BA_ "SignalType" SG_ 715 ACCCmndAlvRlgCnt "UNM";
BA_ "Prio" BO_ 1267 0;
BA_ "GenMsgSendType" BO_ 1267 0;
BA_ "GenMsgCycleTime" BO_ 1267 1000;
BA_ "MessageSubnet" BO_ 1267 2;
BA_ "VNSigAllNodes" SG_ 1267 VehMassNom 1;
BA_ "SignalLongName" SG_ 1267 VehMassNom "Vehicle Mass Nominal";
BA_ "SignalType" SG_ 1267 VehMassNom "UNM";
BA_ "Prio" BO_ 453 0;
BA_ "GenMsgSendType" BO_ 453 0;
BA_ "GenMsgCycleTime" BO_ 453 25;
BA_ "MessageSubnet" BO_ 453 2;
BA_ "VNSigAllNodes" SG_ 453 DrvIntndAxlTrqV 1;
BA_ "SignalLongName" SG_ 453 DrvIntndAxlTrqV "Driver Intended Axle Torque Validity";
BA_ "SignalType" SG_ 453 DrvIntndAxlTrqV "ENM";
BA_ "VNSigAllNodes" SG_ 453 DrvIntndAxlTrqMinV 1;
BA_ "SignalLongName" SG_ 453 DrvIntndAxlTrqMinV "Driver Intended Axle Torque Minimum Validity";
BA_ "SignalType" SG_ 453 DrvIntndAxlTrqMinV "ENM";
BA_ "VNSigAllNodes" SG_ 453 DrvIntndAxlTrqMin 1;
BA_ "SignalLongName" SG_ 453 DrvIntndAxlTrqMin "Driver Intended Axle Torque Minimum";
BA_ "SignalType" SG_ 453 DrvIntndAxlTrqMin "UNM";
BA_ "VNSigAllNodes" SG_ 453 DrvIntndAxlTrqMaxV 1;
BA_ "SignalLongName" SG_ 453 DrvIntndAxlTrqMaxV "Driver Intended Axle Torque Maximum Validity";
BA_ "SignalType" SG_ 453 DrvIntndAxlTrqMaxV "ENM";
BA_ "VNSigAllNodes" SG_ 453 DrvIntndAxlTrqMax 1;
BA_ "SignalLongName" SG_ 453 DrvIntndAxlTrqMax "Driver Intended Axle Torque Maximum";
BA_ "GenSigStartValue" SG_ 453 DrvIntndAxlTrqMax 32767;
BA_ "SignalType" SG_ 453 DrvIntndAxlTrqMax "UNM";
BA_ "VNSigAllNodes" SG_ 453 DrvIntndAxlTrq 1;
BA_ "SignalLongName" SG_ 453 DrvIntndAxlTrq "Driver Intended Axle Torque";
BA_ "GenSigStartValue" SG_ 453 DrvIntndAxlTrq 11267;
BA_ "SignalType" SG_ 453 DrvIntndAxlTrq "UNM";
BA_ "Prio" BO_ 452 0;
BA_ "GenMsgSendType" BO_ 452 0;
BA_ "GenMsgCycleTime" BO_ 452 25;
BA_ "MessageSubnet" BO_ 452 2;
BA_ "VNSigAllNodes" SG_ 452 FSpRgACCSwADdPVal 1;
BA_ "SignalLongName" SG_ 452 FSpRgACCSwADdPVal "Full Speed Range ACC Cruise Switch Action Detected Protection Value";
BA_ "SignalType" SG_ 452 FSpRgACCSwADdPVal "UNM";
BA_ "VNSigAllNodes" SG_ 452 FSpRgACCSwADdARC 1;
BA_ "SignalLongName" SG_ 452 FSpRgACCSwADdARC "Full Speed Range ACC Cruise Switch Action Detected Alive Rolling Count";
BA_ "SignalType" SG_ 452 FSpRgACCSwADdARC "UNM";
BA_ "VNSigAllNodes" SG_ 452 FSpRgACCSwADd 1;
BA_ "SignalLongName" SG_ 452 FSpRgACCSwADd "Full Speed Range ACC Cruise Switch Action Detected";
BA_ "SignalType" SG_ 452 FSpRgACCSwADd "BLN";
BA_ "VNSigAllNodes" SG_ 452 AutBrkAccActPsStRC 1;
BA_ "SignalLongName" SG_ 452 AutBrkAccActPsStRC "Autonomous Braking Accelerator Actual Position Status Rolling Count";
BA_ "SignalType" SG_ 452 AutBrkAccActPsStRC "UNM";
BA_ "VNSigAllNodes" SG_ 452 AutBrkAccActPsStPVal 1;
BA_ "SignalLongName" SG_ 452 AutBrkAccActPsStPVal "Autonomous Braking Accelerator Actual Position Status Protection Value";
BA_ "SignalType" SG_ 452 AutBrkAccActPsStPVal "UNM";
BA_ "VNSigAllNodes" SG_ 452 ABAAPS_AccPos 1;
BA_ "PacketOrder" SG_ 452 ABAAPS_AccPos 2;
BA_ "SignalLongName" SG_ 452 ABAAPS_AccPos "Autonomous Braking Accelerator Actual Position Status : Accelerator Position";
BA_ "SignalType" SG_ 452 ABAAPS_AccPos "UNM";
BA_ "VNSigAllNodes" SG_ 452 ABAAPS_AccPosV 1;
BA_ "PacketOrder" SG_ 452 ABAAPS_AccPosV 1;
BA_ "SignalLongName" SG_ 452 ABAAPS_AccPosV "Autonomous Braking Accelerator Actual Position Status : Accelerator Position Validity";
BA_ "SignalType" SG_ 452 ABAAPS_AccPosV "ENM";
BA_ "VNSigAllNodes" SG_ 452 ACCATCS_LmtgStat 1;
BA_ "PacketOrder" SG_ 452 ACCATCS_LmtgStat 2;
BA_ "SignalLongName" SG_ 452 ACCATCS_LmtgStat "Adaptive Cruise Control Axle Torque Command Status : Limiting Status";
BA_ "SignalType" SG_ 452 ACCATCS_LmtgStat "ENM";
BA_ "VNSigAllNodes" SG_ 452 ACCATCS_RqStat 1;
BA_ "PacketOrder" SG_ 452 ACCATCS_RqStat 1;
BA_ "SignalLongName" SG_ 452 ACCATCS_RqStat "Adaptive Cruise Control Axle Torque Command Status : Request Status";
BA_ "SignalType" SG_ 452 ACCATCS_RqStat "ENM";
BA_ "VNSigAllNodes" SG_ 452 RdLdNomAxlTrq 1;
BA_ "SignalLongName" SG_ 452 RdLdNomAxlTrq "Road Load Nominal Axle Torque";
BA_ "SignalType" SG_ 452 RdLdNomAxlTrq "UNM";
BA_ "VNSigAllNodes" SG_ 452 AccPdlOvrrdAtvProtVal 1;
BA_ "SignalLongName" SG_ 452 AccPdlOvrrdAtvProtVal "Accelerator Pedal Override Active Protection Value";
BA_ "SignalType" SG_ 452 AccPdlOvrrdAtvProtVal "UNM";
BA_ "VNSigAllNodes" SG_ 452 AccPdlOvrrdAtvARC 1;
BA_ "SignalLongName" SG_ 452 AccPdlOvrrdAtvARC "Accelerator Pedal Override Active Alive Rolling Count";
BA_ "SignalType" SG_ 452 AccPdlOvrrdAtvARC "UNM";
BA_ "VNSigAllNodes" SG_ 452 AccPdlOvrrdAtv 1;
BA_ "SignalLongName" SG_ 452 AccPdlOvrrdAtv "Accelerator Pedal Override Active";
BA_ "SignalType" SG_ 452 AccPdlOvrrdAtv "BLN";
BA_ "VNSigAllNodes" SG_ 452 CPSATCS_ReqStatus 1;
BA_ "PacketOrder" SG_ 452 CPSATCS_ReqStatus 1;
BA_ "SignalLongName" SG_ 452 CPSATCS_ReqStatus "Collision Preparation System Axle Torque Command Status : Request Status";
BA_ "SignalType" SG_ 452 CPSATCS_ReqStatus "ENM";
BA_ "VNSigAllNodes" SG_ 452 CPSATCS_LmtngStatus 1;
BA_ "PacketOrder" SG_ 452 CPSATCS_LmtngStatus 2;
BA_ "SignalLongName" SG_ 452 CPSATCS_LmtngStatus "Collision Preparation System Axle Torque Command Status : Limiting Status";
BA_ "SignalType" SG_ 452 CPSATCS_LmtngStatus "ENM";
BA_ "VNSigAllNodes" SG_ 452 RVBATCS_ReqStat 1;
BA_ "PacketOrder" SG_ 452 RVBATCS_ReqStat 1;
BA_ "SignalLongName" SG_ 452 RVBATCS_ReqStat "Rear Virtual Bumper Axle Torque Command Status : Request Status";
BA_ "SignalType" SG_ 452 RVBATCS_ReqStat "ENM";
BA_ "VNSigAllNodes" SG_ 452 RVBATCS_LmtngStat 1;
BA_ "PacketOrder" SG_ 452 RVBATCS_LmtngStat 2;
BA_ "SignalLongName" SG_ 452 RVBATCS_LmtngStat "Rear Virtual Bumper Axle Torque Command Status : Limiting Status";
BA_ "SignalType" SG_ 452 RVBATCS_LmtngStat "ENM";
BA_ "Prio" BO_ 1905 6;
BA_ "GenMsgSendType" BO_ 1905 0;
BA_ "GenMsgCycleTime" BO_ 1905 1000;
BA_ "MessageSubnet" BO_ 1905 2;
BA_ "VNSigAllNodes" SG_ 1905 DTCI_DTCFaultType_771 1;
BA_ "PacketOrder" SG_ 1905 DTCI_DTCFaultType_771 20;
BA_ "SignalLongName" SG_ 1905 DTCI_DTCFaultType_771 "Diagnostic Trouble Code Information Extended : Diagnostic Trouble Code Fault Type";
BA_ "SignalType" SG_ 1905 DTCI_DTCFaultType_771 "ENM";
BA_ "VNSigAllNodes" SG_ 1905 DTCI_CodeSupported_771 1;
BA_ "PacketOrder" SG_ 1905 DTCI_CodeSupported_771 19;
BA_ "SignalLongName" SG_ 1905 DTCI_CodeSupported_771 "Diagnostic Trouble Code Information Extended : Code Supported";
BA_ "SignalType" SG_ 1905 DTCI_CodeSupported_771 "BLN";
BA_ "VNSigAllNodes" SG_ 1905 DTCI_CurrentStatus_771 1;
BA_ "PacketOrder" SG_ 1905 DTCI_CurrentStatus_771 18;
BA_ "SignalLongName" SG_ 1905 DTCI_CurrentStatus_771 "Diagnostic Trouble Code Information Extended : Current Status";
BA_ "SignalType" SG_ 1905 DTCI_CurrentStatus_771 "BLN";
BA_ "VNSigAllNodes" SG_ 1905 DTCI_TstNPsdCdClrdSt_771 1;
BA_ "PacketOrder" SG_ 1905 DTCI_TstNPsdCdClrdSt_771 17;
BA_ "SignalLongName" SG_ 1905 DTCI_TstNPsdCdClrdSt_771 "Diagnostic Trouble Code Information Extended : Test Not Passed Since Code Cleared Status";
BA_ "SignalType" SG_ 1905 DTCI_TstNPsdCdClrdSt_771 "BLN";
BA_ "VNSigAllNodes" SG_ 1905 DTCI_TstFldCdClrdStat_771 1;
BA_ "PacketOrder" SG_ 1905 DTCI_TstFldCdClrdStat_771 16;
BA_ "SignalLongName" SG_ 1905 DTCI_TstFldCdClrdStat_771 "Diagnostic Trouble Code Information Extended : Test Failed Since Code Cleared Status";
BA_ "SignalType" SG_ 1905 DTCI_TstFldCdClrdStat_771 "BLN";
BA_ "VNSigAllNodes" SG_ 1905 DTCI_HistStat_771 1;
BA_ "PacketOrder" SG_ 1905 DTCI_HistStat_771 15;
BA_ "SignalLongName" SG_ 1905 DTCI_HistStat_771 "Diagnostic Trouble Code Information Extended : History Status";
BA_ "SignalType" SG_ 1905 DTCI_HistStat_771 "BLN";
BA_ "VNSigAllNodes" SG_ 1905 DTCI_TstNPsdPwrUpSt_771 1;
BA_ "PacketOrder" SG_ 1905 DTCI_TstNPsdPwrUpSt_771 14;
BA_ "SignalLongName" SG_ 1905 DTCI_TstNPsdPwrUpSt_771 "Diagnostic Trouble Code Information Extended : Test Not Passed Since Power Up Status";
BA_ "SignalType" SG_ 1905 DTCI_TstNPsdPwrUpSt_771 "BLN";
BA_ "VNSigAllNodes" SG_ 1905 DTCI_TstFldPwrUpSt_771 1;
BA_ "PacketOrder" SG_ 1905 DTCI_TstFldPwrUpSt_771 13;
BA_ "SignalLongName" SG_ 1905 DTCI_TstFldPwrUpSt_771 "Diagnostic Trouble Code Information Extended : Test Failed Since Power Up Status";
BA_ "SignalType" SG_ 1905 DTCI_TstFldPwrUpSt_771 "BLN";
BA_ "VNSigAllNodes" SG_ 1905 DTCI_WrnIndRqdSt_771 1;
BA_ "PacketOrder" SG_ 1905 DTCI_WrnIndRqdSt_771 12;
BA_ "SignalLongName" SG_ 1905 DTCI_WrnIndRqdSt_771 "Diagnostic Trouble Code Information Extended : Warning Indicator Requested Status";
BA_ "SignalType" SG_ 1905 DTCI_WrnIndRqdSt_771 "BLN";
BA_ "VNSigAllNodes" SG_ 1905 DTCI_DTCFailType_771 1;
BA_ "PacketOrder" SG_ 1905 DTCI_DTCFailType_771 11;
BA_ "SignalLongName" SG_ 1905 DTCI_DTCFailType_771 "Diagnostic Trouble Code Information Extended : Diagnostic Trouble Code Failure Type";
BA_ "SignalType" SG_ 1905 DTCI_DTCFailType_771 "UNM";
BA_ "VNSigAllNodes" SG_ 1905 DTCI_DTCNumber_771 1;
BA_ "PacketOrder" SG_ 1905 DTCI_DTCNumber_771 10;
BA_ "SignalLongName" SG_ 1905 DTCI_DTCNumber_771 "Diagnostic Trouble Code Information Extended : Diagnostic Trouble Code Number";
BA_ "SignalType" SG_ 1905 DTCI_DTCNumber_771 "UNM";
BA_ "VNSigAllNodes" SG_ 1905 DTCI_DTCSource_771 1;
BA_ "PacketOrder" SG_ 1905 DTCI_DTCSource_771 9;
BA_ "SignalLongName" SG_ 1905 DTCI_DTCSource_771 "Diagnostic Trouble Code Information Extended : Diagnostic Trouble Code Source";
BA_ "SignalType" SG_ 1905 DTCI_DTCSource_771 "UNM";
BA_ "VNSigAllNodes" SG_ 1905 DTCI_DTCTriggered_771 1;
BA_ "PacketOrder" SG_ 1905 DTCI_DTCTriggered_771 8;
BA_ "SignalLongName" SG_ 1905 DTCI_DTCTriggered_771 "Diagnostic Trouble Code Information Extended : Diagnostic Trouble Code Triggered";
BA_ "SignalType" SG_ 1905 DTCI_DTCTriggered_771 "BLN";
BA_ "VNSigAllNodes" SG_ 1905 DTCIUnused7_771 1;
BA_ "PacketOrder" SG_ 1905 DTCIUnused7_771 7;
BA_ "SignalLongName" SG_ 1905 DTCIUnused7_771 "Diagnostic Trouble Code Information Extended : Unused 7";
BA_ "SignalType" SG_ 1905 DTCIUnused7_771 "BLN";
BA_ "VNSigAllNodes" SG_ 1905 DTCIUnused6_771 1;
BA_ "PacketOrder" SG_ 1905 DTCIUnused6_771 6;
BA_ "SignalLongName" SG_ 1905 DTCIUnused6_771 "Diagnostic Trouble Code Information Extended : Unused 6";
BA_ "SignalType" SG_ 1905 DTCIUnused6_771 "BLN";
BA_ "VNSigAllNodes" SG_ 1905 DTCIUnused5_771 1;
BA_ "PacketOrder" SG_ 1905 DTCIUnused5_771 5;
BA_ "SignalLongName" SG_ 1905 DTCIUnused5_771 "Diagnostic Trouble Code Information Extended : Unused 5";
BA_ "SignalType" SG_ 1905 DTCIUnused5_771 "BLN";
BA_ "VNSigAllNodes" SG_ 1905 DTCIUnused4_771 1;
BA_ "PacketOrder" SG_ 1905 DTCIUnused4_771 4;
BA_ "SignalLongName" SG_ 1905 DTCIUnused4_771 "Diagnostic Trouble Code Information Extended : Unused 4";
BA_ "SignalType" SG_ 1905 DTCIUnused4_771 "BLN";
BA_ "VNSigAllNodes" SG_ 1905 DTCIUnused3_771 1;
BA_ "PacketOrder" SG_ 1905 DTCIUnused3_771 3;
BA_ "SignalLongName" SG_ 1905 DTCIUnused3_771 "Diagnostic Trouble Code Information Extended : Unused 3";
BA_ "SignalType" SG_ 1905 DTCIUnused3_771 "BLN";
BA_ "VNSigAllNodes" SG_ 1905 DTCIUnused2_771 1;
BA_ "PacketOrder" SG_ 1905 DTCIUnused2_771 2;
BA_ "SignalLongName" SG_ 1905 DTCIUnused2_771 "Diagnostic Trouble Code Information Extended : Unused 2";
BA_ "SignalType" SG_ 1905 DTCIUnused2_771 "BLN";
BA_ "VNSigAllNodes" SG_ 1905 DTCIUnused1_771 1;
BA_ "PacketOrder" SG_ 1905 DTCIUnused1_771 1;
BA_ "SignalLongName" SG_ 1905 DTCIUnused1_771 "Diagnostic Trouble Code Information Extended : Unused 1";
BA_ "SignalType" SG_ 1905 DTCIUnused1_771 "BLN";
BA_ "Prio" BO_ 1935 0;
BA_ "GenMsgSendType" BO_ 1935 0;
BA_ "GenMsgCycleTime" BO_ 1935 1000;
BA_ "MessageSubnet" BO_ 1935 2;
BA_ "VNSigAllNodes" SG_ 1935 DTCI_DTCSource_78F 1;
BA_ "PacketOrder" SG_ 1935 DTCI_DTCSource_78F 9;
BA_ "SignalLongName" SG_ 1935 DTCI_DTCSource_78F "Diagnostic Trouble Code Information Extended 78F : Diagnostic Trouble Code Source";
BA_ "SignalType" SG_ 1935 DTCI_DTCSource_78F "UNM";
BA_ "VNSigAllNodes" SG_ 1935 DTCI_DTCTriggered_78F 1;
BA_ "PacketOrder" SG_ 1935 DTCI_DTCTriggered_78F 8;
BA_ "SignalLongName" SG_ 1935 DTCI_DTCTriggered_78F "Diagnostic Trouble Code Information Extended 78F : Diagnostic Trouble Code Triggered";
BA_ "SignalType" SG_ 1935 DTCI_DTCTriggered_78F "BLN";
BA_ "VNSigAllNodes" SG_ 1935 DTCIUnused1_78F 1;
BA_ "PacketOrder" SG_ 1935 DTCIUnused1_78F 1;
BA_ "SignalLongName" SG_ 1935 DTCIUnused1_78F "Diagnostic Trouble Code Information Extended 78F : Unused 1";
BA_ "SignalType" SG_ 1935 DTCIUnused1_78F "BLN";
BA_ "VNSigAllNodes" SG_ 1935 DTCIUnused2_78F 1;
BA_ "PacketOrder" SG_ 1935 DTCIUnused2_78F 2;
BA_ "SignalLongName" SG_ 1935 DTCIUnused2_78F "Diagnostic Trouble Code Information Extended 78F : Unused 2";
BA_ "SignalType" SG_ 1935 DTCIUnused2_78F "BLN";
BA_ "VNSigAllNodes" SG_ 1935 DTCIUnused3_78F 1;
BA_ "PacketOrder" SG_ 1935 DTCIUnused3_78F 3;
BA_ "SignalLongName" SG_ 1935 DTCIUnused3_78F "Diagnostic Trouble Code Information Extended 78F : Unused 3";
BA_ "SignalType" SG_ 1935 DTCIUnused3_78F "BLN";
BA_ "VNSigAllNodes" SG_ 1935 DTCIUnused4_78F 1;
BA_ "PacketOrder" SG_ 1935 DTCIUnused4_78F 4;
BA_ "SignalLongName" SG_ 1935 DTCIUnused4_78F "Diagnostic Trouble Code Information Extended 78F : Unused 4";
BA_ "SignalType" SG_ 1935 DTCIUnused4_78F "BLN";
BA_ "VNSigAllNodes" SG_ 1935 DTCIUnused5_78F 1;
BA_ "PacketOrder" SG_ 1935 DTCIUnused5_78F 5;
BA_ "SignalLongName" SG_ 1935 DTCIUnused5_78F "Diagnostic Trouble Code Information Extended 78F : Unused 5";
BA_ "SignalType" SG_ 1935 DTCIUnused5_78F "BLN";
BA_ "VNSigAllNodes" SG_ 1935 DTCIUnused6_78F 1;
BA_ "PacketOrder" SG_ 1935 DTCIUnused6_78F 6;
BA_ "SignalLongName" SG_ 1935 DTCIUnused6_78F "Diagnostic Trouble Code Information Extended 78F : Unused 6";
BA_ "SignalType" SG_ 1935 DTCIUnused6_78F "BLN";
BA_ "VNSigAllNodes" SG_ 1935 DTCIUnused7_78F 1;
BA_ "PacketOrder" SG_ 1935 DTCIUnused7_78F 7;
BA_ "SignalLongName" SG_ 1935 DTCIUnused7_78F "Diagnostic Trouble Code Information Extended 78F : Unused 7";
BA_ "SignalType" SG_ 1935 DTCIUnused7_78F "BLN";
BA_ "VNSigAllNodes" SG_ 1935 DTCI_CodeSupported_78F 1;
BA_ "PacketOrder" SG_ 1935 DTCI_CodeSupported_78F 19;
BA_ "SignalLongName" SG_ 1935 DTCI_CodeSupported_78F "Diagnostic Trouble Code Information Extended 78F : Code Supported";
BA_ "SignalType" SG_ 1935 DTCI_CodeSupported_78F "BLN";
BA_ "VNSigAllNodes" SG_ 1935 DTCI_CurrentStatus_78F 1;
BA_ "PacketOrder" SG_ 1935 DTCI_CurrentStatus_78F 18;
BA_ "SignalLongName" SG_ 1935 DTCI_CurrentStatus_78F "Diagnostic Trouble Code Information Extended 78F : Current Status";
BA_ "SignalType" SG_ 1935 DTCI_CurrentStatus_78F "BLN";
BA_ "VNSigAllNodes" SG_ 1935 DTCI_DTCFaultType_78F 1;
BA_ "PacketOrder" SG_ 1935 DTCI_DTCFaultType_78F 20;
BA_ "SignalLongName" SG_ 1935 DTCI_DTCFaultType_78F "Diagnostic Trouble Code Information Extended 78F : Diagnostic Trouble Code Fault Type";
BA_ "SignalType" SG_ 1935 DTCI_DTCFaultType_78F "ENM";
BA_ "VNSigAllNodes" SG_ 1935 DTCI_TstFldCdClrdStat_78F 1;
BA_ "PacketOrder" SG_ 1935 DTCI_TstFldCdClrdStat_78F 16;
BA_ "SignalLongName" SG_ 1935 DTCI_TstFldCdClrdStat_78F "Diagnostic Trouble Code Information Extended 78F : Test Failed Since Code Cleared Status";
BA_ "SignalType" SG_ 1935 DTCI_TstFldCdClrdStat_78F "BLN";
BA_ "VNSigAllNodes" SG_ 1935 DTCI_TstNPsdCdClrdSt_78F 1;
BA_ "PacketOrder" SG_ 1935 DTCI_TstNPsdCdClrdSt_78F 17;
BA_ "SignalLongName" SG_ 1935 DTCI_TstNPsdCdClrdSt_78F "Diagnostic Trouble Code Information Extended 78F : Test Not Passed Since Code Cleared Status";
BA_ "SignalType" SG_ 1935 DTCI_TstNPsdCdClrdSt_78F "BLN";
BA_ "VNSigAllNodes" SG_ 1935 DTCI_HistStat_78F 1;
BA_ "PacketOrder" SG_ 1935 DTCI_HistStat_78F 15;
BA_ "SignalLongName" SG_ 1935 DTCI_HistStat_78F "Diagnostic Trouble Code Information Extended 78F : History Status";
BA_ "SignalType" SG_ 1935 DTCI_HistStat_78F "BLN";
BA_ "VNSigAllNodes" SG_ 1935 DTCI_TstNPsdPwrUpSt_78F 1;
BA_ "PacketOrder" SG_ 1935 DTCI_TstNPsdPwrUpSt_78F 14;
BA_ "SignalLongName" SG_ 1935 DTCI_TstNPsdPwrUpSt_78F "Diagnostic Trouble Code Information Extended 78F : Test Not Passed Since Power Up Status";
BA_ "SignalType" SG_ 1935 DTCI_TstNPsdPwrUpSt_78F "BLN";
BA_ "VNSigAllNodes" SG_ 1935 DTCI_TstFldPwrUpSt_78F 1;
BA_ "PacketOrder" SG_ 1935 DTCI_TstFldPwrUpSt_78F 13;
BA_ "SignalLongName" SG_ 1935 DTCI_TstFldPwrUpSt_78F "Diagnostic Trouble Code Information Extended 78F : Test Failed Since Power Up Status";
BA_ "SignalType" SG_ 1935 DTCI_TstFldPwrUpSt_78F "BLN";
BA_ "VNSigAllNodes" SG_ 1935 DTCI_WrnIndRqdSt_78F 1;
BA_ "PacketOrder" SG_ 1935 DTCI_WrnIndRqdSt_78F 12;
BA_ "SignalLongName" SG_ 1935 DTCI_WrnIndRqdSt_78F "Diagnostic Trouble Code Information Extended 78F : Warning Indicator Requested Status";
BA_ "SignalType" SG_ 1935 DTCI_WrnIndRqdSt_78F "BLN";
BA_ "VNSigAllNodes" SG_ 1935 DTCI_DTCFailType_78F 1;
BA_ "PacketOrder" SG_ 1935 DTCI_DTCFailType_78F 11;
BA_ "SignalLongName" SG_ 1935 DTCI_DTCFailType_78F "Diagnostic Trouble Code Information Extended 78F : Diagnostic Trouble Code Failure Type";
BA_ "SignalType" SG_ 1935 DTCI_DTCFailType_78F "UNM";
BA_ "VNSigAllNodes" SG_ 1935 DTCI_DTCNumber_78F 1;
BA_ "PacketOrder" SG_ 1935 DTCI_DTCNumber_78F 10;
BA_ "SignalLongName" SG_ 1935 DTCI_DTCNumber_78F "Diagnostic Trouble Code Information Extended 78F : Diagnostic Trouble Code Number";
BA_ "SignalType" SG_ 1935 DTCI_DTCNumber_78F "UNM";
BA_ "Prio" BO_ 1934 0;
BA_ "GenMsgSendType" BO_ 1934 0;
BA_ "GenMsgCycleTime" BO_ 1934 1000;
BA_ "MessageSubnet" BO_ 1934 2;
BA_ "VNSigAllNodes" SG_ 1934 DTCI_CodeSupported_78E 1;
BA_ "PacketOrder" SG_ 1934 DTCI_CodeSupported_78E 19;
BA_ "SignalLongName" SG_ 1934 DTCI_CodeSupported_78E "Diagnostic Trouble Code Information Extended 78E : Code Supported";
BA_ "SignalType" SG_ 1934 DTCI_CodeSupported_78E "BLN";
BA_ "VNSigAllNodes" SG_ 1934 DTCI_CurrentStatus_78E 1;
BA_ "PacketOrder" SG_ 1934 DTCI_CurrentStatus_78E 18;
BA_ "SignalLongName" SG_ 1934 DTCI_CurrentStatus_78E "Diagnostic Trouble Code Information Extended 78E : Current Status";
BA_ "SignalType" SG_ 1934 DTCI_CurrentStatus_78E "BLN";
BA_ "VNSigAllNodes" SG_ 1934 DTCI_DTCFailType_78E 1;
BA_ "PacketOrder" SG_ 1934 DTCI_DTCFailType_78E 11;
BA_ "SignalLongName" SG_ 1934 DTCI_DTCFailType_78E "Diagnostic Trouble Code Information Extended 78E : Diagnostic Trouble Code Failure Type";
BA_ "SignalType" SG_ 1934 DTCI_DTCFailType_78E "UNM";
BA_ "VNSigAllNodes" SG_ 1934 DTCI_DTCFaultType_78E 1;
BA_ "PacketOrder" SG_ 1934 DTCI_DTCFaultType_78E 20;
BA_ "SignalLongName" SG_ 1934 DTCI_DTCFaultType_78E "Diagnostic Trouble Code Information Extended 78E : Diagnostic Trouble Code Fault Type";
BA_ "SignalType" SG_ 1934 DTCI_DTCFaultType_78E "ENM";
BA_ "VNSigAllNodes" SG_ 1934 DTCI_DTCNumber_78E 1;
BA_ "PacketOrder" SG_ 1934 DTCI_DTCNumber_78E 10;
BA_ "SignalLongName" SG_ 1934 DTCI_DTCNumber_78E "Diagnostic Trouble Code Information Extended 78E : Diagnostic Trouble Code Number";
BA_ "SignalType" SG_ 1934 DTCI_DTCNumber_78E "UNM";
BA_ "VNSigAllNodes" SG_ 1934 DTCI_DTCSource_78E 1;
BA_ "PacketOrder" SG_ 1934 DTCI_DTCSource_78E 9;
BA_ "SignalLongName" SG_ 1934 DTCI_DTCSource_78E "Diagnostic Trouble Code Information Extended 78E : Diagnostic Trouble Code Source";
BA_ "SignalType" SG_ 1934 DTCI_DTCSource_78E "UNM";
BA_ "VNSigAllNodes" SG_ 1934 DTCI_DTCTriggered_78E 1;
BA_ "PacketOrder" SG_ 1934 DTCI_DTCTriggered_78E 8;
BA_ "SignalLongName" SG_ 1934 DTCI_DTCTriggered_78E "Diagnostic Trouble Code Information Extended 78E : Diagnostic Trouble Code Triggered";
BA_ "SignalType" SG_ 1934 DTCI_DTCTriggered_78E "BLN";
BA_ "VNSigAllNodes" SG_ 1934 DTCI_HistStat_78E 1;
BA_ "PacketOrder" SG_ 1934 DTCI_HistStat_78E 15;
BA_ "SignalLongName" SG_ 1934 DTCI_HistStat_78E "Diagnostic Trouble Code Information Extended 78E : History Status";
BA_ "SignalType" SG_ 1934 DTCI_HistStat_78E "BLN";
BA_ "VNSigAllNodes" SG_ 1934 DTCI_TstFldCdClrdStat_78E 1;
BA_ "PacketOrder" SG_ 1934 DTCI_TstFldCdClrdStat_78E 16;
BA_ "SignalLongName" SG_ 1934 DTCI_TstFldCdClrdStat_78E "Diagnostic Trouble Code Information Extended 78E : Test Failed Since Code Cleared Status";
BA_ "SignalType" SG_ 1934 DTCI_TstFldCdClrdStat_78E "BLN";
BA_ "VNSigAllNodes" SG_ 1934 DTCI_TstFldPwrUpSt_78E 1;
BA_ "PacketOrder" SG_ 1934 DTCI_TstFldPwrUpSt_78E 13;
BA_ "SignalLongName" SG_ 1934 DTCI_TstFldPwrUpSt_78E "Diagnostic Trouble Code Information Extended 78E : Test Failed Since Power Up Status";
BA_ "SignalType" SG_ 1934 DTCI_TstFldPwrUpSt_78E "BLN";
BA_ "VNSigAllNodes" SG_ 1934 DTCI_TstNPsdCdClrdSt_78E 1;
BA_ "PacketOrder" SG_ 1934 DTCI_TstNPsdCdClrdSt_78E 17;
BA_ "SignalLongName" SG_ 1934 DTCI_TstNPsdCdClrdSt_78E "Diagnostic Trouble Code Information Extended 78E : Test Not Passed Since Code Cleared Status";
BA_ "SignalType" SG_ 1934 DTCI_TstNPsdCdClrdSt_78E "BLN";
BA_ "VNSigAllNodes" SG_ 1934 DTCI_TstNPsdPwrUpSt_78E 1;
BA_ "PacketOrder" SG_ 1934 DTCI_TstNPsdPwrUpSt_78E 14;
BA_ "SignalLongName" SG_ 1934 DTCI_TstNPsdPwrUpSt_78E "Diagnostic Trouble Code Information Extended 78E : Test Not Passed Since Power Up Status";
BA_ "SignalType" SG_ 1934 DTCI_TstNPsdPwrUpSt_78E "BLN";
BA_ "VNSigAllNodes" SG_ 1934 DTCIUnused1_78E 1;
BA_ "PacketOrder" SG_ 1934 DTCIUnused1_78E 1;
BA_ "SignalLongName" SG_ 1934 DTCIUnused1_78E "Diagnostic Trouble Code Information Extended 78E : Unused 1";
BA_ "SignalType" SG_ 1934 DTCIUnused1_78E "BLN";
BA_ "VNSigAllNodes" SG_ 1934 DTCIUnused2_78E 1;
BA_ "PacketOrder" SG_ 1934 DTCIUnused2_78E 2;
BA_ "SignalLongName" SG_ 1934 DTCIUnused2_78E "Diagnostic Trouble Code Information Extended 78E : Unused 2";
BA_ "SignalType" SG_ 1934 DTCIUnused2_78E "BLN";
BA_ "VNSigAllNodes" SG_ 1934 DTCIUnused3_78E 1;
BA_ "PacketOrder" SG_ 1934 DTCIUnused3_78E 3;
BA_ "SignalLongName" SG_ 1934 DTCIUnused3_78E "Diagnostic Trouble Code Information Extended 78E : Unused 3";
BA_ "SignalType" SG_ 1934 DTCIUnused3_78E "BLN";
BA_ "VNSigAllNodes" SG_ 1934 DTCIUnused4_78E 1;
BA_ "PacketOrder" SG_ 1934 DTCIUnused4_78E 4;
BA_ "SignalLongName" SG_ 1934 DTCIUnused4_78E "Diagnostic Trouble Code Information Extended 78E : Unused 4";
BA_ "SignalType" SG_ 1934 DTCIUnused4_78E "BLN";
BA_ "VNSigAllNodes" SG_ 1934 DTCIUnused5_78E 1;
BA_ "PacketOrder" SG_ 1934 DTCIUnused5_78E 5;
BA_ "SignalLongName" SG_ 1934 DTCIUnused5_78E "Diagnostic Trouble Code Information Extended 78E : Unused 5";
BA_ "SignalType" SG_ 1934 DTCIUnused5_78E "BLN";
BA_ "VNSigAllNodes" SG_ 1934 DTCIUnused6_78E 1;
BA_ "PacketOrder" SG_ 1934 DTCIUnused6_78E 6;
BA_ "SignalLongName" SG_ 1934 DTCIUnused6_78E "Diagnostic Trouble Code Information Extended 78E : Unused 6";
BA_ "SignalType" SG_ 1934 DTCIUnused6_78E "BLN";
BA_ "VNSigAllNodes" SG_ 1934 DTCIUnused7_78E 1;
BA_ "PacketOrder" SG_ 1934 DTCIUnused7_78E 7;
BA_ "SignalLongName" SG_ 1934 DTCIUnused7_78E "Diagnostic Trouble Code Information Extended 78E : Unused 7";
BA_ "SignalType" SG_ 1934 DTCIUnused7_78E "BLN";
BA_ "VNSigAllNodes" SG_ 1934 DTCI_WrnIndRqdSt_78E 1;
BA_ "PacketOrder" SG_ 1934 DTCI_WrnIndRqdSt_78E 12;
BA_ "SignalLongName" SG_ 1934 DTCI_WrnIndRqdSt_78E "Diagnostic Trouble Code Information Extended 78E : Warning Indicator Requested Status";
BA_ "SignalType" SG_ 1934 DTCI_WrnIndRqdSt_78E "BLN";
BA_ "Prio" BO_ 1933 0;
BA_ "GenMsgSendType" BO_ 1933 0;
BA_ "GenMsgCycleTime" BO_ 1933 1000;
BA_ "MessageSubnet" BO_ 1933 2;
BA_ "VNSigAllNodes" SG_ 1933 DTCI_CodeSupported_78D 1;
BA_ "PacketOrder" SG_ 1933 DTCI_CodeSupported_78D 19;
BA_ "SignalLongName" SG_ 1933 DTCI_CodeSupported_78D "Diagnostic Trouble Code Information Extended 78D : Code Supported";
BA_ "SignalType" SG_ 1933 DTCI_CodeSupported_78D "BLN";
BA_ "VNSigAllNodes" SG_ 1933 DTCI_CurrentStatus_78D 1;
BA_ "PacketOrder" SG_ 1933 DTCI_CurrentStatus_78D 18;
BA_ "SignalLongName" SG_ 1933 DTCI_CurrentStatus_78D "Diagnostic Trouble Code Information Extended 78D : Current Status";
BA_ "SignalType" SG_ 1933 DTCI_CurrentStatus_78D "BLN";
BA_ "VNSigAllNodes" SG_ 1933 DTCI_DTCFailType_78D 1;
BA_ "PacketOrder" SG_ 1933 DTCI_DTCFailType_78D 11;
BA_ "SignalLongName" SG_ 1933 DTCI_DTCFailType_78D "Diagnostic Trouble Code Information Extended 78D : Diagnostic Trouble Code Failure Type";
BA_ "SignalType" SG_ 1933 DTCI_DTCFailType_78D "UNM";
BA_ "VNSigAllNodes" SG_ 1933 DTCI_DTCFaultType_78D 1;
BA_ "PacketOrder" SG_ 1933 DTCI_DTCFaultType_78D 20;
BA_ "SignalLongName" SG_ 1933 DTCI_DTCFaultType_78D "Diagnostic Trouble Code Information Extended 78D : Diagnostic Trouble Code Fault Type";
BA_ "SignalType" SG_ 1933 DTCI_DTCFaultType_78D "ENM";
BA_ "VNSigAllNodes" SG_ 1933 DTCI_DTCNumber_78D 1;
BA_ "PacketOrder" SG_ 1933 DTCI_DTCNumber_78D 10;
BA_ "SignalLongName" SG_ 1933 DTCI_DTCNumber_78D "Diagnostic Trouble Code Information Extended 78D : Diagnostic Trouble Code Number";
BA_ "SignalType" SG_ 1933 DTCI_DTCNumber_78D "UNM";
BA_ "VNSigAllNodes" SG_ 1933 DTCI_DTCSource_78D 1;
BA_ "PacketOrder" SG_ 1933 DTCI_DTCSource_78D 9;
BA_ "SignalLongName" SG_ 1933 DTCI_DTCSource_78D "Diagnostic Trouble Code Information Extended 78D : Diagnostic Trouble Code Source";
BA_ "SignalType" SG_ 1933 DTCI_DTCSource_78D "UNM";
BA_ "VNSigAllNodes" SG_ 1933 DTCI_DTCTriggered_78D 1;
BA_ "PacketOrder" SG_ 1933 DTCI_DTCTriggered_78D 8;
BA_ "SignalLongName" SG_ 1933 DTCI_DTCTriggered_78D "Diagnostic Trouble Code Information Extended 78D : Diagnostic Trouble Code Triggered";
BA_ "SignalType" SG_ 1933 DTCI_DTCTriggered_78D "BLN";
BA_ "VNSigAllNodes" SG_ 1933 DTCI_HistStat_78D 1;
BA_ "PacketOrder" SG_ 1933 DTCI_HistStat_78D 15;
BA_ "SignalLongName" SG_ 1933 DTCI_HistStat_78D "Diagnostic Trouble Code Information Extended 78D : History Status";
BA_ "SignalType" SG_ 1933 DTCI_HistStat_78D "BLN";
BA_ "VNSigAllNodes" SG_ 1933 DTCI_TstFldCdClrdStat_78D 1;
BA_ "PacketOrder" SG_ 1933 DTCI_TstFldCdClrdStat_78D 16;
BA_ "SignalLongName" SG_ 1933 DTCI_TstFldCdClrdStat_78D "Diagnostic Trouble Code Information Extended 78D : Test Failed Since Code Cleared Status";
BA_ "SignalType" SG_ 1933 DTCI_TstFldCdClrdStat_78D "BLN";
BA_ "VNSigAllNodes" SG_ 1933 DTCI_TstFldPwrUpSt_78D 1;
BA_ "PacketOrder" SG_ 1933 DTCI_TstFldPwrUpSt_78D 13;
BA_ "SignalLongName" SG_ 1933 DTCI_TstFldPwrUpSt_78D "Diagnostic Trouble Code Information Extended 78D : Test Failed Since Power Up Status";
BA_ "SignalType" SG_ 1933 DTCI_TstFldPwrUpSt_78D "BLN";
BA_ "VNSigAllNodes" SG_ 1933 DTCI_TstNPsdCdClrdSt_78D 1;
BA_ "PacketOrder" SG_ 1933 DTCI_TstNPsdCdClrdSt_78D 17;
BA_ "SignalLongName" SG_ 1933 DTCI_TstNPsdCdClrdSt_78D "Diagnostic Trouble Code Information Extended 78D : Test Not Passed Since Code Cleared Status";
BA_ "SignalType" SG_ 1933 DTCI_TstNPsdCdClrdSt_78D "BLN";
BA_ "VNSigAllNodes" SG_ 1933 DTCI_TstNPsdPwrUpSt_78D 1;
BA_ "PacketOrder" SG_ 1933 DTCI_TstNPsdPwrUpSt_78D 14;
BA_ "SignalLongName" SG_ 1933 DTCI_TstNPsdPwrUpSt_78D "Diagnostic Trouble Code Information Extended 78D : Test Not Passed Since Power Up Status";
BA_ "SignalType" SG_ 1933 DTCI_TstNPsdPwrUpSt_78D "BLN";
BA_ "VNSigAllNodes" SG_ 1933 DTCIUnused1_78D 1;
BA_ "PacketOrder" SG_ 1933 DTCIUnused1_78D 1;
BA_ "SignalLongName" SG_ 1933 DTCIUnused1_78D "Diagnostic Trouble Code Information Extended 78D : Unused 1";
BA_ "SignalType" SG_ 1933 DTCIUnused1_78D "BLN";
BA_ "VNSigAllNodes" SG_ 1933 DTCIUnused2_78D 1;
BA_ "PacketOrder" SG_ 1933 DTCIUnused2_78D 2;
BA_ "SignalLongName" SG_ 1933 DTCIUnused2_78D "Diagnostic Trouble Code Information Extended 78D : Unused 2";
BA_ "SignalType" SG_ 1933 DTCIUnused2_78D "BLN";
BA_ "VNSigAllNodes" SG_ 1933 DTCIUnused3_78D 1;
BA_ "PacketOrder" SG_ 1933 DTCIUnused3_78D 3;
BA_ "SignalLongName" SG_ 1933 DTCIUnused3_78D "Diagnostic Trouble Code Information Extended 78D : Unused 3";
BA_ "SignalType" SG_ 1933 DTCIUnused3_78D "BLN";
BA_ "VNSigAllNodes" SG_ 1933 DTCIUnused4_78D 1;
BA_ "PacketOrder" SG_ 1933 DTCIUnused4_78D 4;
BA_ "SignalLongName" SG_ 1933 DTCIUnused4_78D "Diagnostic Trouble Code Information Extended 78D : Unused 4";
BA_ "SignalType" SG_ 1933 DTCIUnused4_78D "BLN";
BA_ "VNSigAllNodes" SG_ 1933 DTCIUnused5_78D 1;
BA_ "PacketOrder" SG_ 1933 DTCIUnused5_78D 5;
BA_ "SignalLongName" SG_ 1933 DTCIUnused5_78D "Diagnostic Trouble Code Information Extended 78D : Unused 5";
BA_ "SignalType" SG_ 1933 DTCIUnused5_78D "BLN";
BA_ "VNSigAllNodes" SG_ 1933 DTCIUnused6_78D 1;
BA_ "PacketOrder" SG_ 1933 DTCIUnused6_78D 6;
BA_ "SignalLongName" SG_ 1933 DTCIUnused6_78D "Diagnostic Trouble Code Information Extended 78D : Unused 6";
BA_ "SignalType" SG_ 1933 DTCIUnused6_78D "BLN";
BA_ "VNSigAllNodes" SG_ 1933 DTCIUnused7_78D 1;
BA_ "PacketOrder" SG_ 1933 DTCIUnused7_78D 7;
BA_ "SignalLongName" SG_ 1933 DTCIUnused7_78D "Diagnostic Trouble Code Information Extended 78D : Unused 7";
BA_ "SignalType" SG_ 1933 DTCIUnused7_78D "BLN";
BA_ "VNSigAllNodes" SG_ 1933 DTCI_WrnIndRqdSt_78D 1;
BA_ "PacketOrder" SG_ 1933 DTCI_WrnIndRqdSt_78D 12;
BA_ "SignalLongName" SG_ 1933 DTCI_WrnIndRqdSt_78D "Diagnostic Trouble Code Information Extended 78D : Warning Indicator Requested Status";
BA_ "SignalType" SG_ 1933 DTCI_WrnIndRqdSt_78D "BLN";
BA_ "Prio" BO_ 1932 0;
BA_ "GenMsgSendType" BO_ 1932 0;
BA_ "GenMsgCycleTime" BO_ 1932 1000;
BA_ "MessageSubnet" BO_ 1932 2;
BA_ "VNSigAllNodes" SG_ 1932 DTCI_CodeSupported_78C 1;
BA_ "PacketOrder" SG_ 1932 DTCI_CodeSupported_78C 19;
BA_ "SignalLongName" SG_ 1932 DTCI_CodeSupported_78C "Diagnostic Trouble Code Information Extended 78C : Code Supported";
BA_ "SignalType" SG_ 1932 DTCI_CodeSupported_78C "BLN";
BA_ "VNSigAllNodes" SG_ 1932 DTCI_CurrentStatus_78C 1;
BA_ "PacketOrder" SG_ 1932 DTCI_CurrentStatus_78C 18;
BA_ "SignalLongName" SG_ 1932 DTCI_CurrentStatus_78C "Diagnostic Trouble Code Information Extended 78C : Current Status";
BA_ "SignalType" SG_ 1932 DTCI_CurrentStatus_78C "BLN";
BA_ "VNSigAllNodes" SG_ 1932 DTCI_DTCFailType_78C 1;
BA_ "PacketOrder" SG_ 1932 DTCI_DTCFailType_78C 11;
BA_ "SignalLongName" SG_ 1932 DTCI_DTCFailType_78C "Diagnostic Trouble Code Information Extended 78C : Diagnostic Trouble Code Failure Type";
BA_ "SignalType" SG_ 1932 DTCI_DTCFailType_78C "UNM";
BA_ "VNSigAllNodes" SG_ 1932 DTCI_DTCFaultType_78C 1;
BA_ "PacketOrder" SG_ 1932 DTCI_DTCFaultType_78C 20;
BA_ "SignalLongName" SG_ 1932 DTCI_DTCFaultType_78C "Diagnostic Trouble Code Information Extended 78C : Diagnostic Trouble Code Fault Type";
BA_ "SignalType" SG_ 1932 DTCI_DTCFaultType_78C "ENM";
BA_ "VNSigAllNodes" SG_ 1932 DTCI_DTCNumber_78C 1;
BA_ "PacketOrder" SG_ 1932 DTCI_DTCNumber_78C 10;
BA_ "SignalLongName" SG_ 1932 DTCI_DTCNumber_78C "Diagnostic Trouble Code Information Extended 78C : Diagnostic Trouble Code Number";
BA_ "SignalType" SG_ 1932 DTCI_DTCNumber_78C "UNM";
BA_ "VNSigAllNodes" SG_ 1932 DTCI_DTCSource_78C 1;
BA_ "PacketOrder" SG_ 1932 DTCI_DTCSource_78C 9;
BA_ "SignalLongName" SG_ 1932 DTCI_DTCSource_78C "Diagnostic Trouble Code Information Extended 78C : Diagnostic Trouble Code Source";
BA_ "SignalType" SG_ 1932 DTCI_DTCSource_78C "UNM";
BA_ "VNSigAllNodes" SG_ 1932 DTCI_DTCTriggered_78C 1;
BA_ "PacketOrder" SG_ 1932 DTCI_DTCTriggered_78C 8;
BA_ "SignalLongName" SG_ 1932 DTCI_DTCTriggered_78C "Diagnostic Trouble Code Information Extended 78C : Diagnostic Trouble Code Triggered";
BA_ "SignalType" SG_ 1932 DTCI_DTCTriggered_78C "BLN";
BA_ "VNSigAllNodes" SG_ 1932 DTCI_HistStat_78C 1;
BA_ "PacketOrder" SG_ 1932 DTCI_HistStat_78C 15;
BA_ "SignalLongName" SG_ 1932 DTCI_HistStat_78C "Diagnostic Trouble Code Information Extended 78C : History Status";
BA_ "SignalType" SG_ 1932 DTCI_HistStat_78C "BLN";
BA_ "VNSigAllNodes" SG_ 1932 DTCI_TstFldCdClrdStat_78C 1;
BA_ "PacketOrder" SG_ 1932 DTCI_TstFldCdClrdStat_78C 16;
BA_ "SignalLongName" SG_ 1932 DTCI_TstFldCdClrdStat_78C "Diagnostic Trouble Code Information Extended 78C : Test Failed Since Code Cleared Status";
BA_ "SignalType" SG_ 1932 DTCI_TstFldCdClrdStat_78C "BLN";
BA_ "VNSigAllNodes" SG_ 1932 DTCI_TstFldPwrUpSt_78C 1;
BA_ "PacketOrder" SG_ 1932 DTCI_TstFldPwrUpSt_78C 13;
BA_ "SignalLongName" SG_ 1932 DTCI_TstFldPwrUpSt_78C "Diagnostic Trouble Code Information Extended 78C : Test Failed Since Power Up Status";
BA_ "SignalType" SG_ 1932 DTCI_TstFldPwrUpSt_78C "BLN";
BA_ "VNSigAllNodes" SG_ 1932 DTCI_TstNPsdCdClrdSt_78C 1;
BA_ "PacketOrder" SG_ 1932 DTCI_TstNPsdCdClrdSt_78C 17;
BA_ "SignalLongName" SG_ 1932 DTCI_TstNPsdCdClrdSt_78C "Diagnostic Trouble Code Information Extended 78C : Test Not Passed Since Code Cleared Status";
BA_ "SignalType" SG_ 1932 DTCI_TstNPsdCdClrdSt_78C "BLN";
BA_ "VNSigAllNodes" SG_ 1932 DTCI_TstNPsdPwrUpSt_78C 1;
BA_ "PacketOrder" SG_ 1932 DTCI_TstNPsdPwrUpSt_78C 14;
BA_ "SignalLongName" SG_ 1932 DTCI_TstNPsdPwrUpSt_78C "Diagnostic Trouble Code Information Extended 78C : Test Not Passed Since Power Up Status";
BA_ "SignalType" SG_ 1932 DTCI_TstNPsdPwrUpSt_78C "BLN";
BA_ "VNSigAllNodes" SG_ 1932 DTCIUnused1_78C 1;
BA_ "PacketOrder" SG_ 1932 DTCIUnused1_78C 1;
BA_ "SignalLongName" SG_ 1932 DTCIUnused1_78C "Diagnostic Trouble Code Information Extended 78C : Unused 1";
BA_ "SignalType" SG_ 1932 DTCIUnused1_78C "BLN";
BA_ "VNSigAllNodes" SG_ 1932 DTCIUnused2_78C 1;
BA_ "PacketOrder" SG_ 1932 DTCIUnused2_78C 2;
BA_ "SignalLongName" SG_ 1932 DTCIUnused2_78C "Diagnostic Trouble Code Information Extended 78C : Unused 2";
BA_ "SignalType" SG_ 1932 DTCIUnused2_78C "BLN";
BA_ "VNSigAllNodes" SG_ 1932 DTCIUnused3_78C 1;
BA_ "PacketOrder" SG_ 1932 DTCIUnused3_78C 3;
BA_ "SignalLongName" SG_ 1932 DTCIUnused3_78C "Diagnostic Trouble Code Information Extended 78C : Unused 3";
BA_ "SignalType" SG_ 1932 DTCIUnused3_78C "BLN";
BA_ "VNSigAllNodes" SG_ 1932 DTCIUnused4_78C 1;
BA_ "PacketOrder" SG_ 1932 DTCIUnused4_78C 4;
BA_ "SignalLongName" SG_ 1932 DTCIUnused4_78C "Diagnostic Trouble Code Information Extended 78C : Unused 4";
BA_ "SignalType" SG_ 1932 DTCIUnused4_78C "BLN";
BA_ "VNSigAllNodes" SG_ 1932 DTCIUnused5_78C 1;
BA_ "PacketOrder" SG_ 1932 DTCIUnused5_78C 5;
BA_ "SignalLongName" SG_ 1932 DTCIUnused5_78C "Diagnostic Trouble Code Information Extended 78C : Unused 5";
BA_ "SignalType" SG_ 1932 DTCIUnused5_78C "BLN";
BA_ "VNSigAllNodes" SG_ 1932 DTCIUnused6_78C 1;
BA_ "PacketOrder" SG_ 1932 DTCIUnused6_78C 6;
BA_ "SignalLongName" SG_ 1932 DTCIUnused6_78C "Diagnostic Trouble Code Information Extended 78C : Unused 6";
BA_ "SignalType" SG_ 1932 DTCIUnused6_78C "BLN";
BA_ "VNSigAllNodes" SG_ 1932 DTCIUnused7_78C 1;
BA_ "PacketOrder" SG_ 1932 DTCIUnused7_78C 7;
BA_ "SignalLongName" SG_ 1932 DTCIUnused7_78C "Diagnostic Trouble Code Information Extended 78C : Unused 7";
BA_ "SignalType" SG_ 1932 DTCIUnused7_78C "BLN";
BA_ "VNSigAllNodes" SG_ 1932 DTCI_WrnIndRqdSt_78C 1;
BA_ "PacketOrder" SG_ 1932 DTCI_WrnIndRqdSt_78C 12;
BA_ "SignalLongName" SG_ 1932 DTCI_WrnIndRqdSt_78C "Diagnostic Trouble Code Information Extended 78C : Warning Indicator Requested Status";
BA_ "SignalType" SG_ 1932 DTCI_WrnIndRqdSt_78C "BLN";
BA_ "Prio" BO_ 1931 0;
BA_ "GenMsgSendType" BO_ 1931 0;
BA_ "GenMsgCycleTime" BO_ 1931 1000;
BA_ "MessageSubnet" BO_ 1931 2;
BA_ "VNSigAllNodes" SG_ 1931 DTCI_CodeSupported_78B 1;
BA_ "PacketOrder" SG_ 1931 DTCI_CodeSupported_78B 19;
BA_ "SignalLongName" SG_ 1931 DTCI_CodeSupported_78B "Diagnostic Trouble Code Information Extended 78B : Code Supported";
BA_ "SignalType" SG_ 1931 DTCI_CodeSupported_78B "BLN";
BA_ "VNSigAllNodes" SG_ 1931 DTCI_CurrentStatus_78B 1;
BA_ "PacketOrder" SG_ 1931 DTCI_CurrentStatus_78B 18;
BA_ "SignalLongName" SG_ 1931 DTCI_CurrentStatus_78B "Diagnostic Trouble Code Information Extended 78B : Current Status";
BA_ "SignalType" SG_ 1931 DTCI_CurrentStatus_78B "BLN";
BA_ "VNSigAllNodes" SG_ 1931 DTCI_DTCFailType_78B 1;
BA_ "PacketOrder" SG_ 1931 DTCI_DTCFailType_78B 11;
BA_ "SignalLongName" SG_ 1931 DTCI_DTCFailType_78B "Diagnostic Trouble Code Information Extended 78B : Diagnostic Trouble Code Failure Type";
BA_ "SignalType" SG_ 1931 DTCI_DTCFailType_78B "UNM";
BA_ "VNSigAllNodes" SG_ 1931 DTCI_DTCFaultType_78B 1;
BA_ "PacketOrder" SG_ 1931 DTCI_DTCFaultType_78B 20;
BA_ "SignalLongName" SG_ 1931 DTCI_DTCFaultType_78B "Diagnostic Trouble Code Information Extended 78B : Diagnostic Trouble Code Fault Type";
BA_ "SignalType" SG_ 1931 DTCI_DTCFaultType_78B "ENM";
BA_ "VNSigAllNodes" SG_ 1931 DTCI_DTCNumber_78B 1;
BA_ "PacketOrder" SG_ 1931 DTCI_DTCNumber_78B 10;
BA_ "SignalLongName" SG_ 1931 DTCI_DTCNumber_78B "Diagnostic Trouble Code Information Extended 78B : Diagnostic Trouble Code Number";
BA_ "SignalType" SG_ 1931 DTCI_DTCNumber_78B "UNM";
BA_ "VNSigAllNodes" SG_ 1931 DTCI_DTCSource_78B 1;
BA_ "PacketOrder" SG_ 1931 DTCI_DTCSource_78B 9;
BA_ "SignalLongName" SG_ 1931 DTCI_DTCSource_78B "Diagnostic Trouble Code Information Extended 78B : Diagnostic Trouble Code Source";
BA_ "SignalType" SG_ 1931 DTCI_DTCSource_78B "UNM";
BA_ "VNSigAllNodes" SG_ 1931 DTCI_DTCTriggered_78B 1;
BA_ "PacketOrder" SG_ 1931 DTCI_DTCTriggered_78B 8;
BA_ "SignalLongName" SG_ 1931 DTCI_DTCTriggered_78B "Diagnostic Trouble Code Information Extended 78B : Diagnostic Trouble Code Triggered";
BA_ "SignalType" SG_ 1931 DTCI_DTCTriggered_78B "BLN";
BA_ "VNSigAllNodes" SG_ 1931 DTCI_HistStat_78B 1;
BA_ "PacketOrder" SG_ 1931 DTCI_HistStat_78B 15;
BA_ "SignalLongName" SG_ 1931 DTCI_HistStat_78B "Diagnostic Trouble Code Information Extended 78B : History Status";
BA_ "SignalType" SG_ 1931 DTCI_HistStat_78B "BLN";
BA_ "VNSigAllNodes" SG_ 1931 DTCI_TstFldCdClrdStat_78B 1;
BA_ "PacketOrder" SG_ 1931 DTCI_TstFldCdClrdStat_78B 16;
BA_ "SignalLongName" SG_ 1931 DTCI_TstFldCdClrdStat_78B "Diagnostic Trouble Code Information Extended 78B : Test Failed Since Code Cleared Status";
BA_ "SignalType" SG_ 1931 DTCI_TstFldCdClrdStat_78B "BLN";
BA_ "VNSigAllNodes" SG_ 1931 DTCI_TstFldPwrUpSt_78B 1;
BA_ "PacketOrder" SG_ 1931 DTCI_TstFldPwrUpSt_78B 13;
BA_ "SignalLongName" SG_ 1931 DTCI_TstFldPwrUpSt_78B "Diagnostic Trouble Code Information Extended 78B : Test Failed Since Power Up Status";
BA_ "SignalType" SG_ 1931 DTCI_TstFldPwrUpSt_78B "BLN";
BA_ "VNSigAllNodes" SG_ 1931 DTCI_TstNPsdCdClrdSt_78B 1;
BA_ "PacketOrder" SG_ 1931 DTCI_TstNPsdCdClrdSt_78B 17;
BA_ "SignalLongName" SG_ 1931 DTCI_TstNPsdCdClrdSt_78B "Diagnostic Trouble Code Information Extended 78B : Test Not Passed Since Code Cleared Status";
BA_ "SignalType" SG_ 1931 DTCI_TstNPsdCdClrdSt_78B "BLN";
BA_ "VNSigAllNodes" SG_ 1931 DTCI_TstNPsdPwrUpSt_78B 1;
BA_ "PacketOrder" SG_ 1931 DTCI_TstNPsdPwrUpSt_78B 14;
BA_ "SignalLongName" SG_ 1931 DTCI_TstNPsdPwrUpSt_78B "Diagnostic Trouble Code Information Extended 78B : Test Not Passed Since Power Up Status";
BA_ "SignalType" SG_ 1931 DTCI_TstNPsdPwrUpSt_78B "BLN";
BA_ "VNSigAllNodes" SG_ 1931 DTCIUnused1_78B 1;
BA_ "PacketOrder" SG_ 1931 DTCIUnused1_78B 1;
BA_ "SignalLongName" SG_ 1931 DTCIUnused1_78B "Diagnostic Trouble Code Information Extended 78B : Unused 1";
BA_ "SignalType" SG_ 1931 DTCIUnused1_78B "BLN";
BA_ "VNSigAllNodes" SG_ 1931 DTCIUnused2_78B 1;
BA_ "PacketOrder" SG_ 1931 DTCIUnused2_78B 2;
BA_ "SignalLongName" SG_ 1931 DTCIUnused2_78B "Diagnostic Trouble Code Information Extended 78B : Unused 2";
BA_ "SignalType" SG_ 1931 DTCIUnused2_78B "BLN";
BA_ "VNSigAllNodes" SG_ 1931 DTCIUnused3_78B 1;
BA_ "PacketOrder" SG_ 1931 DTCIUnused3_78B 3;
BA_ "SignalLongName" SG_ 1931 DTCIUnused3_78B "Diagnostic Trouble Code Information Extended 78B : Unused 3";
BA_ "SignalType" SG_ 1931 DTCIUnused3_78B "BLN";
BA_ "VNSigAllNodes" SG_ 1931 DTCIUnused4_78B 1;
BA_ "PacketOrder" SG_ 1931 DTCIUnused4_78B 4;
BA_ "SignalLongName" SG_ 1931 DTCIUnused4_78B "Diagnostic Trouble Code Information Extended 78B : Unused 4";
BA_ "SignalType" SG_ 1931 DTCIUnused4_78B "BLN";
BA_ "VNSigAllNodes" SG_ 1931 DTCIUnused5_78B 1;
BA_ "PacketOrder" SG_ 1931 DTCIUnused5_78B 5;
BA_ "SignalLongName" SG_ 1931 DTCIUnused5_78B "Diagnostic Trouble Code Information Extended 78B : Unused 5";
BA_ "SignalType" SG_ 1931 DTCIUnused5_78B "BLN";
BA_ "VNSigAllNodes" SG_ 1931 DTCIUnused6_78B 1;
BA_ "PacketOrder" SG_ 1931 DTCIUnused6_78B 6;
BA_ "SignalLongName" SG_ 1931 DTCIUnused6_78B "Diagnostic Trouble Code Information Extended 78B : Unused 6";
BA_ "SignalType" SG_ 1931 DTCIUnused6_78B "BLN";
BA_ "VNSigAllNodes" SG_ 1931 DTCIUnused7_78B 1;
BA_ "PacketOrder" SG_ 1931 DTCIUnused7_78B 7;
BA_ "SignalLongName" SG_ 1931 DTCIUnused7_78B "Diagnostic Trouble Code Information Extended 78B : Unused 7";
BA_ "SignalType" SG_ 1931 DTCIUnused7_78B "BLN";
BA_ "VNSigAllNodes" SG_ 1931 DTCI_WrnIndRqdSt_78B 1;
BA_ "PacketOrder" SG_ 1931 DTCI_WrnIndRqdSt_78B 12;
BA_ "SignalLongName" SG_ 1931 DTCI_WrnIndRqdSt_78B "Diagnostic Trouble Code Information Extended 78B : Warning Indicator Requested Status";
BA_ "SignalType" SG_ 1931 DTCI_WrnIndRqdSt_78B "BLN";
BA_ "Prio" BO_ 1930 0;
BA_ "GenMsgSendType" BO_ 1930 0;
BA_ "GenMsgCycleTime" BO_ 1930 1000;
BA_ "MessageSubnet" BO_ 1930 2;
BA_ "VNSigAllNodes" SG_ 1930 DTCI_CodeSupported_78A 1;
BA_ "PacketOrder" SG_ 1930 DTCI_CodeSupported_78A 19;
BA_ "SignalLongName" SG_ 1930 DTCI_CodeSupported_78A "Diagnostic Trouble Code Information Extended 78A : Code Supported";
BA_ "SignalType" SG_ 1930 DTCI_CodeSupported_78A "BLN";
BA_ "VNSigAllNodes" SG_ 1930 DTCI_CurrentStatus_78A 1;
BA_ "PacketOrder" SG_ 1930 DTCI_CurrentStatus_78A 18;
BA_ "SignalLongName" SG_ 1930 DTCI_CurrentStatus_78A "Diagnostic Trouble Code Information Extended 78A : Current Status";
BA_ "SignalType" SG_ 1930 DTCI_CurrentStatus_78A "BLN";
BA_ "VNSigAllNodes" SG_ 1930 DTCI_DTCFailType_78A 1;
BA_ "PacketOrder" SG_ 1930 DTCI_DTCFailType_78A 11;
BA_ "SignalLongName" SG_ 1930 DTCI_DTCFailType_78A "Diagnostic Trouble Code Information Extended 78A : Diagnostic Trouble Code Failure Type";
BA_ "SignalType" SG_ 1930 DTCI_DTCFailType_78A "UNM";
BA_ "VNSigAllNodes" SG_ 1930 DTCI_DTCFaultType_78A 1;
BA_ "PacketOrder" SG_ 1930 DTCI_DTCFaultType_78A 20;
BA_ "SignalLongName" SG_ 1930 DTCI_DTCFaultType_78A "Diagnostic Trouble Code Information Extended 78A : Diagnostic Trouble Code Fault Type";
BA_ "SignalType" SG_ 1930 DTCI_DTCFaultType_78A "ENM";
BA_ "VNSigAllNodes" SG_ 1930 DTCI_DTCNumber_78A 1;
BA_ "PacketOrder" SG_ 1930 DTCI_DTCNumber_78A 10;
BA_ "SignalLongName" SG_ 1930 DTCI_DTCNumber_78A "Diagnostic Trouble Code Information Extended 78A : Diagnostic Trouble Code Number";
BA_ "SignalType" SG_ 1930 DTCI_DTCNumber_78A "UNM";
BA_ "VNSigAllNodes" SG_ 1930 DTCI_DTCSource_78A 1;
BA_ "PacketOrder" SG_ 1930 DTCI_DTCSource_78A 9;
BA_ "SignalLongName" SG_ 1930 DTCI_DTCSource_78A "Diagnostic Trouble Code Information Extended 78A : Diagnostic Trouble Code Source";
BA_ "SignalType" SG_ 1930 DTCI_DTCSource_78A "UNM";
BA_ "VNSigAllNodes" SG_ 1930 DTCI_DTCTriggered_78A 1;
BA_ "PacketOrder" SG_ 1930 DTCI_DTCTriggered_78A 8;
BA_ "SignalLongName" SG_ 1930 DTCI_DTCTriggered_78A "Diagnostic Trouble Code Information Extended 78A : Diagnostic Trouble Code Triggered";
BA_ "SignalType" SG_ 1930 DTCI_DTCTriggered_78A "BLN";
BA_ "VNSigAllNodes" SG_ 1930 DTCI_HistStat_78A 1;
BA_ "PacketOrder" SG_ 1930 DTCI_HistStat_78A 15;
BA_ "SignalLongName" SG_ 1930 DTCI_HistStat_78A "Diagnostic Trouble Code Information Extended 78A : History Status";
BA_ "SignalType" SG_ 1930 DTCI_HistStat_78A "BLN";
BA_ "VNSigAllNodes" SG_ 1930 DTCI_TstFldCdClrdStat_78A 1;
BA_ "PacketOrder" SG_ 1930 DTCI_TstFldCdClrdStat_78A 16;
BA_ "SignalLongName" SG_ 1930 DTCI_TstFldCdClrdStat_78A "Diagnostic Trouble Code Information Extended 78A : Test Failed Since Code Cleared Status";
BA_ "SignalType" SG_ 1930 DTCI_TstFldCdClrdStat_78A "BLN";
BA_ "VNSigAllNodes" SG_ 1930 DTCI_TstFldPwrUpSt_78A 1;
BA_ "PacketOrder" SG_ 1930 DTCI_TstFldPwrUpSt_78A 13;
BA_ "SignalLongName" SG_ 1930 DTCI_TstFldPwrUpSt_78A "Diagnostic Trouble Code Information Extended 78A : Test Failed Since Power Up Status";
BA_ "SignalType" SG_ 1930 DTCI_TstFldPwrUpSt_78A "BLN";
BA_ "VNSigAllNodes" SG_ 1930 DTCI_TstNPsdCdClrdSt_78A 1;
BA_ "PacketOrder" SG_ 1930 DTCI_TstNPsdCdClrdSt_78A 17;
BA_ "SignalLongName" SG_ 1930 DTCI_TstNPsdCdClrdSt_78A "Diagnostic Trouble Code Information Extended 78A : Test Not Passed Since Code Cleared Status";
BA_ "SignalType" SG_ 1930 DTCI_TstNPsdCdClrdSt_78A "BLN";
BA_ "VNSigAllNodes" SG_ 1930 DTCI_TstNPsdPwrUpSt_78A 1;
BA_ "PacketOrder" SG_ 1930 DTCI_TstNPsdPwrUpSt_78A 14;
BA_ "SignalLongName" SG_ 1930 DTCI_TstNPsdPwrUpSt_78A "Diagnostic Trouble Code Information Extended 78A : Test Not Passed Since Power Up Status";
BA_ "SignalType" SG_ 1930 DTCI_TstNPsdPwrUpSt_78A "BLN";
BA_ "VNSigAllNodes" SG_ 1930 DTCIUnused1_78A 1;
BA_ "PacketOrder" SG_ 1930 DTCIUnused1_78A 1;
BA_ "SignalLongName" SG_ 1930 DTCIUnused1_78A "Diagnostic Trouble Code Information Extended 78A : Unused 1";
BA_ "SignalType" SG_ 1930 DTCIUnused1_78A "BLN";
BA_ "VNSigAllNodes" SG_ 1930 DTCIUnused2_78A 1;
BA_ "PacketOrder" SG_ 1930 DTCIUnused2_78A 2;
BA_ "SignalLongName" SG_ 1930 DTCIUnused2_78A "Diagnostic Trouble Code Information Extended 78A : Unused 2";
BA_ "SignalType" SG_ 1930 DTCIUnused2_78A "BLN";
BA_ "VNSigAllNodes" SG_ 1930 DTCIUnused3_78A 1;
BA_ "PacketOrder" SG_ 1930 DTCIUnused3_78A 3;
BA_ "SignalLongName" SG_ 1930 DTCIUnused3_78A "Diagnostic Trouble Code Information Extended 78A : Unused 3";
BA_ "SignalType" SG_ 1930 DTCIUnused3_78A "BLN";
BA_ "VNSigAllNodes" SG_ 1930 DTCIUnused4_78A 1;
BA_ "PacketOrder" SG_ 1930 DTCIUnused4_78A 4;
BA_ "SignalLongName" SG_ 1930 DTCIUnused4_78A "Diagnostic Trouble Code Information Extended 78A : Unused 4";
BA_ "SignalType" SG_ 1930 DTCIUnused4_78A "BLN";
BA_ "VNSigAllNodes" SG_ 1930 DTCIUnused5_78A 1;
BA_ "PacketOrder" SG_ 1930 DTCIUnused5_78A 5;
BA_ "SignalLongName" SG_ 1930 DTCIUnused5_78A "Diagnostic Trouble Code Information Extended 78A : Unused 5";
BA_ "SignalType" SG_ 1930 DTCIUnused5_78A "BLN";
BA_ "VNSigAllNodes" SG_ 1930 DTCIUnused6_78A 1;
BA_ "PacketOrder" SG_ 1930 DTCIUnused6_78A 6;
BA_ "SignalLongName" SG_ 1930 DTCIUnused6_78A "Diagnostic Trouble Code Information Extended 78A : Unused 6";
BA_ "SignalType" SG_ 1930 DTCIUnused6_78A "BLN";
BA_ "VNSigAllNodes" SG_ 1930 DTCIUnused7_78A 1;
BA_ "PacketOrder" SG_ 1930 DTCIUnused7_78A 7;
BA_ "SignalLongName" SG_ 1930 DTCIUnused7_78A "Diagnostic Trouble Code Information Extended 78A : Unused 7";
BA_ "SignalType" SG_ 1930 DTCIUnused7_78A "BLN";
BA_ "VNSigAllNodes" SG_ 1930 DTCI_WrnIndRqdSt_78A 1;
BA_ "PacketOrder" SG_ 1930 DTCI_WrnIndRqdSt_78A 12;
BA_ "SignalLongName" SG_ 1930 DTCI_WrnIndRqdSt_78A "Diagnostic Trouble Code Information Extended 78A : Warning Indicator Requested Status";
BA_ "SignalType" SG_ 1930 DTCI_WrnIndRqdSt_78A "BLN";
BA_ "Prio" BO_ 1929 0;
BA_ "GenMsgSendType" BO_ 1929 0;
BA_ "GenMsgCycleTime" BO_ 1929 1000;
BA_ "MessageSubnet" BO_ 1929 2;
BA_ "VNSigAllNodes" SG_ 1929 DTCI_CodeSupported_789 1;
BA_ "PacketOrder" SG_ 1929 DTCI_CodeSupported_789 19;
BA_ "SignalLongName" SG_ 1929 DTCI_CodeSupported_789 "Diagnostic Trouble Code Information Extended 789 : Code Supported";
BA_ "SignalType" SG_ 1929 DTCI_CodeSupported_789 "BLN";
BA_ "VNSigAllNodes" SG_ 1929 DTCI_CurrentStatus_789 1;
BA_ "PacketOrder" SG_ 1929 DTCI_CurrentStatus_789 18;
BA_ "SignalLongName" SG_ 1929 DTCI_CurrentStatus_789 "Diagnostic Trouble Code Information Extended 789 : Current Status";
BA_ "SignalType" SG_ 1929 DTCI_CurrentStatus_789 "BLN";
BA_ "VNSigAllNodes" SG_ 1929 DTCI_DTCFailType_789 1;
BA_ "PacketOrder" SG_ 1929 DTCI_DTCFailType_789 11;
BA_ "SignalLongName" SG_ 1929 DTCI_DTCFailType_789 "Diagnostic Trouble Code Information Extended 789 : Diagnostic Trouble Code Failure Type";
BA_ "SignalType" SG_ 1929 DTCI_DTCFailType_789 "UNM";
BA_ "VNSigAllNodes" SG_ 1929 DTCI_DTCFaultType_789 1;
BA_ "PacketOrder" SG_ 1929 DTCI_DTCFaultType_789 20;
BA_ "SignalLongName" SG_ 1929 DTCI_DTCFaultType_789 "Diagnostic Trouble Code Information Extended 789 : Diagnostic Trouble Code Fault Type";
BA_ "SignalType" SG_ 1929 DTCI_DTCFaultType_789 "ENM";
BA_ "VNSigAllNodes" SG_ 1929 DTCI_DTCNumber_789 1;
BA_ "PacketOrder" SG_ 1929 DTCI_DTCNumber_789 10;
BA_ "SignalLongName" SG_ 1929 DTCI_DTCNumber_789 "Diagnostic Trouble Code Information Extended 789 : Diagnostic Trouble Code Number";
BA_ "SignalType" SG_ 1929 DTCI_DTCNumber_789 "UNM";
BA_ "VNSigAllNodes" SG_ 1929 DTCI_DTCSource_789 1;
BA_ "PacketOrder" SG_ 1929 DTCI_DTCSource_789 9;
BA_ "SignalLongName" SG_ 1929 DTCI_DTCSource_789 "Diagnostic Trouble Code Information Extended 789 : Diagnostic Trouble Code Source";
BA_ "SignalType" SG_ 1929 DTCI_DTCSource_789 "UNM";
BA_ "VNSigAllNodes" SG_ 1929 DTCI_DTCTriggered_789 1;
BA_ "PacketOrder" SG_ 1929 DTCI_DTCTriggered_789 8;
BA_ "SignalLongName" SG_ 1929 DTCI_DTCTriggered_789 "Diagnostic Trouble Code Information Extended 789 : Diagnostic Trouble Code Triggered";
BA_ "SignalType" SG_ 1929 DTCI_DTCTriggered_789 "BLN";
BA_ "VNSigAllNodes" SG_ 1929 DTCI_HistStat_789 1;
BA_ "PacketOrder" SG_ 1929 DTCI_HistStat_789 15;
BA_ "SignalLongName" SG_ 1929 DTCI_HistStat_789 "Diagnostic Trouble Code Information Extended 789 : History Status";
BA_ "SignalType" SG_ 1929 DTCI_HistStat_789 "BLN";
BA_ "VNSigAllNodes" SG_ 1929 DTCI_TstFldCdClrdStat_789 1;
BA_ "PacketOrder" SG_ 1929 DTCI_TstFldCdClrdStat_789 16;
BA_ "SignalLongName" SG_ 1929 DTCI_TstFldCdClrdStat_789 "Diagnostic Trouble Code Information Extended 789 : Test Failed Since Code Cleared Status";
BA_ "SignalType" SG_ 1929 DTCI_TstFldCdClrdStat_789 "BLN";
BA_ "VNSigAllNodes" SG_ 1929 DTCI_TstFldPwrUpSt_789 1;
BA_ "PacketOrder" SG_ 1929 DTCI_TstFldPwrUpSt_789 13;
BA_ "SignalLongName" SG_ 1929 DTCI_TstFldPwrUpSt_789 "Diagnostic Trouble Code Information Extended 789 : Test Failed Since Power Up Status";
BA_ "SignalType" SG_ 1929 DTCI_TstFldPwrUpSt_789 "BLN";
BA_ "VNSigAllNodes" SG_ 1929 DTCI_TstNPsdCdClrdSt_789 1;
BA_ "PacketOrder" SG_ 1929 DTCI_TstNPsdCdClrdSt_789 17;
BA_ "SignalLongName" SG_ 1929 DTCI_TstNPsdCdClrdSt_789 "Diagnostic Trouble Code Information Extended 789 : Test Not Passed Since Code Cleared Status";
BA_ "SignalType" SG_ 1929 DTCI_TstNPsdCdClrdSt_789 "BLN";
BA_ "VNSigAllNodes" SG_ 1929 DTCI_TstNPsdPwrUpSt_789 1;
BA_ "PacketOrder" SG_ 1929 DTCI_TstNPsdPwrUpSt_789 14;
BA_ "SignalLongName" SG_ 1929 DTCI_TstNPsdPwrUpSt_789 "Diagnostic Trouble Code Information Extended 789 : Test Not Passed Since Power Up Status";
BA_ "SignalType" SG_ 1929 DTCI_TstNPsdPwrUpSt_789 "BLN";
BA_ "VNSigAllNodes" SG_ 1929 DTCIUnused1_789 1;
BA_ "PacketOrder" SG_ 1929 DTCIUnused1_789 1;
BA_ "SignalLongName" SG_ 1929 DTCIUnused1_789 "Diagnostic Trouble Code Information Extended 789 : Unused 1";
BA_ "SignalType" SG_ 1929 DTCIUnused1_789 "BLN";
BA_ "VNSigAllNodes" SG_ 1929 DTCIUnused2_789 1;
BA_ "PacketOrder" SG_ 1929 DTCIUnused2_789 2;
BA_ "SignalLongName" SG_ 1929 DTCIUnused2_789 "Diagnostic Trouble Code Information Extended 789 : Unused 2";
BA_ "SignalType" SG_ 1929 DTCIUnused2_789 "BLN";
BA_ "VNSigAllNodes" SG_ 1929 DTCIUnused3_789 1;
BA_ "PacketOrder" SG_ 1929 DTCIUnused3_789 3;
BA_ "SignalLongName" SG_ 1929 DTCIUnused3_789 "Diagnostic Trouble Code Information Extended 789 : Unused 3";
BA_ "SignalType" SG_ 1929 DTCIUnused3_789 "BLN";
BA_ "VNSigAllNodes" SG_ 1929 DTCIUnused4_789 1;
BA_ "PacketOrder" SG_ 1929 DTCIUnused4_789 4;
BA_ "SignalLongName" SG_ 1929 DTCIUnused4_789 "Diagnostic Trouble Code Information Extended 789 : Unused 4";
BA_ "SignalType" SG_ 1929 DTCIUnused4_789 "BLN";
BA_ "VNSigAllNodes" SG_ 1929 DTCIUnused5_789 1;
BA_ "PacketOrder" SG_ 1929 DTCIUnused5_789 5;
BA_ "SignalLongName" SG_ 1929 DTCIUnused5_789 "Diagnostic Trouble Code Information Extended 789 : Unused 5";
BA_ "SignalType" SG_ 1929 DTCIUnused5_789 "BLN";
BA_ "VNSigAllNodes" SG_ 1929 DTCIUnused6_789 1;
BA_ "PacketOrder" SG_ 1929 DTCIUnused6_789 6;
BA_ "SignalLongName" SG_ 1929 DTCIUnused6_789 "Diagnostic Trouble Code Information Extended 789 : Unused 6";
BA_ "SignalType" SG_ 1929 DTCIUnused6_789 "BLN";
BA_ "VNSigAllNodes" SG_ 1929 DTCIUnused7_789 1;
BA_ "PacketOrder" SG_ 1929 DTCIUnused7_789 7;
BA_ "SignalLongName" SG_ 1929 DTCIUnused7_789 "Diagnostic Trouble Code Information Extended 789 : Unused 7";
BA_ "SignalType" SG_ 1929 DTCIUnused7_789 "BLN";
BA_ "VNSigAllNodes" SG_ 1929 DTCI_WrnIndRqdSt_789 1;
BA_ "PacketOrder" SG_ 1929 DTCI_WrnIndRqdSt_789 12;
BA_ "SignalLongName" SG_ 1929 DTCI_WrnIndRqdSt_789 "Diagnostic Trouble Code Information Extended 789 : Warning Indicator Requested Status";
BA_ "SignalType" SG_ 1929 DTCI_WrnIndRqdSt_789 "BLN";
BA_ "Prio" BO_ 1928 0;
BA_ "GenMsgSendType" BO_ 1928 0;
BA_ "GenMsgCycleTime" BO_ 1928 1000;
BA_ "MessageSubnet" BO_ 1928 2;
BA_ "VNSigAllNodes" SG_ 1928 DTCI_CodeSupported_788 1;
BA_ "PacketOrder" SG_ 1928 DTCI_CodeSupported_788 19;
BA_ "SignalLongName" SG_ 1928 DTCI_CodeSupported_788 "Diagnostic Trouble Code Information Extended 788 : Code Supported";
BA_ "SignalType" SG_ 1928 DTCI_CodeSupported_788 "BLN";
BA_ "VNSigAllNodes" SG_ 1928 DTCI_CurrentStatus_788 1;
BA_ "PacketOrder" SG_ 1928 DTCI_CurrentStatus_788 18;
BA_ "SignalLongName" SG_ 1928 DTCI_CurrentStatus_788 "Diagnostic Trouble Code Information Extended 788 : Current Status";
BA_ "SignalType" SG_ 1928 DTCI_CurrentStatus_788 "BLN";
BA_ "VNSigAllNodes" SG_ 1928 DTCI_DTCFailType_788 1;
BA_ "PacketOrder" SG_ 1928 DTCI_DTCFailType_788 11;
BA_ "SignalLongName" SG_ 1928 DTCI_DTCFailType_788 "Diagnostic Trouble Code Information Extended 788 : Diagnostic Trouble Code Failure Type";
BA_ "SignalType" SG_ 1928 DTCI_DTCFailType_788 "UNM";
BA_ "VNSigAllNodes" SG_ 1928 DTCI_DTCFaultType_788 1;
BA_ "PacketOrder" SG_ 1928 DTCI_DTCFaultType_788 20;
BA_ "SignalLongName" SG_ 1928 DTCI_DTCFaultType_788 "Diagnostic Trouble Code Information Extended 788 : Diagnostic Trouble Code Fault Type";
BA_ "SignalType" SG_ 1928 DTCI_DTCFaultType_788 "ENM";
BA_ "VNSigAllNodes" SG_ 1928 DTCI_DTCNumber_788 1;
BA_ "PacketOrder" SG_ 1928 DTCI_DTCNumber_788 10;
BA_ "SignalLongName" SG_ 1928 DTCI_DTCNumber_788 "Diagnostic Trouble Code Information Extended 788 : Diagnostic Trouble Code Number";
BA_ "SignalType" SG_ 1928 DTCI_DTCNumber_788 "UNM";
BA_ "VNSigAllNodes" SG_ 1928 DTCI_DTCSource_788 1;
BA_ "PacketOrder" SG_ 1928 DTCI_DTCSource_788 9;
BA_ "SignalLongName" SG_ 1928 DTCI_DTCSource_788 "Diagnostic Trouble Code Information Extended 788 : Diagnostic Trouble Code Source";
BA_ "SignalType" SG_ 1928 DTCI_DTCSource_788 "UNM";
BA_ "VNSigAllNodes" SG_ 1928 DTCI_DTCTriggered_788 1;
BA_ "PacketOrder" SG_ 1928 DTCI_DTCTriggered_788 8;
BA_ "SignalLongName" SG_ 1928 DTCI_DTCTriggered_788 "Diagnostic Trouble Code Information Extended 788 : Diagnostic Trouble Code Triggered";
BA_ "SignalType" SG_ 1928 DTCI_DTCTriggered_788 "BLN";
BA_ "VNSigAllNodes" SG_ 1928 DTCI_HistStat_788 1;
BA_ "PacketOrder" SG_ 1928 DTCI_HistStat_788 15;
BA_ "SignalLongName" SG_ 1928 DTCI_HistStat_788 "Diagnostic Trouble Code Information Extended 788 : History Status";
BA_ "SignalType" SG_ 1928 DTCI_HistStat_788 "BLN";
BA_ "VNSigAllNodes" SG_ 1928 DTCI_TstFldCdClrdStat_788 1;
BA_ "PacketOrder" SG_ 1928 DTCI_TstFldCdClrdStat_788 16;
BA_ "SignalLongName" SG_ 1928 DTCI_TstFldCdClrdStat_788 "Diagnostic Trouble Code Information Extended 788 : Test Failed Since Code Cleared Status";
BA_ "SignalType" SG_ 1928 DTCI_TstFldCdClrdStat_788 "BLN";
BA_ "VNSigAllNodes" SG_ 1928 DTCI_TstFldPwrUpSt_788 1;
BA_ "PacketOrder" SG_ 1928 DTCI_TstFldPwrUpSt_788 13;
BA_ "SignalLongName" SG_ 1928 DTCI_TstFldPwrUpSt_788 "Diagnostic Trouble Code Information Extended 788 : Test Failed Since Power Up Status";
BA_ "SignalType" SG_ 1928 DTCI_TstFldPwrUpSt_788 "BLN";
BA_ "VNSigAllNodes" SG_ 1928 DTCI_TstNPsdCdClrdSt_788 1;
BA_ "PacketOrder" SG_ 1928 DTCI_TstNPsdCdClrdSt_788 17;
BA_ "SignalLongName" SG_ 1928 DTCI_TstNPsdCdClrdSt_788 "Diagnostic Trouble Code Information Extended 788 : Test Not Passed Since Code Cleared Status";
BA_ "SignalType" SG_ 1928 DTCI_TstNPsdCdClrdSt_788 "BLN";
BA_ "VNSigAllNodes" SG_ 1928 DTCI_TstNPsdPwrUpSt_788 1;
BA_ "PacketOrder" SG_ 1928 DTCI_TstNPsdPwrUpSt_788 14;
BA_ "SignalLongName" SG_ 1928 DTCI_TstNPsdPwrUpSt_788 "Diagnostic Trouble Code Information Extended 788 : Test Not Passed Since Power Up Status";
BA_ "SignalType" SG_ 1928 DTCI_TstNPsdPwrUpSt_788 "BLN";
BA_ "VNSigAllNodes" SG_ 1928 DTCIUnused1_788 1;
BA_ "PacketOrder" SG_ 1928 DTCIUnused1_788 1;
BA_ "SignalLongName" SG_ 1928 DTCIUnused1_788 "Diagnostic Trouble Code Information Extended 788 : Unused 1";
BA_ "SignalType" SG_ 1928 DTCIUnused1_788 "BLN";
BA_ "VNSigAllNodes" SG_ 1928 DTCIUnused2_788 1;
BA_ "PacketOrder" SG_ 1928 DTCIUnused2_788 2;
BA_ "SignalLongName" SG_ 1928 DTCIUnused2_788 "Diagnostic Trouble Code Information Extended 788 : Unused 2";
BA_ "SignalType" SG_ 1928 DTCIUnused2_788 "BLN";
BA_ "VNSigAllNodes" SG_ 1928 DTCIUnused3_788 1;
BA_ "PacketOrder" SG_ 1928 DTCIUnused3_788 3;
BA_ "SignalLongName" SG_ 1928 DTCIUnused3_788 "Diagnostic Trouble Code Information Extended 788 : Unused 3";
BA_ "SignalType" SG_ 1928 DTCIUnused3_788 "BLN";
BA_ "VNSigAllNodes" SG_ 1928 DTCIUnused4_788 1;
BA_ "PacketOrder" SG_ 1928 DTCIUnused4_788 4;
BA_ "SignalLongName" SG_ 1928 DTCIUnused4_788 "Diagnostic Trouble Code Information Extended 788 : Unused 4";
BA_ "SignalType" SG_ 1928 DTCIUnused4_788 "BLN";
BA_ "VNSigAllNodes" SG_ 1928 DTCIUnused5_788 1;
BA_ "PacketOrder" SG_ 1928 DTCIUnused5_788 5;
BA_ "SignalLongName" SG_ 1928 DTCIUnused5_788 "Diagnostic Trouble Code Information Extended 788 : Unused 5";
BA_ "SignalType" SG_ 1928 DTCIUnused5_788 "BLN";
BA_ "VNSigAllNodes" SG_ 1928 DTCIUnused6_788 1;
BA_ "PacketOrder" SG_ 1928 DTCIUnused6_788 6;
BA_ "SignalLongName" SG_ 1928 DTCIUnused6_788 "Diagnostic Trouble Code Information Extended 788 : Unused 6";
BA_ "SignalType" SG_ 1928 DTCIUnused6_788 "BLN";
BA_ "VNSigAllNodes" SG_ 1928 DTCIUnused7_788 1;
BA_ "PacketOrder" SG_ 1928 DTCIUnused7_788 7;
BA_ "SignalLongName" SG_ 1928 DTCIUnused7_788 "Diagnostic Trouble Code Information Extended 788 : Unused 7";
BA_ "SignalType" SG_ 1928 DTCIUnused7_788 "BLN";
BA_ "VNSigAllNodes" SG_ 1928 DTCI_WrnIndRqdSt_788 1;
BA_ "PacketOrder" SG_ 1928 DTCI_WrnIndRqdSt_788 12;
BA_ "SignalLongName" SG_ 1928 DTCI_WrnIndRqdSt_788 "Diagnostic Trouble Code Information Extended 788 : Warning Indicator Requested Status";
BA_ "SignalType" SG_ 1928 DTCI_WrnIndRqdSt_788 "BLN";
BA_ "Prio" BO_ 1927 0;
BA_ "GenMsgSendType" BO_ 1927 0;
BA_ "GenMsgCycleTime" BO_ 1927 1000;
BA_ "MessageSubnet" BO_ 1927 2;
BA_ "VNSigAllNodes" SG_ 1927 DTCI_CodeSupported_787 1;
BA_ "PacketOrder" SG_ 1927 DTCI_CodeSupported_787 19;
BA_ "SignalLongName" SG_ 1927 DTCI_CodeSupported_787 "Diagnostic Trouble Code Information Extended 787 : Code Supported";
BA_ "SignalType" SG_ 1927 DTCI_CodeSupported_787 "BLN";
BA_ "VNSigAllNodes" SG_ 1927 DTCI_CurrentStatus_787 1;
BA_ "PacketOrder" SG_ 1927 DTCI_CurrentStatus_787 18;
BA_ "SignalLongName" SG_ 1927 DTCI_CurrentStatus_787 "Diagnostic Trouble Code Information Extended 787 : Current Status";
BA_ "SignalType" SG_ 1927 DTCI_CurrentStatus_787 "BLN";
BA_ "VNSigAllNodes" SG_ 1927 DTCI_DTCFailType_787 1;
BA_ "PacketOrder" SG_ 1927 DTCI_DTCFailType_787 11;
BA_ "SignalLongName" SG_ 1927 DTCI_DTCFailType_787 "Diagnostic Trouble Code Information Extended 787 : Diagnostic Trouble Code Failure Type";
BA_ "SignalType" SG_ 1927 DTCI_DTCFailType_787 "UNM";
BA_ "VNSigAllNodes" SG_ 1927 DTCI_DTCFaultType_787 1;
BA_ "PacketOrder" SG_ 1927 DTCI_DTCFaultType_787 20;
BA_ "SignalLongName" SG_ 1927 DTCI_DTCFaultType_787 "Diagnostic Trouble Code Information Extended 787 : Diagnostic Trouble Code Fault Type";
BA_ "SignalType" SG_ 1927 DTCI_DTCFaultType_787 "ENM";
BA_ "VNSigAllNodes" SG_ 1927 DTCI_DTCNumber_787 1;
BA_ "PacketOrder" SG_ 1927 DTCI_DTCNumber_787 10;
BA_ "SignalLongName" SG_ 1927 DTCI_DTCNumber_787 "Diagnostic Trouble Code Information Extended 787 : Diagnostic Trouble Code Number";
BA_ "SignalType" SG_ 1927 DTCI_DTCNumber_787 "UNM";
BA_ "VNSigAllNodes" SG_ 1927 DTCI_DTCSource_787 1;
BA_ "PacketOrder" SG_ 1927 DTCI_DTCSource_787 9;
BA_ "SignalLongName" SG_ 1927 DTCI_DTCSource_787 "Diagnostic Trouble Code Information Extended 787 : Diagnostic Trouble Code Source";
BA_ "SignalType" SG_ 1927 DTCI_DTCSource_787 "UNM";
BA_ "VNSigAllNodes" SG_ 1927 DTCI_DTCTriggered_787 1;
BA_ "PacketOrder" SG_ 1927 DTCI_DTCTriggered_787 8;
BA_ "SignalLongName" SG_ 1927 DTCI_DTCTriggered_787 "Diagnostic Trouble Code Information Extended 787 : Diagnostic Trouble Code Triggered";
BA_ "SignalType" SG_ 1927 DTCI_DTCTriggered_787 "BLN";
BA_ "VNSigAllNodes" SG_ 1927 DTCI_HistStat_787 1;
BA_ "PacketOrder" SG_ 1927 DTCI_HistStat_787 15;
BA_ "SignalLongName" SG_ 1927 DTCI_HistStat_787 "Diagnostic Trouble Code Information Extended 787 : History Status";
BA_ "SignalType" SG_ 1927 DTCI_HistStat_787 "BLN";
BA_ "VNSigAllNodes" SG_ 1927 DTCI_TstFldCdClrdStat_787 1;
BA_ "PacketOrder" SG_ 1927 DTCI_TstFldCdClrdStat_787 16;
BA_ "SignalLongName" SG_ 1927 DTCI_TstFldCdClrdStat_787 "Diagnostic Trouble Code Information Extended 787 : Test Failed Since Code Cleared Status";
BA_ "SignalType" SG_ 1927 DTCI_TstFldCdClrdStat_787 "BLN";
BA_ "VNSigAllNodes" SG_ 1927 DTCI_TstFldPwrUpSt_787 1;
BA_ "PacketOrder" SG_ 1927 DTCI_TstFldPwrUpSt_787 13;
BA_ "SignalLongName" SG_ 1927 DTCI_TstFldPwrUpSt_787 "Diagnostic Trouble Code Information Extended 787 : Test Failed Since Power Up Status";
BA_ "SignalType" SG_ 1927 DTCI_TstFldPwrUpSt_787 "BLN";
BA_ "VNSigAllNodes" SG_ 1927 DTCI_TstNPsdCdClrdSt_787 1;
BA_ "PacketOrder" SG_ 1927 DTCI_TstNPsdCdClrdSt_787 17;
BA_ "SignalLongName" SG_ 1927 DTCI_TstNPsdCdClrdSt_787 "Diagnostic Trouble Code Information Extended 787 : Test Not Passed Since Code Cleared Status";
BA_ "SignalType" SG_ 1927 DTCI_TstNPsdCdClrdSt_787 "BLN";
BA_ "VNSigAllNodes" SG_ 1927 DTCI_TstNPsdPwrUpSt_787 1;
BA_ "PacketOrder" SG_ 1927 DTCI_TstNPsdPwrUpSt_787 14;
BA_ "SignalLongName" SG_ 1927 DTCI_TstNPsdPwrUpSt_787 "Diagnostic Trouble Code Information Extended 787 : Test Not Passed Since Power Up Status";
BA_ "SignalType" SG_ 1927 DTCI_TstNPsdPwrUpSt_787 "BLN";
BA_ "VNSigAllNodes" SG_ 1927 DTCIUnused1_787 1;
BA_ "PacketOrder" SG_ 1927 DTCIUnused1_787 1;
BA_ "SignalLongName" SG_ 1927 DTCIUnused1_787 "Diagnostic Trouble Code Information Extended 787 : Unused 1";
BA_ "SignalType" SG_ 1927 DTCIUnused1_787 "BLN";
BA_ "VNSigAllNodes" SG_ 1927 DTCIUnused2_787 1;
BA_ "PacketOrder" SG_ 1927 DTCIUnused2_787 2;
BA_ "SignalLongName" SG_ 1927 DTCIUnused2_787 "Diagnostic Trouble Code Information Extended 787 : Unused 2";
BA_ "SignalType" SG_ 1927 DTCIUnused2_787 "BLN";
BA_ "VNSigAllNodes" SG_ 1927 DTCIUnused3_787 1;
BA_ "PacketOrder" SG_ 1927 DTCIUnused3_787 3;
BA_ "SignalLongName" SG_ 1927 DTCIUnused3_787 "Diagnostic Trouble Code Information Extended 787 : Unused 3";
BA_ "SignalType" SG_ 1927 DTCIUnused3_787 "BLN";
BA_ "VNSigAllNodes" SG_ 1927 DTCIUnused4_787 1;
BA_ "PacketOrder" SG_ 1927 DTCIUnused4_787 4;
BA_ "SignalLongName" SG_ 1927 DTCIUnused4_787 "Diagnostic Trouble Code Information Extended 787 : Unused 4";
BA_ "SignalType" SG_ 1927 DTCIUnused4_787 "BLN";
BA_ "VNSigAllNodes" SG_ 1927 DTCIUnused5_787 1;
BA_ "PacketOrder" SG_ 1927 DTCIUnused5_787 5;
BA_ "SignalLongName" SG_ 1927 DTCIUnused5_787 "Diagnostic Trouble Code Information Extended 787 : Unused 5";
BA_ "SignalType" SG_ 1927 DTCIUnused5_787 "BLN";
BA_ "VNSigAllNodes" SG_ 1927 DTCIUnused6_787 1;
BA_ "PacketOrder" SG_ 1927 DTCIUnused6_787 6;
BA_ "SignalLongName" SG_ 1927 DTCIUnused6_787 "Diagnostic Trouble Code Information Extended 787 : Unused 6";
BA_ "SignalType" SG_ 1927 DTCIUnused6_787 "BLN";
BA_ "VNSigAllNodes" SG_ 1927 DTCIUnused7_787 1;
BA_ "PacketOrder" SG_ 1927 DTCIUnused7_787 7;
BA_ "SignalLongName" SG_ 1927 DTCIUnused7_787 "Diagnostic Trouble Code Information Extended 787 : Unused 7";
BA_ "SignalType" SG_ 1927 DTCIUnused7_787 "BLN";
BA_ "VNSigAllNodes" SG_ 1927 DTCI_WrnIndRqdSt_787 1;
BA_ "PacketOrder" SG_ 1927 DTCI_WrnIndRqdSt_787 12;
BA_ "SignalLongName" SG_ 1927 DTCI_WrnIndRqdSt_787 "Diagnostic Trouble Code Information Extended 787 : Warning Indicator Requested Status";
BA_ "SignalType" SG_ 1927 DTCI_WrnIndRqdSt_787 "BLN";
BA_ "Prio" BO_ 1926 0;
BA_ "GenMsgSendType" BO_ 1926 0;
BA_ "GenMsgCycleTime" BO_ 1926 1000;
BA_ "MessageSubnet" BO_ 1926 2;
BA_ "VNSigAllNodes" SG_ 1926 DTCI_CodeSupported_786 1;
BA_ "PacketOrder" SG_ 1926 DTCI_CodeSupported_786 19;
BA_ "SignalLongName" SG_ 1926 DTCI_CodeSupported_786 "Diagnostic Trouble Code Information Extended 786 : Code Supported";
BA_ "SignalType" SG_ 1926 DTCI_CodeSupported_786 "BLN";
BA_ "VNSigAllNodes" SG_ 1926 DTCI_CurrentStatus_786 1;
BA_ "PacketOrder" SG_ 1926 DTCI_CurrentStatus_786 18;
BA_ "SignalLongName" SG_ 1926 DTCI_CurrentStatus_786 "Diagnostic Trouble Code Information Extended 786 : Current Status";
BA_ "SignalType" SG_ 1926 DTCI_CurrentStatus_786 "BLN";
BA_ "VNSigAllNodes" SG_ 1926 DTCI_DTCFailType_786 1;
BA_ "PacketOrder" SG_ 1926 DTCI_DTCFailType_786 11;
BA_ "SignalLongName" SG_ 1926 DTCI_DTCFailType_786 "Diagnostic Trouble Code Information Extended 786 : Diagnostic Trouble Code Failure Type";
BA_ "SignalType" SG_ 1926 DTCI_DTCFailType_786 "UNM";
BA_ "VNSigAllNodes" SG_ 1926 DTCI_DTCFaultType_786 1;
BA_ "PacketOrder" SG_ 1926 DTCI_DTCFaultType_786 20;
BA_ "SignalLongName" SG_ 1926 DTCI_DTCFaultType_786 "Diagnostic Trouble Code Information Extended 786 : Diagnostic Trouble Code Fault Type";
BA_ "SignalType" SG_ 1926 DTCI_DTCFaultType_786 "ENM";
BA_ "VNSigAllNodes" SG_ 1926 DTCI_DTCNumber_786 1;
BA_ "PacketOrder" SG_ 1926 DTCI_DTCNumber_786 10;
BA_ "SignalLongName" SG_ 1926 DTCI_DTCNumber_786 "Diagnostic Trouble Code Information Extended 786 : Diagnostic Trouble Code Number";
BA_ "SignalType" SG_ 1926 DTCI_DTCNumber_786 "UNM";
BA_ "VNSigAllNodes" SG_ 1926 DTCI_DTCSource_786 1;
BA_ "PacketOrder" SG_ 1926 DTCI_DTCSource_786 9;
BA_ "SignalLongName" SG_ 1926 DTCI_DTCSource_786 "Diagnostic Trouble Code Information Extended 786 : Diagnostic Trouble Code Source";
BA_ "SignalType" SG_ 1926 DTCI_DTCSource_786 "UNM";
BA_ "VNSigAllNodes" SG_ 1926 DTCI_DTCTriggered_786 1;
BA_ "PacketOrder" SG_ 1926 DTCI_DTCTriggered_786 8;
BA_ "SignalLongName" SG_ 1926 DTCI_DTCTriggered_786 "Diagnostic Trouble Code Information Extended 786 : Diagnostic Trouble Code Triggered";
BA_ "SignalType" SG_ 1926 DTCI_DTCTriggered_786 "BLN";
BA_ "VNSigAllNodes" SG_ 1926 DTCI_HistStat_786 1;
BA_ "PacketOrder" SG_ 1926 DTCI_HistStat_786 15;
BA_ "SignalLongName" SG_ 1926 DTCI_HistStat_786 "Diagnostic Trouble Code Information Extended 786 : History Status";
BA_ "SignalType" SG_ 1926 DTCI_HistStat_786 "BLN";
BA_ "VNSigAllNodes" SG_ 1926 DTCI_TstFldCdClrdStat_786 1;
BA_ "PacketOrder" SG_ 1926 DTCI_TstFldCdClrdStat_786 16;
BA_ "SignalLongName" SG_ 1926 DTCI_TstFldCdClrdStat_786 "Diagnostic Trouble Code Information Extended 786 : Test Failed Since Code Cleared Status";
BA_ "SignalType" SG_ 1926 DTCI_TstFldCdClrdStat_786 "BLN";
BA_ "VNSigAllNodes" SG_ 1926 DTCI_TstFldPwrUpSt_786 1;
BA_ "PacketOrder" SG_ 1926 DTCI_TstFldPwrUpSt_786 13;
BA_ "SignalLongName" SG_ 1926 DTCI_TstFldPwrUpSt_786 "Diagnostic Trouble Code Information Extended 786 : Test Failed Since Power Up Status";
BA_ "SignalType" SG_ 1926 DTCI_TstFldPwrUpSt_786 "BLN";
BA_ "VNSigAllNodes" SG_ 1926 DTCI_TstNPsdCdClrdSt_786 1;
BA_ "PacketOrder" SG_ 1926 DTCI_TstNPsdCdClrdSt_786 17;
BA_ "SignalLongName" SG_ 1926 DTCI_TstNPsdCdClrdSt_786 "Diagnostic Trouble Code Information Extended 786 : Test Not Passed Since Code Cleared Status";
BA_ "SignalType" SG_ 1926 DTCI_TstNPsdCdClrdSt_786 "BLN";
BA_ "VNSigAllNodes" SG_ 1926 DTCI_TstNPsdPwrUpSt_786 1;
BA_ "PacketOrder" SG_ 1926 DTCI_TstNPsdPwrUpSt_786 14;
BA_ "SignalLongName" SG_ 1926 DTCI_TstNPsdPwrUpSt_786 "Diagnostic Trouble Code Information Extended 786 : Test Not Passed Since Power Up Status";
BA_ "SignalType" SG_ 1926 DTCI_TstNPsdPwrUpSt_786 "BLN";
BA_ "VNSigAllNodes" SG_ 1926 DTCIUnused1_786 1;
BA_ "PacketOrder" SG_ 1926 DTCIUnused1_786 1;
BA_ "SignalLongName" SG_ 1926 DTCIUnused1_786 "Diagnostic Trouble Code Information Extended 786 : Unused 1";
BA_ "SignalType" SG_ 1926 DTCIUnused1_786 "BLN";
BA_ "VNSigAllNodes" SG_ 1926 DTCIUnused2_786 1;
BA_ "PacketOrder" SG_ 1926 DTCIUnused2_786 2;
BA_ "SignalLongName" SG_ 1926 DTCIUnused2_786 "Diagnostic Trouble Code Information Extended 786 : Unused 2";
BA_ "SignalType" SG_ 1926 DTCIUnused2_786 "BLN";
BA_ "VNSigAllNodes" SG_ 1926 DTCIUnused3_786 1;
BA_ "PacketOrder" SG_ 1926 DTCIUnused3_786 3;
BA_ "SignalLongName" SG_ 1926 DTCIUnused3_786 "Diagnostic Trouble Code Information Extended 786 : Unused 3";
BA_ "SignalType" SG_ 1926 DTCIUnused3_786 "BLN";
BA_ "VNSigAllNodes" SG_ 1926 DTCIUnused4_786 1;
BA_ "PacketOrder" SG_ 1926 DTCIUnused4_786 4;
BA_ "SignalLongName" SG_ 1926 DTCIUnused4_786 "Diagnostic Trouble Code Information Extended 786 : Unused 4";
BA_ "SignalType" SG_ 1926 DTCIUnused4_786 "BLN";
BA_ "VNSigAllNodes" SG_ 1926 DTCIUnused5_786 1;
BA_ "PacketOrder" SG_ 1926 DTCIUnused5_786 5;
BA_ "SignalLongName" SG_ 1926 DTCIUnused5_786 "Diagnostic Trouble Code Information Extended 786 : Unused 5";
BA_ "SignalType" SG_ 1926 DTCIUnused5_786 "BLN";
BA_ "VNSigAllNodes" SG_ 1926 DTCIUnused6_786 1;
BA_ "PacketOrder" SG_ 1926 DTCIUnused6_786 6;
BA_ "SignalLongName" SG_ 1926 DTCIUnused6_786 "Diagnostic Trouble Code Information Extended 786 : Unused 6";
BA_ "SignalType" SG_ 1926 DTCIUnused6_786 "BLN";
BA_ "VNSigAllNodes" SG_ 1926 DTCIUnused7_786 1;
BA_ "PacketOrder" SG_ 1926 DTCIUnused7_786 7;
BA_ "SignalLongName" SG_ 1926 DTCIUnused7_786 "Diagnostic Trouble Code Information Extended 786 : Unused 7";
BA_ "SignalType" SG_ 1926 DTCIUnused7_786 "BLN";
BA_ "VNSigAllNodes" SG_ 1926 DTCI_WrnIndRqdSt_786 1;
BA_ "PacketOrder" SG_ 1926 DTCI_WrnIndRqdSt_786 12;
BA_ "SignalLongName" SG_ 1926 DTCI_WrnIndRqdSt_786 "Diagnostic Trouble Code Information Extended 786 : Warning Indicator Requested Status";
BA_ "SignalType" SG_ 1926 DTCI_WrnIndRqdSt_786 "BLN";
BA_ "Prio" BO_ 1925 0;
BA_ "GenMsgSendType" BO_ 1925 0;
BA_ "GenMsgCycleTime" BO_ 1925 1000;
BA_ "MessageSubnet" BO_ 1925 2;
BA_ "VNSigAllNodes" SG_ 1925 DTCI_CodeSupported_785 1;
BA_ "PacketOrder" SG_ 1925 DTCI_CodeSupported_785 19;
BA_ "SignalLongName" SG_ 1925 DTCI_CodeSupported_785 "Diagnostic Trouble Code Information Extended 785 : Code Supported";
BA_ "SignalType" SG_ 1925 DTCI_CodeSupported_785 "BLN";
BA_ "VNSigAllNodes" SG_ 1925 DTCI_CurrentStatus_785 1;
BA_ "PacketOrder" SG_ 1925 DTCI_CurrentStatus_785 18;
BA_ "SignalLongName" SG_ 1925 DTCI_CurrentStatus_785 "Diagnostic Trouble Code Information Extended 785 : Current Status";
BA_ "SignalType" SG_ 1925 DTCI_CurrentStatus_785 "BLN";
BA_ "VNSigAllNodes" SG_ 1925 DTCI_DTCFailType_785 1;
BA_ "PacketOrder" SG_ 1925 DTCI_DTCFailType_785 11;
BA_ "SignalLongName" SG_ 1925 DTCI_DTCFailType_785 "Diagnostic Trouble Code Information Extended 785 : Diagnostic Trouble Code Failure Type";
BA_ "SignalType" SG_ 1925 DTCI_DTCFailType_785 "UNM";
BA_ "VNSigAllNodes" SG_ 1925 DTCI_DTCFaultType_785 1;
BA_ "PacketOrder" SG_ 1925 DTCI_DTCFaultType_785 20;
BA_ "SignalLongName" SG_ 1925 DTCI_DTCFaultType_785 "Diagnostic Trouble Code Information Extended 785 : Diagnostic Trouble Code Fault Type";
BA_ "SignalType" SG_ 1925 DTCI_DTCFaultType_785 "ENM";
BA_ "VNSigAllNodes" SG_ 1925 DTCI_DTCNumber_785 1;
BA_ "PacketOrder" SG_ 1925 DTCI_DTCNumber_785 10;
BA_ "SignalLongName" SG_ 1925 DTCI_DTCNumber_785 "Diagnostic Trouble Code Information Extended 785 : Diagnostic Trouble Code Number";
BA_ "SignalType" SG_ 1925 DTCI_DTCNumber_785 "UNM";
BA_ "VNSigAllNodes" SG_ 1925 DTCI_DTCSource_785 1;
BA_ "PacketOrder" SG_ 1925 DTCI_DTCSource_785 9;
BA_ "SignalLongName" SG_ 1925 DTCI_DTCSource_785 "Diagnostic Trouble Code Information Extended 785 : Diagnostic Trouble Code Source";
BA_ "SignalType" SG_ 1925 DTCI_DTCSource_785 "UNM";
BA_ "VNSigAllNodes" SG_ 1925 DTCI_DTCTriggered_785 1;
BA_ "PacketOrder" SG_ 1925 DTCI_DTCTriggered_785 8;
BA_ "SignalLongName" SG_ 1925 DTCI_DTCTriggered_785 "Diagnostic Trouble Code Information Extended 785 : Diagnostic Trouble Code Triggered";
BA_ "SignalType" SG_ 1925 DTCI_DTCTriggered_785 "BLN";
BA_ "VNSigAllNodes" SG_ 1925 DTCI_HistStat_785 1;
BA_ "PacketOrder" SG_ 1925 DTCI_HistStat_785 15;
BA_ "SignalLongName" SG_ 1925 DTCI_HistStat_785 "Diagnostic Trouble Code Information Extended 785 : History Status";
BA_ "SignalType" SG_ 1925 DTCI_HistStat_785 "BLN";
BA_ "VNSigAllNodes" SG_ 1925 DTCI_TstFldCdClrdStat_785 1;
BA_ "PacketOrder" SG_ 1925 DTCI_TstFldCdClrdStat_785 16;
BA_ "SignalLongName" SG_ 1925 DTCI_TstFldCdClrdStat_785 "Diagnostic Trouble Code Information Extended 785 : Test Failed Since Code Cleared Status";
BA_ "SignalType" SG_ 1925 DTCI_TstFldCdClrdStat_785 "BLN";
BA_ "VNSigAllNodes" SG_ 1925 DTCI_TstFldPwrUpSt_785 1;
BA_ "PacketOrder" SG_ 1925 DTCI_TstFldPwrUpSt_785 13;
BA_ "SignalLongName" SG_ 1925 DTCI_TstFldPwrUpSt_785 "Diagnostic Trouble Code Information Extended 785 : Test Failed Since Power Up Status";
BA_ "SignalType" SG_ 1925 DTCI_TstFldPwrUpSt_785 "BLN";
BA_ "VNSigAllNodes" SG_ 1925 DTCI_TstNPsdCdClrdSt_785 1;
BA_ "PacketOrder" SG_ 1925 DTCI_TstNPsdCdClrdSt_785 17;
BA_ "SignalLongName" SG_ 1925 DTCI_TstNPsdCdClrdSt_785 "Diagnostic Trouble Code Information Extended 785 : Test Not Passed Since Code Cleared Status";
BA_ "SignalType" SG_ 1925 DTCI_TstNPsdCdClrdSt_785 "BLN";
BA_ "VNSigAllNodes" SG_ 1925 DTCI_TstNPsdPwrUpSt_785 1;
BA_ "PacketOrder" SG_ 1925 DTCI_TstNPsdPwrUpSt_785 14;
BA_ "SignalLongName" SG_ 1925 DTCI_TstNPsdPwrUpSt_785 "Diagnostic Trouble Code Information Extended 785 : Test Not Passed Since Power Up Status";
BA_ "SignalType" SG_ 1925 DTCI_TstNPsdPwrUpSt_785 "BLN";
BA_ "VNSigAllNodes" SG_ 1925 DTCIUnused1_785 1;
BA_ "PacketOrder" SG_ 1925 DTCIUnused1_785 1;
BA_ "SignalLongName" SG_ 1925 DTCIUnused1_785 "Diagnostic Trouble Code Information Extended 785 : Unused 1";
BA_ "SignalType" SG_ 1925 DTCIUnused1_785 "BLN";
BA_ "VNSigAllNodes" SG_ 1925 DTCIUnused2_785 1;
BA_ "PacketOrder" SG_ 1925 DTCIUnused2_785 2;
BA_ "SignalLongName" SG_ 1925 DTCIUnused2_785 "Diagnostic Trouble Code Information Extended 785 : Unused 2";
BA_ "SignalType" SG_ 1925 DTCIUnused2_785 "BLN";
BA_ "VNSigAllNodes" SG_ 1925 DTCIUnused3_785 1;
BA_ "PacketOrder" SG_ 1925 DTCIUnused3_785 3;
BA_ "SignalLongName" SG_ 1925 DTCIUnused3_785 "Diagnostic Trouble Code Information Extended 785 : Unused 3";
BA_ "SignalType" SG_ 1925 DTCIUnused3_785 "BLN";
BA_ "VNSigAllNodes" SG_ 1925 DTCIUnused4_785 1;
BA_ "PacketOrder" SG_ 1925 DTCIUnused4_785 4;
BA_ "SignalLongName" SG_ 1925 DTCIUnused4_785 "Diagnostic Trouble Code Information Extended 785 : Unused 4";
BA_ "SignalType" SG_ 1925 DTCIUnused4_785 "BLN";
BA_ "VNSigAllNodes" SG_ 1925 DTCIUnused5_785 1;
BA_ "PacketOrder" SG_ 1925 DTCIUnused5_785 5;
BA_ "SignalLongName" SG_ 1925 DTCIUnused5_785 "Diagnostic Trouble Code Information Extended 785 : Unused 5";
BA_ "SignalType" SG_ 1925 DTCIUnused5_785 "BLN";
BA_ "VNSigAllNodes" SG_ 1925 DTCIUnused6_785 1;
BA_ "PacketOrder" SG_ 1925 DTCIUnused6_785 6;
BA_ "SignalLongName" SG_ 1925 DTCIUnused6_785 "Diagnostic Trouble Code Information Extended 785 : Unused 6";
BA_ "SignalType" SG_ 1925 DTCIUnused6_785 "BLN";
BA_ "VNSigAllNodes" SG_ 1925 DTCIUnused7_785 1;
BA_ "PacketOrder" SG_ 1925 DTCIUnused7_785 7;
BA_ "SignalLongName" SG_ 1925 DTCIUnused7_785 "Diagnostic Trouble Code Information Extended 785 : Unused 7";
BA_ "SignalType" SG_ 1925 DTCIUnused7_785 "BLN";
BA_ "VNSigAllNodes" SG_ 1925 DTCI_WrnIndRqdSt_785 1;
BA_ "PacketOrder" SG_ 1925 DTCI_WrnIndRqdSt_785 12;
BA_ "SignalLongName" SG_ 1925 DTCI_WrnIndRqdSt_785 "Diagnostic Trouble Code Information Extended 785 : Warning Indicator Requested Status";
BA_ "SignalType" SG_ 1925 DTCI_WrnIndRqdSt_785 "BLN";
